VERSION ""

NS_ :

BS_:

BU_: RLPSU DPSU APSU PSB SHVU_RR vHS_B2 FCS EMCU SLB RCM CGW_CCU vDummy_HS_B ATS RLHV PFSU SGU ALBCU DSAU SWRC SHVU_FR RCS RRPSU BLTN_CAM SCM DLBCU OHCL RWPC RRHV WPC HOD ASAU

BO_ 1041 ICU_02_200ms: 8 CGW_CCU
 SG_ ICU_Crc2Val : 0|8@1+ (1,0) [0|0] ""  Vector__XXX
 SG_ ICU_MtGearPosRSta : 10|2@1+ (1,0) [0|0] ""  BLTN_CAM
 SG_ ICU_AlvCnt2Val : 12|4@1+ (1,0) [0|0] ""  Vector__XXX
 SG_ DoorLock_AsstDrUnLkSta : 22|2@1+ (1,0) [0|0] ""  Vector__XXX
 SG_ Warn_DrvDrSwSta : 24|2@1+ (1,0) [0|0] ""  WPC,RWPC,DPSU,BLTN_CAM
 SG_ DoorLock_DrvKeyUnLkSwSta : 26|2@1+ (1,0) [0|0] ""  Vector__XXX
 SG_ DoorLock_RrLftDrUnLkSta : 28|2@1+ (1,0) [0|0] ""  Vector__XXX
 SG_ DoorLock_RrRtDrUnLkSta : 30|2@1+ (1,0) [0|0] ""  Vector__XXX
 SG_ Warn_AsstDrSwSta : 34|2@1+ (1,0) [0|0] ""  WPC,RWPC,APSU,RLPSU,BLTN_CAM,ALBCU
 SG_ Warn_AsstStBltSwSta : 36|2@1+ (1,0) [0|0] ""  PSB,APSU,RLPSU,ASAU,ALBCU
 SG_ Warn_BrkFldSwSta : 38|2@1+ (1,0) [0|0] ""  Vector__XXX
 SG_ DoorLock_DrvKeyLkSwSta : 40|2@1+ (1,0) [0|0] ""  Vector__XXX
 SG_ Warn_DrvStBltSwSta : 42|2@1+ (1,0) [0|0] ""  PSB,DPSU,DLBCU,ATS,DSAU,ASAU
 SG_ Warn_HoodSwSta : 44|2@1+ (1,0) [0|0] ""  BLTN_CAM
 SG_ Warn_PassStOccSta : 46|2@1+ (1,0) [0|0] ""  APSU
 SG_ Warn_PrkngBrkSwSta : 48|2@1+ (1,0) [0|0] ""  APSU,RLHV,RRHV,PFSU,RRPSU,RLPSU
 SG_ Warn_RrCtrStBltSwSta : 50|2@1+ (1,0) [0|0] ""  PSB
 SG_ Warn_RrLftDrSwSta : 52|2@1+ (1,0) [0|0] ""  WPC,RWPC,APSU,RLHV,RLPSU,BLTN_CAM
 SG_ Warn_RrLftStBltSwSta : 54|2@1+ (1,0) [0|0] ""  PSB,APSU,DPSU
 SG_ Warn_RrRtDrSwSta : 56|2@1+ (1,0) [0|0] ""  WPC,RWPC,APSU,RRHV,RRPSU,RLPSU,BLTN_CAM
 SG_ Warn_RrRtStBltSwSta : 58|2@1+ (1,0) [0|0] ""  PSB,APSU,DPSU,RRPSU
 SG_ Warn_HoodSwMemorySta : 60|2@1+ (1,0) [0|0] ""  Vector__XXX
 SG_ Warn_WshrFldSwSta : 62|2@1+ (1,0) [0|0] ""  Vector__XXX
 SG_ ICU_Haptic_OPT : 8|2@1+ (1,0) [0|0] ""  Vector__XXX

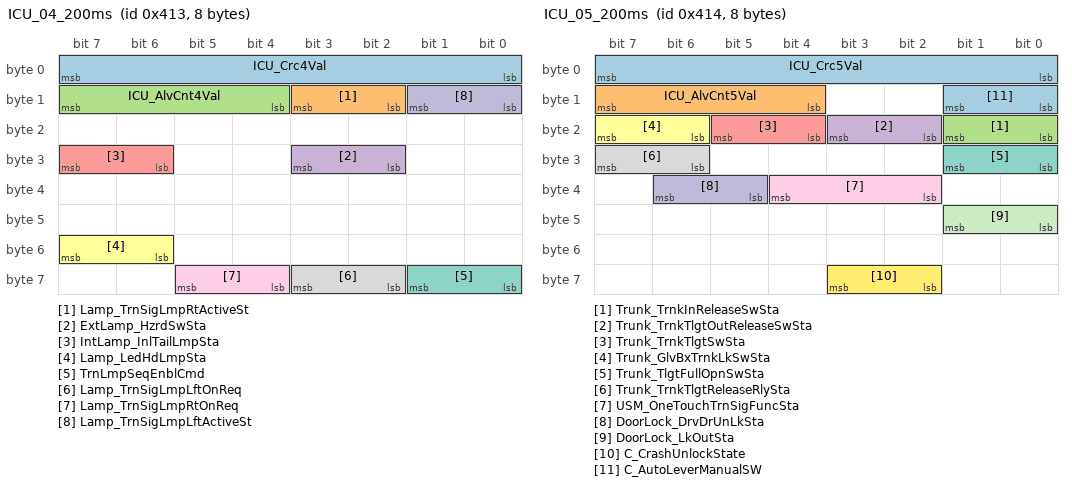
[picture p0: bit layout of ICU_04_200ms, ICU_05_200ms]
BO_ 1043 ICU_04_200ms: 8 CGW_CCU
 SG_ ICU_Crc4Val : 0|8@1+ (1,0) [0|0] ""  Vector__XXX
 SG_ Lamp_TrnSigLmpRtActiveSt : 10|2@1+ (1,0) [0|0] ""  Vector__XXX
 SG_ ICU_AlvCnt4Val : 12|4@1+ (1,0) [0|0] ""  Vector__XXX
 SG_ ExtLamp_HzrdSwSta : 26|2@1+ (1,0) [0|0] ""  Vector__XXX
 SG_ IntLamp_InlTailLmpSta : 30|2@1+ (1,0) [0|0] ""  SWRC,BLTN_CAM
 SG_ Lamp_LedHdLmpSta : 54|2@1+ (1,0) [0|0] ""  Vector__XXX
 SG_ TrnLmpSeqEnblCmd : 56|2@1+ (1,0) [0|0] ""  Vector__XXX
 SG_ Lamp_TrnSigLmpLftOnReq : 58|2@1+ (1,0) [0|0] ""  BLTN_CAM
 SG_ Lamp_TrnSigLmpRtOnReq : 60|2@1+ (1,0) [0|0] ""  BLTN_CAM
 SG_ Lamp_TrnSigLmpLftActiveSt : 8|2@1+ (1,0) [0|0] ""  Vector__XXX

BO_ 639 ATS_04_00ms: 8 ATS
 SG_ ATS_RRSeatHeaterSW : 0|2@1+ (1,0) [0|0] ""  RRHV,SHVU_RR
 SG_ ATS_RLSeatHeaterUpSW : 10|2@1+ (1,0) [0|0] ""  RLHV,SHVU_RR
 SG_ ATS_RRSeatVentDownSW : 12|2@1+ (1,0) [0|0] ""  RRHV,SHVU_RR
 SG_ ATS_RLSeatVentDownSW : 14|2@1+ (1,0) [0|0] ""  RLHV,SHVU_RR
 SG_ ATS_RLMemoryRestBtn : 16|2@1+ (1,0) [0|0] ""  Vector__XXX
 SG_ ATS_RLMemoryReturnBtn : 18|2@1+ (1,0) [0|0] ""  Vector__XXX
 SG_ ATS_RLSeatHeaterSW : 2|2@1+ (1,0) [0|0] ""  RLHV,SHVU_RR
 SG_ ATS_RRMemoryRestBtn : 20|2@1+ (1,0) [0|0] ""  Vector__XXX
 SG_ ATS_RRMemoryReturnBtn : 22|2@1+ (1,0) [0|0] ""  Vector__XXX
 SG_ ATS_RRMemoryAvWtcBtn : 24|2@1+ (1,0) [0|0] ""  Vector__XXX
 SG_ ATS_RRMemoryReadingBtn : 26|2@1+ (1,0) [0|0] ""  Vector__XXX
 SG_ ATS_RRRestModBtnSTD : 32|2@1+ (1,0) [0|0] ""  Vector__XXX
 SG_ ATS_RRResetModBtnSTD : 34|2@1+ (1,0) [0|0] ""  Vector__XXX
 SG_ ATS_RRAvWtcModBtnSTD : 36|2@1+ (1,0) [0|0] ""  Vector__XXX
 SG_ ATS_RRReadingModBtnSTD : 38|2@1+ (1,0) [0|0] ""  Vector__XXX
 SG_ ATS_RRSeatVentSW : 4|2@1+ (1,0) [0|0] ""  RRHV,SHVU_RR
 SG_ ATS_RLRestModBtnSTD : 40|2@1+ (1,0) [0|0] ""  Vector__XXX
 SG_ ATS_RLResetModBtnSTD : 42|2@1+ (1,0) [0|0] ""  Vector__XXX
 SG_ ATS_RRModestateStopBtn : 44|2@1+ (1,0) [0|0] ""  Vector__XXX
 SG_ ATS_RLModestateStopBtn : 46|2@1+ (1,0) [0|0] ""  Vector__XXX
 SG_ ATS_RLResetRestBtn : 48|2@1+ (1,0) [0|0] ""  Vector__XXX
 SG_ ATS_RLResetReturnBtn : 50|2@1+ (1,0) [0|0] ""  Vector__XXX
 SG_ ATS_RRResetRestBtn : 52|2@1+ (1,0) [0|0] ""  Vector__XXX
 SG_ ATS_RRResetReturnBtn : 54|2@1+ (1,0) [0|0] ""  Vector__XXX
 SG_ ATS_RRResetAvWtcBtn : 56|2@1+ (1,0) [0|0] ""  Vector__XXX
 SG_ ATS_RRResetReadingBtn : 58|2@1+ (1,0) [0|0] ""  Vector__XXX
 SG_ ATS_RLSeatVentSW : 6|2@1+ (1,0) [0|0] ""  RLHV,SHVU_RR
 SG_ ATS_RRSeatHeaterUpSW : 8|2@1+ (1,0) [0|0] ""  RRHV,SHVU_RR

BO_ 1044 ICU_05_200ms: 8 CGW_CCU
 SG_ ICU_Crc5Val : 0|8@1+ (1,0) [0|0] ""  Vector__XXX
 SG_ ICU_AlvCnt5Val : 12|4@1+ (1,0) [0|0] ""  Vector__XXX
 SG_ Trunk_TrnkInReleaseSwSta : 16|2@1+ (1,0) [0|0] ""  Vector__XXX
 SG_ Trunk_TrnkTlgtOutReleaseSwSta : 18|2@1+ (1,0) [0|0] ""  Vector__XXX
 SG_ Trunk_TrnkTlgtSwSta : 20|2@1+ (1,0) [0|0] ""  APSU,RLHV,RRHV,PFSU,RRPSU,RLPSU,BLTN_CAM
 SG_ Trunk_GlvBxTrnkLkSwSta : 22|2@1+ (1,0) [0|0] ""  Vector__XXX
 SG_ Trunk_TlgtFullOpnSwSta : 24|2@1+ (1,0) [0|0] ""  Vector__XXX
 SG_ Trunk_TrnkTlgtReleaseRlySta : 30|2@1+ (1,0) [0|0] ""  Vector__XXX
 SG_ USM_OneTouchTrnSigFuncSta : 34|3@1+ (1,0) [0|0] ""  Vector__XXX
 SG_ DoorLock_DrvDrUnLkSta : 37|2@1+ (1,0) [0|0] ""  Vector__XXX
 SG_ DoorLock_LkOutSta : 40|2@1+ (1,0) [0|0] ""  Vector__XXX
 SG_ C_CrashUnlockState : 58|2@1+ (1,0) [0|0] ""  BLTN_CAM
 SG_ C_AutoLeverManualSW : 8|2@1+ (1,0) [0|0] ""  Vector__XXX

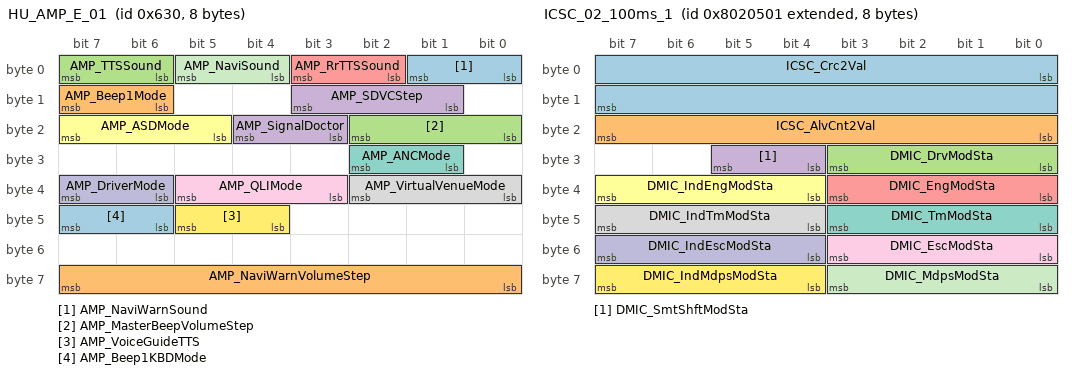
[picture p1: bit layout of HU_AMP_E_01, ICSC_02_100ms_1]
BO_ 1584 HU_AMP_E_01: 8 CGW_CCU
 SG_ AMP_NaviWarnSound : 0|2@1+ (1,0) [0|0] ""  Vector__XXX
 SG_ AMP_Beep1Mode : 14|2@1+ (1,0) [0|0] ""  ATS
 SG_ AMP_MasterBeepVolumeStep : 16|3@1+ (1,0) [0|0] ""  Vector__XXX
 SG_ AMP_SignalDoctor : 19|2@1+ (1,0) [0|0] ""  Vector__XXX
 SG_ AMP_RrTTSSound : 2|2@1+ (1,0) [0|0] ""  Vector__XXX
 SG_ AMP_ASDMode : 21|3@1+ (1,0) [0|0] ""  Vector__XXX
 SG_ AMP_ANCMode : 25|2@1+ (1,0) [0|0] ""  Vector__XXX
 SG_ AMP_VirtualVenueMode : 32|3@1+ (1,0) [0|0] ""  Vector__XXX
 SG_ AMP_QLIMode : 35|3@1+ (1,0) [0|0] ""  Vector__XXX
 SG_ AMP_DriverMode : 38|2@1+ (1,0) [0|0] ""  Vector__XXX
 SG_ AMP_NaviSound : 4|2@1+ (1,0) [0|0] ""  Vector__XXX
 SG_ AMP_VoiceGuideTTS : 44|2@1+ (1,0) [0|0] ""  Vector__XXX
 SG_ AMP_Beep1KBDMode : 46|2@1+ (1,0) [0|0] ""  Vector__XXX
 SG_ AMP_NaviWarnVolumeStep : 56|8@1+ (1,0) [0|0] ""  Vector__XXX
 SG_ AMP_TTSSound : 6|2@1+ (1,0) [0|0] ""  Vector__XXX
 SG_ AMP_SDVCStep : 9|3@1+ (1,0) [0|0] ""  Vector__XXX

BO_ 2281833729 ICSC_02_100ms_1: 8 CGW_CCU
 SG_ ICSC_Crc2Val : 0|16@1+ (1,0) [0|0] ""  Vector__XXX
 SG_ ICSC_AlvCnt2Val : 16|8@1+ (1,0) [0|0] ""  Vector__XXX
 SG_ DMIC_DrvModSta : 24|4@1+ (1,0) [0|0] ""  APSU,DLBCU,DSAU,ASAU,ALBCU
 SG_ DMIC_SmtShftModSta : 28|2@1+ (1,0) [0|0] ""  Vector__XXX
 SG_ DMIC_EngModSta : 32|4@1+ (1,0) [0|0] ""  Vector__XXX
 SG_ DMIC_IndEngModSta : 36|4@1+ (1,0) [0|0] ""  Vector__XXX
 SG_ DMIC_TmModSta : 40|4@1+ (1,0) [0|0] ""  Vector__XXX
 SG_ DMIC_IndTmModSta : 44|4@1+ (1,0) [0|0] ""  Vector__XXX
 SG_ DMIC_EscModSta : 48|4@1+ (1,0) [0|0] ""  Vector__XXX
 SG_ DMIC_IndEscModSta : 52|4@1+ (1,0) [0|0] ""  Vector__XXX
 SG_ DMIC_MdpsModSta : 56|4@1+ (1,0) [0|0] ""  Vector__XXX
 SG_ DMIC_IndMdpsModSta : 60|4@1+ (1,0) [0|0] ""  Vector__XXX

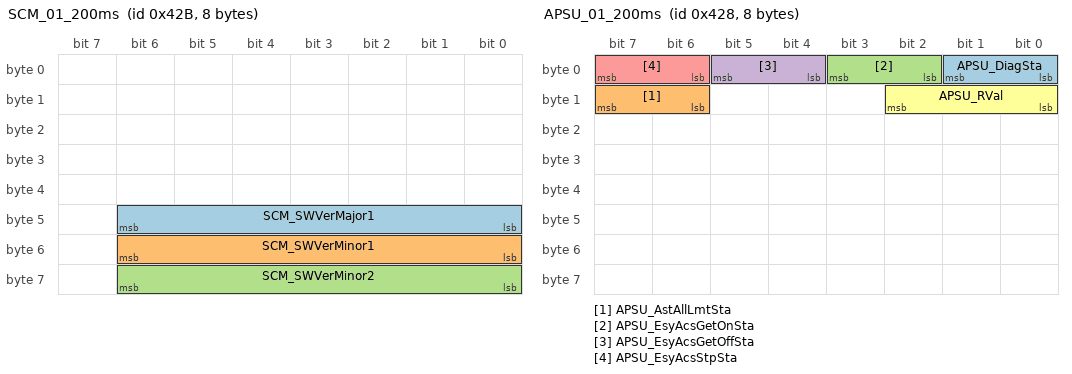
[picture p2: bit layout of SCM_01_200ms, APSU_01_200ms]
BO_ 1067 SCM_01_200ms: 8 SCM
 SG_ SCM_SWVerMajor1 : 40|7@1+ (1,0) [0|0] ""  CGW_CCU
 SG_ SCM_SWVerMinor1 : 48|7@1+ (1,0) [0|0] ""  CGW_CCU
 SG_ SCM_SWVerMinor2 : 56|7@1+ (1,0) [0|0] ""  CGW_CCU

BO_ 577 HU_APSU_PE_02: 8 CGW_CCU
 SG_ C_AstBolsterInfSw_HU : 0|2@1+ (1,0) [0|0] ""  ASAU,ALBCU
 SG_ C_RLHrestUpSw_HU : 14|2@1+ (1,0) [0|0] ""  APSU,RRPSU,RLPSU
 SG_ C_RLHrestDnSw_HU : 16|2@1+ (1,0) [0|0] ""  APSU,RRPSU,RLPSU
 SG_ C_RLHrestFwdSw_HU : 18|2@1+ (1,0) [0|0] ""  APSU,RRPSU,RLPSU
 SG_ C_AstBolsterDefSw_HU : 2|2@1+ (1,0) [0|0] ""  ASAU,ALBCU
 SG_ C_RLHrestBwdSw_HU : 20|2@1+ (1,0) [0|0] ""  APSU,RRPSU,RLPSU
 SG_ C_RLLumbarUpSw_HU : 22|2@1+ (1,0) [0|0] ""  RLPSU
 SG_ C_RLLumbarMidSw_HU : 24|2@1+ (1,0) [0|0] ""  RLPSU
 SG_ C_RLLumbarLowSw_HU : 26|2@1+ (1,0) [0|0] ""  RLPSU
 SG_ C_RLLumbarDefSw_HU : 28|2@1+ (1,0) [0|0] ""  RLPSU
 SG_ C_RLBolsterInfSw_HU : 30|2@1+ (1,0) [0|0] ""  RLPSU
 SG_ C_RLBolsterDefSw_HU : 32|2@1+ (1,0) [0|0] ""  RLPSU
 SG_ C_AstHrestUpSw_HU : 36|2@1+ (1,0) [0|0] ""  APSU
 SG_ C_AstHrestDnSw_HU : 38|2@1+ (1,0) [0|0] ""  APSU
 SG_ C_AstFootrestFldSw_HU : 4|2@1+ (1,0) [0|0] ""  APSU
 SG_ C_AstHrestFwdSw_HU : 46|2@1+ (1,0) [0|0] ""  APSU
 SG_ C_AstHrestBwdSw_HU : 54|2@1+ (1,0) [0|0] ""  APSU
 SG_ C_AstFootrestUnFldSw_HU : 6|2@1+ (1,0) [0|0] ""  APSU

BO_ 2281833731 ICSC_02_100ms_3: 8 CGW_CCU
 SG_ DMIC_VcuModSta : 0|4@1+ (1,0) [0|0] ""  Vector__XXX
 SG_ DMIC_DrvModTyp : 12|4@1+ (1,0) [0|0] ""  Vector__XXX
 SG_ DMIC_EngFltSta : 16|2@1+ (1,0) [0|0] ""  Vector__XXX
 SG_ DMIC_TmFltSta : 18|2@1+ (1,0) [0|0] ""  Vector__XXX
 SG_ DMIC_EscFltSta : 20|2@1+ (1,0) [0|0] ""  Vector__XXX
 SG_ DMIC_MdpsFltSta : 22|2@1+ (1,0) [0|0] ""  Vector__XXX
 SG_ DMIC_EcsFltSta : 24|2@1+ (1,0) [0|0] ""  Vector__XXX
 SG_ DMIC_AwdFltSta : 26|2@1+ (1,0) [0|0] ""  Vector__XXX
 SG_ DMIC_RevFltSta : 28|2@1+ (1,0) [0|0] ""  Vector__XXX
 SG_ DMIC_PrflFltSta : 30|2@1+ (1,0) [0|0] ""  Vector__XXX
 SG_ DMIC_ElsdFltSta : 32|2@1+ (1,0) [0|0] ""  Vector__XXX
 SG_ DMIC_EsndFltSta : 34|2@1+ (1,0) [0|0] ""  Vector__XXX
 SG_ DMIC_RwsFltSta : 36|2@1+ (1,0) [0|0] ""  Vector__XXX
 SG_ DMIC_IndWhlDrvSta : 38|2@1+ (1,0) [0|0] ""  Vector__XXX
 SG_ DMIC_IndVcuModSta : 4|4@1+ (1,0) [0|0] ""  Vector__XXX
 SG_ DMIC_VcuFltSta : 40|2@1+ (1,0) [0|0] ""  Vector__XXX
 SG_ DMIC_IndMtrPwrSta : 42|3@1+ (1,0) [0|0] ""  Vector__XXX
 SG_ DMIC_IndAccSenSta : 45|3@1+ (1,0) [0|0] ""  Vector__XXX
 SG_ DMIC_IndDecSenSta : 48|3@1+ (1,0) [0|0] ""  Vector__XXX
 SG_ DMIC_IndMaxVehSpdSta : 51|6@1+ (1,0) [0|0] ""  Vector__XXX
 SG_ DMIC_DrvMod2Typ : 60|4@1+ (1,0) [0|0] ""  Vector__XXX
 SG_ DMIC_DrvModFltSta : 8|4@1+ (1,0) [0|0] ""  Vector__XXX

BO_ 578 HU_APSU_PE_03: 8 CGW_CCU
 SG_ C_RRLegSupFwdSw_HU : 0|2@1+ (1,0) [0|0] ""  APSU,RRPSU,RLPSU
 SG_ C_RRHrestDnSw_HU : 10|2@1+ (1,0) [0|0] ""  APSU,RRPSU,RLPSU
 SG_ C_RRHrestFwdSw_HU : 12|2@1+ (1,0) [0|0] ""  APSU,RRPSU,RLPSU
 SG_ C_RRHrestBwdSw_HU : 14|2@1+ (1,0) [0|0] ""  APSU,RRPSU,RLPSU
 SG_ C_RRLumbarUpSw_HU : 16|2@1+ (1,0) [0|0] ""  APSU,RRPSU
 SG_ C_RRLumbarMidSw_HU : 18|2@1+ (1,0) [0|0] ""  APSU,RRPSU
 SG_ C_RRLegSupBwdSw_HU : 2|2@1+ (1,0) [0|0] ""  APSU,RRPSU,RLPSU
 SG_ C_RRLumbarLowSw_HU : 20|2@1+ (1,0) [0|0] ""  APSU,RRPSU
 SG_ C_RRLumbarDefSw_HU : 22|2@1+ (1,0) [0|0] ""  APSU,RRPSU
 SG_ C_RRBolsterInfSw_HU : 24|2@1+ (1,0) [0|0] ""  APSU,RRPSU
 SG_ C_RRLegSupUpSw_HU : 4|2@1+ (1,0) [0|0] ""  APSU,RRPSU,RLPSU
 SG_ C_RROneTchNValueSet : 40|3@1+ (1,0) [0|0] ""  APSU,RRPSU,RLPSU,ATS
 SG_ C_RLOneTchNValueSet : 43|3@1+ (1,0) [0|0] ""  APSU,RRPSU,RLPSU,ATS
 SG_ C_RRBolsterDefSw_HU : 46|2@1+ (1,0) [0|0] ""  APSU,RRPSU
 SG_ C_AstRlxTiltUpSw_HU : 50|2@1+ (1,0) [0|0] ""  APSU
 SG_ C_AstRlxTiltDnSw_HU : 52|2@1+ (1,0) [0|0] ""  APSU
 SG_ C_RLRSEUpSw_HU : 54|2@1+ (1,0) [0|0] ""  APSU,RRPSU,RLPSU
 SG_ C_RLRSEDnSw_HU : 56|2@1+ (1,0) [0|0] ""  APSU,RRPSU,RLPSU
 SG_ C_RRRSEUpSw_HU : 58|2@1+ (1,0) [0|0] ""  APSU,RRPSU,RLPSU
 SG_ C_RRLegSupDnSw_HU : 6|2@1+ (1,0) [0|0] ""  APSU,RRPSU,RLPSU
 SG_ C_RRRSEDnSw_HU : 60|2@1+ (1,0) [0|0] ""  APSU,RRPSU,RLPSU
 SG_ C_RRHrestUpSw_HU : 8|2@1+ (1,0) [0|0] ""  APSU,RRPSU,RLPSU

BO_ 1064 APSU_01_200ms: 8 APSU
 SG_ APSU_DiagSta : 0|2@1+ (1,0) [0|0] ""  Vector__XXX
 SG_ APSU_AstAllLmtSta : 14|2@1+ (1,0) [0|0] ""  RLPSU,RRPSU
 SG_ APSU_EsyAcsGetOnSta : 2|2@1+ (1,0) [0|0] ""  ALBCU
 SG_ APSU_EsyAcsGetOffSta : 4|2@1+ (1,0) [0|0] ""  ALBCU
 SG_ APSU_EsyAcsStpSta : 6|2@1+ (1,0) [0|0] ""  ALBCU
 SG_ APSU_RVal : 8|3@1+ (1,0) [0|0] ""  Vector__XXX

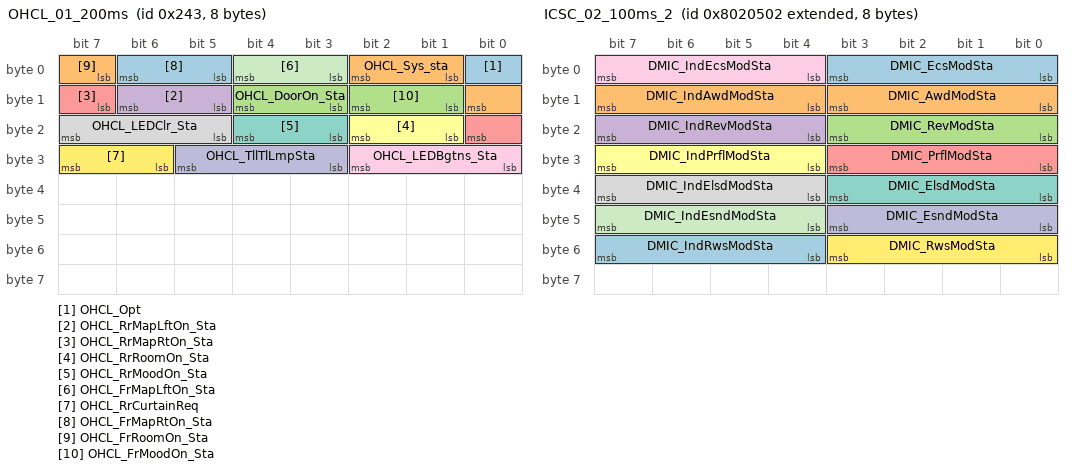
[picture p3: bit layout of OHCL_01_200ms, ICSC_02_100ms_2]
BO_ 579 OHCL_01_200ms: 8 OHCL
 SG_ OHCL_Opt : 0|1@1+ (1,0) [0|0] ""  ATS
 SG_ OHCL_Sys_sta : 1|2@1+ (1,0) [0|0] ""  ATS
 SG_ OHCL_DoorOn_Sta : 11|2@1+ (1,0) [0|0] ""  ATS
 SG_ OHCL_RrMapLftOn_Sta : 13|2@1+ (1,0) [0|0] ""  ATS
 SG_ OHCL_RrMapRtOn_Sta : 15|2@1+ (1,0) [0|0] ""  ATS
 SG_ OHCL_RrRoomOn_Sta : 17|2@1+ (1,0) [0|0] ""  ATS
 SG_ OHCL_RrMoodOn_Sta : 19|2@1+ (1,0) [0|0] ""  ATS
 SG_ OHCL_LEDClr_Sta : 21|3@1+ (1,0) [0|0] ""  ATS
 SG_ OHCL_LEDBgtns_Sta : 24|3@1+ (1,0) [0|0] ""  ATS
 SG_ OHCL_TllTlLmpSta : 27|3@1+ (1,0) [0|0] ""  CGW_CCU
 SG_ OHCL_FrMapLftOn_Sta : 3|2@1+ (1,0) [0|0] ""  ATS
 SG_ OHCL_RrCurtainReq : 30|2@1+ (1,0) [0|0] ""  Vector__XXX
 SG_ OHCL_FrMapRtOn_Sta : 5|2@1+ (1,0) [0|0] ""  ATS
 SG_ OHCL_FrRoomOn_Sta : 7|2@1+ (1,0) [0|0] ""  ATS
 SG_ OHCL_FrMoodOn_Sta : 9|2@1+ (1,0) [0|0] ""  ATS

BO_ 2281833730 ICSC_02_100ms_2: 8 CGW_CCU
 SG_ DMIC_EcsModSta : 0|4@1+ (1,0) [0|0] ""  Vector__XXX
 SG_ DMIC_IndAwdModSta : 12|4@1+ (1,0) [0|0] ""  Vector__XXX
 SG_ DMIC_RevModSta : 16|4@1+ (1,0) [0|0] ""  Vector__XXX
 SG_ DMIC_IndRevModSta : 20|4@1+ (1,0) [0|0] ""  Vector__XXX
 SG_ DMIC_PrflModSta : 24|4@1+ (1,0) [0|0] ""  Vector__XXX
 SG_ DMIC_IndPrflModSta : 28|4@1+ (1,0) [0|0] ""  Vector__XXX
 SG_ DMIC_ElsdModSta : 32|4@1+ (1,0) [0|0] ""  Vector__XXX
 SG_ DMIC_IndElsdModSta : 36|4@1+ (1,0) [0|0] ""  Vector__XXX
 SG_ DMIC_IndEcsModSta : 4|4@1+ (1,0) [0|0] ""  Vector__XXX
 SG_ DMIC_EsndModSta : 40|4@1+ (1,0) [0|0] ""  Vector__XXX
 SG_ DMIC_IndEsndModSta : 44|4@1+ (1,0) [0|0] ""  Vector__XXX
 SG_ DMIC_RwsModSta : 48|4@1+ (1,0) [0|0] ""  Vector__XXX
 SG_ DMIC_IndRwsModSta : 52|4@1+ (1,0) [0|0] ""  Vector__XXX
 SG_ DMIC_AwdModSta : 8|4@1+ (1,0) [0|0] ""  Vector__XXX

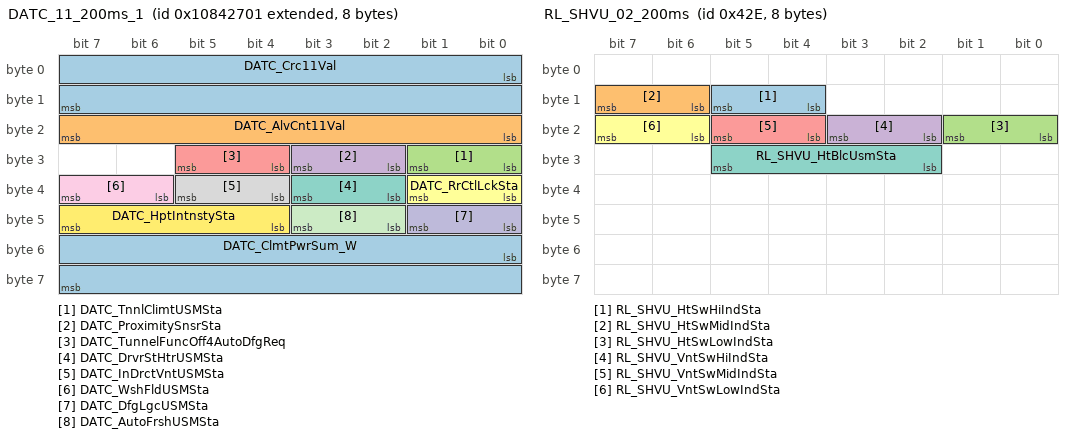
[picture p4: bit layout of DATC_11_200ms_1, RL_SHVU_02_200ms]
BO_ 2424579841 DATC_11_200ms_1: 8 CGW_CCU
 SG_ DATC_Crc11Val : 0|16@1+ (1,0) [0|0] ""  Vector__XXX
 SG_ DATC_AlvCnt11Val : 16|8@1+ (1,0) [0|0] ""  Vector__XXX
 SG_ DATC_TnnlClimtUSMSta : 24|2@1+ (1,0) [0|0] ""  Vector__XXX
 SG_ DATC_ProximitySnsrSta : 26|2@1+ (1,0) [0|0] ""  Vector__XXX
 SG_ DATC_TunnelFuncOff4AutoDfgReq : 28|2@1+ (1,0) [0|0] ""  Vector__XXX
 SG_ DATC_RrCtlLckSta : 32|2@1+ (1,0) [0|0] ""  ATS
 SG_ DATC_DrvrStHtrUSMSta : 34|2@1+ (1,0) [0|0] ""  APSU,DPSU
 SG_ DATC_InDrctVntUSMSta : 36|2@1+ (1,0) [0|0] ""  Vector__XXX
 SG_ DATC_WshFldUSMSta : 38|2@1+ (1,0) [0|0] ""  Vector__XXX
 SG_ DATC_DfgLgcUSMSta : 40|2@1+ (1,0) [0|0] ""  Vector__XXX
 SG_ DATC_AutoFrshUSMSta : 42|2@1+ (1,0) [0|0] ""  Vector__XXX
 SG_ DATC_HptIntnstySta : 44|4@1+ (1,0) [0|0] ""  Vector__XXX
 SG_ DATC_ClmtPwrSum_W : 48|16@1+ (1,0) [0|0] "Wh"  Vector__XXX

BO_ 1070 RL_SHVU_02_200ms: 8 RLPSU
 SG_ RL_SHVU_HtSwHiIndSta : 12|2@1+ (1,0) [0|0] ""  ATS,CGW_CCU
 SG_ RL_SHVU_HtSwMidIndSta : 14|2@1+ (1,0) [0|0] ""  ATS,CGW_CCU
 SG_ RL_SHVU_HtSwLowIndSta : 16|2@1+ (1,0) [0|0] ""  ATS,CGW_CCU
 SG_ RL_SHVU_VntSwHiIndSta : 18|2@1+ (1,0) [0|0] ""  ATS,CGW_CCU
 SG_ RL_SHVU_VntSwMidIndSta : 20|2@1+ (1,0) [0|0] ""  ATS,CGW_CCU
 SG_ RL_SHVU_VntSwLowIndSta : 22|2@1+ (1,0) [0|0] ""  ATS,CGW_CCU
 SG_ RL_SHVU_HtBlcUsmSta : 26|4@1+ (1,0) [0|0] ""  ATS,CGW_CCU,CGW_CCU

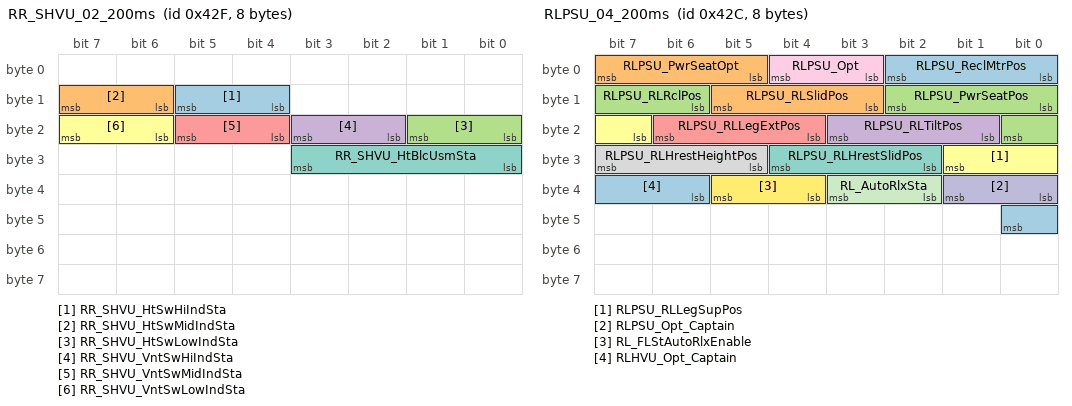
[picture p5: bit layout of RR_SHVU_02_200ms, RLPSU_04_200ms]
BO_ 1071 RR_SHVU_02_200ms: 8 SHVU_RR
 SG_ RR_SHVU_HtSwHiIndSta : 12|2@1+ (1,0) [0|0] ""  ATS,CGW_CCU
 SG_ RR_SHVU_HtSwMidIndSta : 14|2@1+ (1,0) [0|0] ""  ATS,CGW_CCU
 SG_ RR_SHVU_HtSwLowIndSta : 16|2@1+ (1,0) [0|0] ""  ATS,CGW_CCU
 SG_ RR_SHVU_VntSwHiIndSta : 18|2@1+ (1,0) [0|0] ""  ATS,CGW_CCU
 SG_ RR_SHVU_VntSwMidIndSta : 20|2@1+ (1,0) [0|0] ""  ATS,CGW_CCU
 SG_ RR_SHVU_VntSwLowIndSta : 22|2@1+ (1,0) [0|0] ""  ATS,CGW_CCU
 SG_ RR_SHVU_HtBlcUsmSta : 24|4@1+ (1,0) [0|0] ""  ATS,CGW_CCU,CGW_CCU

BO_ 1068 RLPSU_04_200ms: 8 RLHV
 SG_ RLPSU_ReclMtrPos : 0|3@1+ (1,0) [0|0] ""  PFSU,CGW_CCU
 SG_ RLPSU_RLSlidPos : 11|3@1+ (1,0) [0|0] ""  CGW_CCU
 SG_ RLPSU_RLRclPos : 14|3@1+ (1,0) [0|0] ""  CGW_CCU
 SG_ RLPSU_RLTiltPos : 17|3@1+ (1,0) [0|0] ""  CGW_CCU
 SG_ RLPSU_RLLegExtPos : 20|3@1+ (1,0) [0|0] ""  CGW_CCU
 SG_ RLPSU_RLLegSupPos : 23|3@1+ (1,0) [0|0] ""  CGW_CCU
 SG_ RLPSU_RLHrestSlidPos : 26|3@1+ (1,0) [0|0] ""  CGW_CCU
 SG_ RLPSU_RLHrestHeightPos : 29|3@1+ (1,0) [0|0] ""  CGW_CCU
 SG_ RLPSU_Opt : 3|2@1+ (1,0) [0|0] ""  CGW_CCU
 SG_ RLPSU_Opt_Captain : 32|2@1+ (1,0) [0|0] ""  CGW_CCU
 SG_ RL_AutoRlxSta : 34|2@1+ (1,0) [0|0] ""  APSU,DPSU
 SG_ RL_FLStAutoRlxEnable : 36|2@1+ (1,0) [0|0] ""  APSU,DPSU
 SG_ RLHVU_Opt_Captain : 38|3@1+ (1,0) [0|0] ""  CGW_CCU
 SG_ RLPSU_PwrSeatOpt : 5|3@1+ (1,0) [0|0] ""  CGW_CCU
 SG_ RLPSU_PwrSeatPos : 8|3@1+ (1,0) [0|0] ""  CGW_CCU

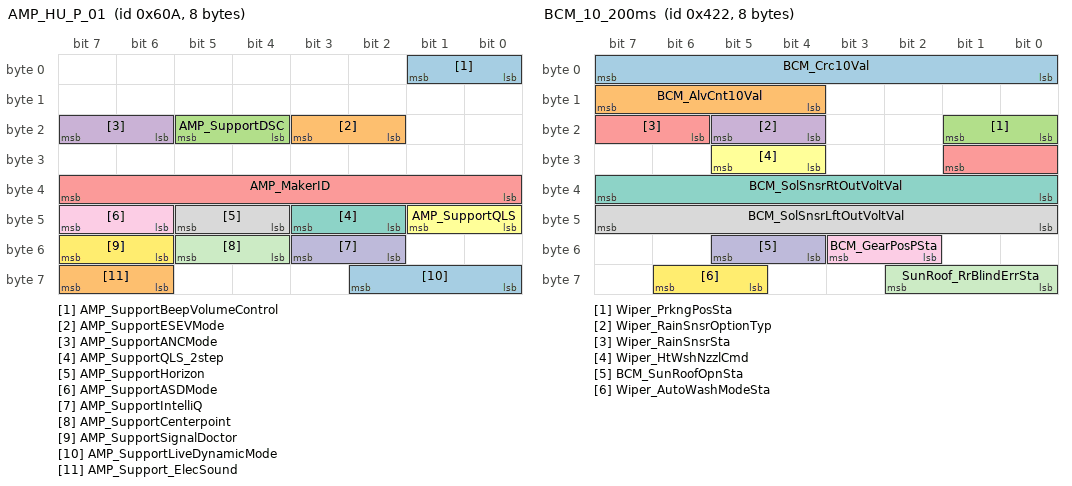
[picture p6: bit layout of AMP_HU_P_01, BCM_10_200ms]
BO_ 1546 AMP_HU_P_01: 8 CGW_CCU
 SG_ AMP_SupportBeepVolumeControl : 0|2@1+ (1,0) [0|0] ""  ATS
 SG_ AMP_SupportESEVMode : 18|2@1+ (1,0) [0|0] ""  Vector__XXX
 SG_ AMP_SupportDSC : 20|2@1+ (1,0) [0|0] ""  Vector__XXX
 SG_ AMP_SupportANCMode : 22|2@1+ (1,0) [0|0] ""  Vector__XXX
 SG_ AMP_MakerID : 32|8@1+ (1,0) [0|0] ""  Vector__XXX
 SG_ AMP_SupportQLS : 40|2@1+ (1,0) [0|0] ""  Vector__XXX
 SG_ AMP_SupportQLS_2step : 42|2@1+ (1,0) [0|0] ""  Vector__XXX
 SG_ AMP_SupportHorizon : 44|2@1+ (1,0) [0|0] ""  Vector__XXX
 SG_ AMP_SupportASDMode : 46|2@1+ (1,0) [0|0] ""  Vector__XXX
 SG_ AMP_SupportIntelliQ : 50|2@1+ (1,0) [0|0] ""  Vector__XXX
 SG_ AMP_SupportCenterpoint : 52|2@1+ (1,0) [0|0] ""  Vector__XXX
 SG_ AMP_SupportSignalDoctor : 54|2@1+ (1,0) [0|0] ""  Vector__XXX
 SG_ AMP_SupportLiveDynamicMode : 56|3@1+ (1,0) [0|0] ""  Vector__XXX
 SG_ AMP_Support_ElecSound : 62|2@1+ (1,0) [0|0] ""  Vector__XXX

BO_ 1069 RRPSU_04_200ms: 8 RRPSU
 SG_ RRPSU_ReclMtrPos : 0|3@1+ (1,0) [0|0] ""  PFSU,CGW_CCU
 SG_ RRPSU_PwrSeatOpt : 11|3@1+ (1,0) [0|0] ""  CGW_CCU
 SG_ RRPSU_PwrSeatPos : 14|3@1+ (1,0) [0|0] ""  CGW_CCU
 SG_ RRPSU_RRSlidPos : 17|3@1+ (1,0) [0|0] ""  CGW_CCU
 SG_ RRPSU_RRRclPos : 20|3@1+ (1,0) [0|0] ""  CGW_CCU
 SG_ RRPSU_RRTiltPos : 23|3@1+ (1,0) [0|0] ""  CGW_CCU
 SG_ RRPSU_RRLegExtPos : 26|3@1+ (1,0) [0|0] ""  CGW_CCU
 SG_ RRPSU_RRLegSupPos : 29|3@1+ (1,0) [0|0] ""  CGW_CCU
 SG_ RRPSU_RRStEsyAcsUSMSta : 3|3@1+ (1,0) [0|0] ""  CGW_CCU
 SG_ RRPSU_RRHrestSlidPos : 32|3@1+ (1,0) [0|0] ""  CGW_CCU
 SG_ RRPSU_RRHrestHeightPos : 35|3@1+ (1,0) [0|0] ""  CGW_CCU
 SG_ RRPSU_Opt_Captain : 38|2@1+ (1,0) [0|0] ""  CGW_CCU
 SG_ RR_AutoRlxSta : 40|2@1+ (1,0) [0|0] ""  APSU,DPSU
 SG_ RR_FRStAutoRlxEnable : 42|2@1+ (1,0) [0|0] ""  APSU,DPSU
 SG_ RRHVU_Opt_Captain : 44|3@1+ (1,0) [0|0] ""  CGW_CCU
 SG_ RRPSU_RLStEsyAcsUSMSta : 6|3@1+ (1,0) [0|0] ""  CGW_CCU
 SG_ RRPSU_Opt : 9|2@1+ (1,0) [0|0] ""  CGW_CCU

BO_ 1058 BCM_10_200ms: 8 CGW_CCU
 SG_ BCM_Crc10Val : 0|8@1+ (1,0) [0|0] ""  Vector__XXX
 SG_ BCM_AlvCnt10Val : 12|4@1+ (1,0) [0|0] ""  Vector__XXX
 SG_ Wiper_PrkngPosSta : 16|2@1+ (1,0) [0|0] ""  Vector__XXX
 SG_ Wiper_RainSnsrOptionTyp : 20|2@1+ (1,0) [0|0] ""  Vector__XXX
 SG_ Wiper_RainSnsrSta : 22|4@1+ (1,0) [0|0] ""  Vector__XXX
 SG_ Wiper_HtWshNzzlCmd : 28|2@1+ (1,0) [0|0] ""  Vector__XXX
 SG_ BCM_SolSnsrRtOutVoltVal : 32|8@1+ (4.72441,0) [0|0] ""  Vector__XXX
 SG_ BCM_SolSnsrLftOutVoltVal : 40|8@1+ (4.72441,0) [0|0] ""  Vector__XXX
 SG_ BCM_GearPosPSta : 50|2@1+ (1,0) [0|0] ""  SCM,APSU,RLHV,RRHV,DPSU,PFSU,RRPSU,RLPSU,ATS
 SG_ BCM_SunRoofOpnSta : 52|2@1+ (1,0) [0|0] ""  Vector__XXX
 SG_ SunRoof_RrBlindErrSta : 56|3@1+ (1,0) [0|0] ""  Vector__XXX
 SG_ Wiper_AutoWashModeSta : 61|2@1+ (1,0) [0|0] ""  Vector__XXX

BO_TX_BU_ 1070 : RLPSU,RLHV,SHVU_FR,SHVU_RR;
BO_TX_BU_ 1071 : SHVU_RR,RRHV,SHVU_FR,RRPSU;
BO_TX_BU_ 1068 : RLHV,RLPSU,RRPSU;
BO_TX_BU_ 1069 : RRPSU,RRHV;
CM_ BO_ 1546 "[P] Periodic";
CM_ SG_ 1546 AMP_SupportBeepVolumeControl "Information for AMPsupport configurable Beep1
send 500msec after Booting up";
CM_ SG_ 1546 AMP_SupportESEVMode "Information for AMP support ESEV(Engine Sound by Engine Vibration).";
CM_ SG_ 1546 AMP_SupportDSC "Does amp support Dynamic Speed Compensation mode?";
CM_ SG_ 1546 AMP_SupportANCMode "Does AMP support ANC?";
CM_ SG_ 1546 AMP_MakerID "Information for AMP Maker
For model afrer 2014, use 0x01~0x03 only.
* Use Only 0x01~0x03 values after 2014 *";
CM_ SG_ 1546 AMP_SupportQLS "Information for amp support Quantum Logic Surround mode
Harman AMP Only";
CM_ SG_ 1546 AMP_SupportQLS_2step "Information for amp support 2 Step Quantum Logic Surround mode Harman AMP Only";
CM_ SG_ 1546 AMP_SupportHorizon "Information for amp support Meridian Horizon mode Meridian AMP Only";
CM_ SG_ 1546 AMP_SupportASDMode "Information for  AMP support ASD (Active Sound Design, Virtual Engine Sound)";
CM_ SG_ 1546 AMP_SupportIntelliQ "Does amp support Meridian Intelli-Q mode?";
CM_ SG_ 1546 AMP_SupportCenterpoint "Does amp support CenterPoint mode?";
CM_ SG_ 1546 AMP_SupportSignalDoctor "Information for amp support SignalDoctor(=Clarifi)
Harman AMP Only";
CM_ SG_ 1546 AMP_SupportLiveDynamicMode "Information for amp
 Support
 LiveDynamic mode";
CM_ SG_ 1546 AMP_Support_ElecSound "inform to H/U & CLU whether amp support premium electric sound or not";
CM_ BO_ 1064 "[PE] Periodic and On Event";
CM_ SG_ 1064 APSU_DiagSta "APSU_DiagnosticStatus";
CM_ SG_ 1064 APSU_EsyAcsGetOnSta "APSU_EasyAccessGetOnStatus";
CM_ SG_ 1064 APSU_EsyAcsGetOffSta "APSU_EasyAccessGetOffStatus";
CM_ SG_ 1064 APSU_EsyAcsStpSta "APSU_EasyAccessStopStatus";
CM_ SG_ 1064 APSU_RVal "APSU_RValue";
CM_ BO_ 639 "[EC] On Event and On Change";
CM_ SG_ 639 ATS_RRSeatHeaterSW "ATS touch command for seat heat control (For Rear Right seat)";
CM_ SG_ 639 ATS_RLSeatHeaterUpSW "ATS touch command for seat heat control  (For Rear Left seat)";
CM_ SG_ 639 ATS_RRSeatVentDownSW "ATS touch command for seat Vent control (For Rear Right seat)";
CM_ SG_ 639 ATS_RLSeatVentDownSW "ATS touch command for seat Vent control (For Rear Left seat)";
CM_ SG_ 639 ATS_RLMemoryRestBtn "Rear Left Rest Mode Custom Save Button (Except North America)";
CM_ SG_ 639 ATS_RLMemoryReturnBtn "Rear Left Return Mode Custom Save Button (Except North America)";
CM_ SG_ 639 ATS_RLSeatHeaterSW "ATS touch command for seat heat control  (For Rear Left seat)";
CM_ SG_ 639 ATS_RRMemoryRestBtn "Rear Right Rest Mode Custom Save Button (Except North America)";
CM_ SG_ 639 ATS_RRMemoryReturnBtn "Rear Right Return Mode Custom Save Button (Except North America)";
CM_ SG_ 639 ATS_RRMemoryAvWtcBtn "Rear Right AV Watching Mode Custom Save Button (Except North America)";
CM_ SG_ 639 ATS_RRMemoryReadingBtn "Rear Right Reading Mode Custom Save Button (Except North America)";
CM_ SG_ 639 ATS_RRRestModBtnSTD "Rear Right Rest Mode Touch Button (EXCEPT North America)";
CM_ SG_ 639 ATS_RRResetModBtnSTD "Rear Right Return Mode Touch Button (EXCEPT North America)";
CM_ SG_ 639 ATS_RRAvWtcModBtnSTD "Rear Right AV Watching Mode Touch Button (EXCEPT North America)";
CM_ SG_ 639 ATS_RRReadingModBtnSTD "Rear Right Reading Mode Touch Button (EXCEPT North America)";
CM_ SG_ 639 ATS_RRSeatVentSW "ATS touch command for seat Vent control (For Rear Right seat)";
CM_ SG_ 639 ATS_RLRestModBtnSTD "Rear Left Rest Mode Touch Button (EXCEPT North America)";
CM_ SG_ 639 ATS_RLResetModBtnSTD "Rear Left Return Mode Touch Button (EXCEPT North America)";
CM_ SG_ 639 ATS_RRModestateStopBtn "Rear Right One touch mode Stop Button";
CM_ SG_ 639 ATS_RLModestateStopBtn "Rear Left One touch mode Stop Button";
CM_ SG_ 639 ATS_RLResetRestBtn "Rear Left Rest Mode Custom Initialization Button (Except North America)";
CM_ SG_ 639 ATS_RLResetReturnBtn "Rear Left Return Mode Custom Initialization Button (Except North America)";
CM_ SG_ 639 ATS_RRResetRestBtn "Rear Right Rest Mode Custom Initialization Button (Except North America)";
CM_ SG_ 639 ATS_RRResetReturnBtn "Rear Right Return Mode Custom Initialization Button (Except North America)";
CM_ SG_ 639 ATS_RRResetAvWtcBtn "Rear Right AV Watching Mode Custom Initialization Button (Except North America)";
CM_ SG_ 639 ATS_RRResetReadingBtn "Rear Right Reading Mode Custom Initialization Button (Except North America)";
CM_ SG_ 639 ATS_RLSeatVentSW "ATS touch command for seat Vent control (For Rear Left seat)";
CM_ SG_ 639 ATS_RRSeatHeaterUpSW "ATS touch command for seat heat control  (For Rear Right seat)";
CM_ BO_ 1058 "[PE] Periodic and On Event";
CM_ SG_ 1058 BCM_Crc10Val "BCM_CyclicRedundancyCheck10Value";
CM_ SG_ 1058 BCM_AlvCnt10Val "BCM_AliveCounter10Value";
CM_ SG_ 1058 Wiper_PrkngPosSta "Wiper_ParkingPositionStatus ##2G##BCM - BCMmsg22 - C_WiperParkPosition";
CM_ SG_ 1058 Wiper_RainSnsrOptionTyp "Wiper_RainSensorOptionType ##2G##BCM - BCMmsg24 - C_RainSnsOption";
CM_ SG_ 1058 Wiper_RainSnsrSta "Wiper_RainSensorStatus ##2G##BCM - BCMmsg24 - C_RainSnsState";
CM_ SG_ 1058 BCM_SolSnsrRtOutVoltVal "BCM_SolarSensorRightOutputVoltageValue ##2G##BCM - BCMmsg24 - C_PhotosensorRH";
CM_ SG_ 1058 BCM_SolSnsrLftOutVoltVal "BCM_SolarSensorLeftOutputVoltageValue ##2G##BCM - BCMmsg24 - C_PhotosensorLH";
CM_ SG_ 1058 BCM_GearPosPSta "BCM_GearPositionPStatus ##2G##BCM - BCMmsg17 - C_PpositiOn";
CM_ SG_ 1058 BCM_SunRoofOpnSta "BCM_SunRoofOpenStatus ##2G##BCM - BCMmsg20 - C_SunRoofOpenState";
CM_ SG_ 1058 Wiper_AutoWashModeSta "Auto Wash Mode Wiper State";
CM_ BO_ 2424579841 "[PE] Periodic and On Event";
CM_ SG_ 2424579841 DATC_Crc11Val "DATC_CyclicRedundancyCheck11Value";
CM_ SG_ 2424579841 DATC_AlvCnt11Val "DATC_AliveCounter11Value";
CM_ SG_ 2424579841 DATC_TnnlClimtUSMSta "DATC_TunnelCLimateUSMState";
CM_ SG_ 2424579841 DATC_ProximitySnsrSta "DATC_ProximitySensorStatus";
CM_ SG_ 2424579841 DATC_TunnelFuncOff4AutoDfgReq "DATC_TunnelFunctionOffForAutoDefogRequest";
CM_ SG_ 2424579841 DATC_RrCtlLckSta "Datc_RearClimateControlLockStatus";
CM_ SG_ 2424579841 DATC_DrvrStHtrUSMSta "DATC_DriverSeatHeaterUSMStatus";
CM_ SG_ 2424579841 DATC_InDrctVntUSMSta "DATC_InDirectVent_USM_State";
CM_ SG_ 2424579841 DATC_WshFldUSMSta "DATC_WasherFulidUSMState";
CM_ SG_ 2424579841 DATC_DfgLgcUSMSta "DefLogic USM State";
CM_ SG_ 2424579841 DATC_AutoFrshUSMSta "Auto Fresh USM State";
CM_ SG_ 2424579841 DATC_HptIntnstySta "Haptic Intensity State";
CM_ SG_ 2424579841 DATC_ClmtPwrSum_W "accumulated energy consumption while driving(200ms)";
CM_ BO_ 1584 "[EC] On Event and On Change";
CM_ SG_ 1584 AMP_NaviWarnSound "Navi Warning prompt on/off";
CM_ SG_ 1584 AMP_Beep1Mode "Play touch beep sound one time
Beep1 mode on/off
For Harman AMP
Default : Off
Goes On when play beep sound
-This Signal's Feedback is AMP_Beep1ModeState(0x180)@AMP";
CM_ SG_ 1584 AMP_SignalDoctor "Command for Turn SignalDoctor(= Clarifi, Vitual high quality sound function) ON/OFF
Harman AMP Only
Current name is Clarifi";
CM_ SG_ 1584 AMP_RrTTSSound "Rear TTS prompt on/offOnly ON during the Rear TTS Sound Playing Default : Off-This Signal's Feedback is AMP_RrTTSModeState(0x60c)@AMP";
CM_ SG_ 1584 AMP_ASDMode "ASD Set Mode Value";
CM_ SG_ 1584 AMP_ANCMode "Signal for setting ANC On/Off";
CM_ SG_ 1584 AMP_NaviSound "Navi prompt on/off
Only ON during the Navi Guide Sound Playing
Default : Off
-This Signal's Feedback is AMP_NaviModeState(0x180)@AMP";
CM_ SG_ 1584 AMP_Beep1KBDMode "Play touch beep sound at keyboard screen on AVN-This Signal's Feedback is AMP_Beep1KBDModeState@AMP";
CM_ SG_ 1584 AMP_NaviWarnVolumeStep "- Command for Navigation Warning Prompt Volume Setting";
CM_ SG_ 1584 AMP_TTSSound "TTS prompt on/offOnly ON during the TTS Sound Playing Default : Off-This Signal's Feedback is AMP_TTSModeState(0x60c)@AMP";
CM_ SG_ 1584 AMP_SDVCStep "SDVC(Speed Dependant Volume Control = VSC) 
Step4 : off, low, mid, high";
CM_ BO_ 577 "[PE] Periodic and On Event";
CM_ SG_ 577 C_AstBolsterInfSw_HU "Assistant seat moving switch: Bolster Inflate";
CM_ SG_ 577 C_RLHrestUpSw_HU "2nd Left side seat Moving control : Headrest Up";
CM_ SG_ 577 C_RLHrestDnSw_HU "2nd Left side seat Moving control : Headrest Down";
CM_ SG_ 577 C_RLHrestFwdSw_HU "2nd Left side seat Moving control : Headrest Forward";
CM_ SG_ 577 C_AstBolsterDefSw_HU "Assistant seat moving switch: Bolster Deflate";
CM_ SG_ 577 C_RLHrestBwdSw_HU "2nd Left side seat Moving control : Headrest Backward";
CM_ SG_ 577 C_RLLumbarUpSw_HU "2nd Left side seat Moving control : Lumbar Up";
CM_ SG_ 577 C_RLLumbarMidSw_HU "2nd Left side seat Moving control : Lumbar Mid";
CM_ SG_ 577 C_RLLumbarLowSw_HU "2nd Left side seat Moving control : Lumbar Low";
CM_ SG_ 577 C_RLLumbarDefSw_HU "2nd Left side seat Moving control : Lumbar Deflate";
CM_ SG_ 577 C_RLBolsterInfSw_HU "2nd Left side seat Moving control : Bolster Inflate";
CM_ SG_ 577 C_RLBolsterDefSw_HU "2nd Left side seat Moving control : Bolster Deflate";
CM_ SG_ 577 C_AstHrestUpSw_HU "Assistant seat moving switch : Headrest Up";
CM_ SG_ 577 C_AstHrestDnSw_HU "Assistant seat Moving control : Headrest Down";
CM_ SG_ 577 C_AstFootrestFldSw_HU "Assistant seat moving switch: Footrest Fold";
CM_ SG_ 577 C_AstHrestFwdSw_HU "Assistant seat Moving control : Headrest Forward";
CM_ SG_ 577 C_AstHrestBwdSw_HU "Assistant seat moving switch : Headrest Backward";
CM_ SG_ 577 C_AstFootrestUnFldSw_HU "Assistant seat moving switch: Footrest Unfold";
CM_ BO_ 578 "[PE] Periodic and On Event";
CM_ SG_ 578 C_RRLegSupFwdSw_HU "2nd Right side seat Moving control : Leg Support Forward";
CM_ SG_ 578 C_RRHrestDnSw_HU "2nd Right side seat Moving control : Headrest Down";
CM_ SG_ 578 C_RRHrestFwdSw_HU "2nd Right side seat Moving control : Headrest Forward";
CM_ SG_ 578 C_RRHrestBwdSw_HU "2nd Right side seat Moving control : Headrest Backward";
CM_ SG_ 578 C_RRLumbarUpSw_HU "2nd Right side seat Moving control : Lumbar Up";
CM_ SG_ 578 C_RRLumbarMidSw_HU "2nd Right side seat Moving control : Lumbar Mid";
CM_ SG_ 578 C_RRLegSupBwdSw_HU "2nd Right side seat Moving control : Leg Support Backward";
CM_ SG_ 578 C_RRLumbarLowSw_HU "2nd Right side seat Moving control : Lumbar Low";
CM_ SG_ 578 C_RRLumbarDefSw_HU "2nd Right side seat Moving control : Lumbar Deflate";
CM_ SG_ 578 C_RRBolsterInfSw_HU "2nd Right side seat Moving control : Bolster Inflate";
CM_ SG_ 578 C_RRLegSupUpSw_HU "2nd Right side seat Moving control : Leg Support Up";
CM_ SG_ 578 C_RROneTchNValueSet "2nd Right side seat One Touch Mode";
CM_ SG_ 578 C_RLOneTchNValueSet "2nd Left side seat One Touch Mode";
CM_ SG_ 578 C_RRBolsterDefSw_HU "2nd Right side seat Moving control : Bolster Deflate";
CM_ SG_ 578 C_AstRlxTiltUpSw_HU "Assistant seat Moving control : Relaxtion Tilt Up";
CM_ SG_ 578 C_AstRlxTiltDnSw_HU "Assistant seat Moving control : Relaxtion Tilt Down";
CM_ SG_ 578 C_RLRSEUpSw_HU "2nd Left side seat Moving control : RSE Up";
CM_ SG_ 578 C_RLRSEDnSw_HU "2nd Left side seat Moving control : RSE Down";
CM_ SG_ 578 C_RRRSEUpSw_HU "2nd Right side seat Moving control : RSE Up";
CM_ SG_ 578 C_RRLegSupDnSw_HU "2nd Right side seat Moving control : Leg Support Down";
CM_ SG_ 578 C_RRRSEDnSw_HU "2nd Right side seat Moving control : RSE Down";
CM_ SG_ 578 C_RRHrestUpSw_HU "2nd Right side seat Moving control : Headrest Up";
CM_ BO_ 2281833729 "[P] Periodic";
CM_ SG_ 2281833729 ICSC_Crc2Val "ICSC_CyclicRedundancyCheck2Value";
CM_ SG_ 2281833729 ICSC_AlvCnt2Val "ICSC_AliveCounter2Value";
CM_ SG_ 2281833729 DMIC_DrvModSta "DMIC_DriveModeStatus ##2G##ICSC - IVSS11 - DrivingModeState";
CM_ SG_ 2281833729 DMIC_SmtShftModSta "DMIC_SmartShiftModeStatus ##2G##ICSC - IVSS11 - SMART_SHIFT_MODE";
CM_ SG_ 2281833729 DMIC_EngModSta "DMIC_EngineModeStatus ##2G##ICSC - IVSS11 - MODE_ENG";
CM_ SG_ 2281833729 DMIC_IndEngModSta "DMIC_IndividualEngineModeStatus ##2G##ICSC - IVSS11 - MODE_PT_IND";
CM_ SG_ 2281833729 DMIC_TmModSta "DMIC_TmModeStatus ##2G##ICSC - IVSS11 - MODE_TM";
CM_ SG_ 2281833729 DMIC_IndTmModSta "DMIC_IndividualTmModeStatus";
CM_ SG_ 2281833729 DMIC_EscModSta "DMIC_EscModeStatus ##2G##ICSC - IVSS11 - MODE_ESC";
CM_ SG_ 2281833729 DMIC_IndEscModSta "DMIC_IndividualEscModeStatus ##2G##ICSC - IVSS11 - MODE_ESC_IND";
CM_ SG_ 2281833729 DMIC_MdpsModSta "DMIC_MdpsModeStatus ##2G##ICSC - IVSS11 - MODE_MDPS";
CM_ SG_ 2281833729 DMIC_IndMdpsModSta "DMIC_IndividualMdpsModeStatus ##2G##ICSC - IVSS11 - MODE_MDPS_IND";
CM_ BO_ 2281833730 "[P] Periodic";
CM_ SG_ 2281833730 DMIC_EcsModSta "DMIC_EcsModeStatus ##2G##ICSC - IVSS11 - MODE_ECS";
CM_ SG_ 2281833730 DMIC_IndAwdModSta "DMIC_IndividualAwdModeStatus ##2G##ICSC - IVSS11 - MODE_4WD_IND";
CM_ SG_ 2281833730 DMIC_RevModSta "DMIC_RevModeStatus ##2G##ICSC - IVSS11 - MODE_REV";
CM_ SG_ 2281833730 DMIC_IndRevModSta "DMIC_IndividualRevModeStatus ##2G##ICSC - IVSS11 - MODE_REV_IND";
CM_ SG_ 2281833730 DMIC_PrflModSta "DMIC_PrflModeStatus ##2G##ICSC - IVSS11 - MODE_PRFL";
CM_ SG_ 2281833730 DMIC_IndPrflModSta "DMIC_IndividualPrflModeStatus ##2G##ICSC - IVSS11 - MODE_PRFL_IND";
CM_ SG_ 2281833730 DMIC_ElsdModSta "DMIC_ElsdModeStatus ##2G##ICSC - IVSS11 - MODE_ELSD";
CM_ SG_ 2281833730 DMIC_IndElsdModSta "DMIC_IndividualElsdModeStatus ##2G##ICSC - IVSS11 - MODE_ELSD_IND";
CM_ SG_ 2281833730 DMIC_IndEcsModSta "DMIC_IndividualEcsModeStatus ##2G##ICSC - IVSS11 - MODE_ECS_IND";
CM_ SG_ 2281833730 DMIC_EsndModSta "DMIC_EsndModeStatus ##2G##ICSC - IVSS11 - MODE_ESND";
CM_ SG_ 2281833730 DMIC_IndEsndModSta "DMIC_IndividualEsndModeStatus ##2G##ICSC - IVSS11 - MODE_ESND_IND";
CM_ SG_ 2281833730 DMIC_RwsModSta "DMIC_RwsModeStatus";
CM_ SG_ 2281833730 DMIC_IndRwsModSta "DMIC_IndividualRwsModeStatus";
CM_ SG_ 2281833730 DMIC_AwdModSta "DMIC_AwdModeStatus ##2G##ICSC - IVSS11 - MODE_4WD";
CM_ BO_ 2281833731 "[P] Periodic";
CM_ SG_ 2281833731 DMIC_VcuModSta "VCU: DMIC_VcuModeStatus like a #2G# IVSS11-MODE_ENG";
CM_ SG_ 2281833731 DMIC_DrvModTyp "DMIC_DriveModeType ##2G##ICSC - IVSS11 - DRIVE_MODE_TYPE";
CM_ SG_ 2281833731 DMIC_EngFltSta "DMIC_EngineFaultStatus ##2G##ICSC - IVSS11 - MODE_ENG_FltStat";
CM_ SG_ 2281833731 DMIC_TmFltSta "DMIC_TransmissionFaultStatus ##2G##ICSC - IVSS11 - MODE_TM_FltStat";
CM_ SG_ 2281833731 DMIC_EscFltSta "DMIC_EscFaultStatus ##2G##ICSC - IVSS11 - MODE_ESC_FltStat";
CM_ SG_ 2281833731 DMIC_MdpsFltSta "DMIC_MdpsFaultStatus ##2G##ICSC - IVSS11 - MODE_MDPS_FltStat";
CM_ SG_ 2281833731 DMIC_EcsFltSta "DMIC_EcsFltSta ##2G##ICSC - IVSS11 - MODE_ECS_FltStat";
CM_ SG_ 2281833731 DMIC_AwdFltSta "DMIC_AwdFaultStatus ##2G##ICSC - IVSS11 - MODE_4WD_FltStat";
CM_ SG_ 2281833731 DMIC_RevFltSta "DMIC_RevFaultStatus ##2G##ICSC - IVSS11 - MODE_REV_FltStat";
CM_ SG_ 2281833731 DMIC_PrflFltSta "DMIC_PrefillFaultStatus ##2G##ICSC - IVSS11 - MODE_PRFL_FltStat";
CM_ SG_ 2281833731 DMIC_ElsdFltSta "DMIC_ElsdFaultStatus ##2G##ICSC - IVSS11 - MODE_ELSD_FltStat";
CM_ SG_ 2281833731 DMIC_EsndFltSta "DMIC_EsndFaultStatus ##2G##ICSC - IVSS11 - MODE_ENSD_FltStat";
CM_ SG_ 2281833731 DMIC_RwsFltSta "DMIC_RwsFaultStatus";
CM_ SG_ 2281833731 DMIC_IndVcuModSta "VCU: DMIC_IndividualVcuModeStatus like a #2G# IVSS11-MODE_ENG_IND";
CM_ SG_ 2281833731 DMIC_VcuFltSta "VCU: DMIC_VcuFaultStatus like a ##2G##ICSC - IVSS11 - MODE_ENG_FltStat";
CM_ SG_ 2281833731 DMIC_DrvMod2Typ "DMIC_DriveModeType2 ##2G##ICSC - IVSS11 - DRIVE_MODE_TYPE";
CM_ SG_ 2281833731 DMIC_DrvModFltSta "DMIC_DriveModeFaultStatus ##2G##ICSC - IVSS11 - MODE_DRIVING_FltStat";
CM_ BO_ 1041 "[PE] Periodic and On Event";
CM_ SG_ 1041 ICU_Crc2Val "ICU_CyclicRedundancyCheck2Value";
CM_ SG_ 1041 ICU_MtGearPosRSta "##2G## -  - C_InhibitRMT,CF_Gway_InhibitRMT";
CM_ SG_ 1041 ICU_AlvCnt2Val "ICU_AliveCounter2Value";
CM_ SG_ 1041 DoorLock_AsstDrUnLkSta "DoorLock_AssistDoorUnLockStatus ##2G## -  - C_AstUnlockState,DoorLock_AsstDrUnLkSta";
CM_ SG_ 1041 Warn_DrvDrSwSta "DoorLock_DriverDoorSwitchStatus ##2G## -  - C_DrvDrSw,CF_Gway_DrvDrSw,Warn_DrvDrSwSta";
CM_ SG_ 1041 DoorLock_DrvKeyUnLkSwSta "DoorLock_DriverKeyUnLockSwitchStatus ##2G## -  - C_DrvKeyUnlockSw";
CM_ SG_ 1041 DoorLock_RrLftDrUnLkSta "DoorLock_RearLeftDoorUnLockStatus ##2G## -  - C_RLUnlockState,DoorLock_RrLftDrUnLkSta";
CM_ SG_ 1041 DoorLock_RrRtDrUnLkSta "DoorLock_RearRightDoorUnLockStatus ##2G## -  - C_RRUnlockState,DoorLock_RrRtDrUnLkSta";
CM_ SG_ 1041 Warn_AsstDrSwSta "Warn_AssistDoorSwitchStatus ##2G## -  - C_AstDrSw,CF_Gway_AstDrSw,Warn_AsstDrSwSta";
CM_ SG_ 1041 Warn_AsstStBltSwSta "Warn_AssistSeatBeltSwitchStatus ##2G## -  - C_AstSeatBeltSw,CF_Gway_AstSeatBeltSw";
CM_ SG_ 1041 Warn_BrkFldSwSta "Warn_BrakeFluidSwitchStatus ##2G## -  - C_BrakeFluidSw,CF_Gway_BrakeFluidSw";
CM_ SG_ 1041 DoorLock_DrvKeyLkSwSta "DoorLock_DriverKeyLockSwitchStatus ##2G## -  - C_DrvKeyLockSw";
CM_ SG_ 1041 Warn_DrvStBltSwSta "Warn_DriverSeatbeltSwitchStatus ##2G## -  - C_DrvSeatBeltSw,CF_Gway_DrvSeatBeltSw";
CM_ SG_ 1041 Warn_HoodSwSta "Warn_HoodSwitchStatus ##2G## -  - C_HoodSw,CF_Gway_HoodSw";
CM_ SG_ 1041 Warn_PassStOccSta "Warn_PassengerSeatOccupyStatus ##2G## -  - C_SBRMatSw";
CM_ SG_ 1041 Warn_PrkngBrkSwSta "Warn_ParkingBrakeSwitchStatus ##2G## -  - C_ParkBrakeSw";
CM_ SG_ 1041 Warn_RrCtrStBltSwSta "Warn_RearCenterSeatBeltSwitchStatus ##2G## -  - C_RCSeatBeltSw";
CM_ SG_ 1041 Warn_RrLftDrSwSta "Warn_RearLeftDoorSwitchStatus ##2G## -  - C_RLDrSw,CF_Gway_RLDrSw,Warn_RrLftDrSwSta";
CM_ SG_ 1041 Warn_RrLftStBltSwSta "Warn_RearLeftSeatBeltSwitchStatus ##2G## -  - C_RLSeatBeltSw";
CM_ SG_ 1041 Warn_RrRtDrSwSta "Warn_RearRightDoorSwitchStatus ##2G## -  - C_RRDrSw,CF_Gway_RRDrSw,Warn_RrRtDrSwSta";
CM_ SG_ 1041 Warn_RrRtStBltSwSta "Warn_RearRightSeatBeltSwitchStatus ##2G## -  - C_RRSeatBeltSw";
CM_ SG_ 1041 Warn_HoodSwMemorySta "Warn_HoodSwitchMemoryStatus ##2G## -  - CF_Hoodsw_memory,C_HoodSwMemory";
CM_ SG_ 1041 Warn_WshrFldSwSta "Washer Fluid Switch Signal ##2G## -  - CF_Gway_WasherFluidSw";
CM_ SG_ 1041 ICU_Haptic_OPT "Steering Wheel Haptic Warning Option Infomation ##2G## -  - C_ICU_Haptic_OPT";
CM_ BO_ 1043 "[PE] Periodic and On Event";
CM_ SG_ 1043 ICU_Crc4Val "ICU_CyclicRedundancyCheck4Value";
CM_ SG_ 1043 Lamp_TrnSigLmpRtActiveSt "Lamp_TurnSignalLampRightActiveState";
CM_ SG_ 1043 ICU_AlvCnt4Val "ICU_AliveCounter4Value";
CM_ SG_ 1043 ExtLamp_HzrdSwSta "ExtLamp_HazardSwitchStatus ##2G## -  - C_HazardSw,CF_Gway_HazardSw";
CM_ SG_ 1043 IntLamp_InlTailLmpSta "IntLamp_InternalTailLampStatus ##2G## -  - C_IntTailAct,CF_Gway_IntTailAct";
CM_ SG_ 1043 Lamp_LedHdLmpSta "Lamp_LedHeadLampStatus ##2G## -  - CF_Afs_LedHLStat";
CM_ SG_ 1043 Lamp_TrnSigLmpLftOnReq "Lamp_TurnSignalLampLeftOnRequest ##2G## -  - Lamp_TsigLmpFrtLftOnReq";
CM_ SG_ 1043 Lamp_TrnSigLmpRtOnReq "Lamp_TurnSignalLampRightOnRequest ##2G## -  - Lamp_TSigLmpRtLftOnReq";
CM_ SG_ 1043 Lamp_TrnSigLmpLftActiveSt "Lamp_TurnSignalLampLeftActiveState";
CM_ BO_ 1044 "[PE] Periodic and On Event";
CM_ SG_ 1044 ICU_Crc5Val "ICU_CyclicRedundancyCheck5Value";
CM_ SG_ 1044 ICU_AlvCnt5Val "ICU_AliveCounter5Value";
CM_ SG_ 1044 Trunk_TrnkInReleaseSwSta "Trunk_TrunkInnerReleaseSwitchStatus ##2G## -  - C_TrunkInnerReleaseSw";
CM_ SG_ 1044 Trunk_TrnkTlgtOutReleaseSwSta "Trunk_TrunkTailgateOutReleaseSwitchStatus ##2G## -  - C_TrunkTgOtrReleaseSW";
CM_ SG_ 1044 Trunk_TrnkTlgtSwSta "Trunk_TrunkTailgateSwitchStatus ##2G## -  - C_TrunkTgSw,CF_Gway_TrunkTgSw,Trunk_TrnkTlgtSwSta";
CM_ SG_ 1044 Trunk_GlvBxTrnkLkSwSta "Trunk_GloveBoxTrunkLockSwitchStatus ##2G## -  - C_GloveBoxTrunkLockSw";
CM_ SG_ 1044 Trunk_TlgtFullOpnSwSta "Trunk_TailGateFullOpenSwitchStatus ##2G## -  - C_TgFullOpenSW";
CM_ SG_ 1044 Trunk_TrnkTlgtReleaseRlySta "Trunk_TrunkTailgateReleaseRelayStatus ##2G## -  - C_TrunkTgReleaseRlyAct";
CM_ SG_ 1044 USM_OneTouchTrnSigFuncSta "USM_OneTouchTurnSignalFunctionStatus ##2G## -  - CF_Gway_OTTurnRValue,C_OTTurnRValue";
CM_ SG_ 1044 DoorLock_DrvDrUnLkSta "DoorLock_DriverDoorUnLockStatus ##2G## -  - C_DrvUnlockState,CF_Gway_DrvUnlockState";
CM_ SG_ 1044 DoorLock_LkOutSta "DoorLock_LockOutputStatus ##2G## -  - C_LockUnlockOutState";
CM_ SG_ 1044 C_CrashUnlockState "Crash Unlock Active State";
CM_ SG_ 1044 C_AutoLeverManualSW "Auto Lever Manual Switch Status Information";
CM_ BO_ 579 "[PE] Periodic and On Event";
CM_ SG_ 579 OHCL_Opt "OHCL option state";
CM_ SG_ 579 OHCL_Sys_sta "OHCL Status";
CM_ SG_ 579 OHCL_DoorOn_Sta "Door lamp switch On/Off status";
CM_ SG_ 579 OHCL_RrMapLftOn_Sta "Rear left map lamp On/Off status";
CM_ SG_ 579 OHCL_RrMapRtOn_Sta "Rear right map lamp On/Off status";
CM_ SG_ 579 OHCL_RrRoomOn_Sta "Rear room lamp On/Off status";
CM_ SG_ 579 OHCL_RrMoodOn_Sta "Rear mood lamp On/Off status";
CM_ SG_ 579 OHCL_LEDClr_Sta "Interior lamps lighting color status";
CM_ SG_ 579 OHCL_LEDBgtns_Sta "Interior lamps brightness status";
CM_ SG_ 579 OHCL_TllTlLmpSta "PAB tell tale lamp status";
CM_ SG_ 579 OHCL_FrMapLftOn_Sta "Front left map lamp On/Off status";
CM_ SG_ 579 OHCL_RrCurtainReq "Rear Curtain Switch On/Off Signal";
CM_ SG_ 579 OHCL_FrMapRtOn_Sta "Front right map lamp On/Off status";
CM_ SG_ 579 OHCL_FrRoomOn_Sta "Front room lamp On/Off status";
CM_ SG_ 579 OHCL_FrMoodOn_Sta "Front mood lamp On/Off status";
CM_ BO_ 1068 "[PE] Periodic and On Event";
CM_ SG_ 1068 RLPSU_ReclMtrPos "RLPSU Recline Motor Position";
CM_ SG_ 1068 RLPSU_RLSlidPos "2nd Left Seat Slide Position Information for button activatation / unactivation";
CM_ SG_ 1068 RLPSU_RLRclPos "2nd Left Seat Back Reclining Position Information for button activatation / unactivation";
CM_ SG_ 1068 RLPSU_RLTiltPos "2nd Left Seat Cushion Tilt Position Information for button activatation / unactivation";
CM_ SG_ 1068 RLPSU_RLLegExtPos "2nd Left Seat Legsupport Extension Position Information for button activatation / unactivation";
CM_ SG_ 1068 RLPSU_RLLegSupPos "2nd Left Seat Legrest Support Position Information for button activatation / unactivation";
CM_ SG_ 1068 RLPSU_RLHrestSlidPos "2nd Left Seat Head Rest Slide Position Information for button activatation / unactivation";
CM_ SG_ 1068 RLPSU_RLHrestHeightPos "2nd Left Seat HeadRest Height Position Information for button activatation / unactivation";
CM_ SG_ 1068 RLPSU_Opt "PWR_HVU Option";
CM_ SG_ 1068 RLPSU_Opt_Captain "PWR_HVU Option_Captain";
CM_ SG_ 1068 RLHVU_Opt_Captain "MNL_HVU Option_Captain";
CM_ SG_ 1068 RLPSU_PwrSeatOpt "Option Info for 2nd Left Recline Seat";
CM_ SG_ 1068 RLPSU_PwrSeatPos "2nd Left Seat Back Position for button activatation / unactivation";
CM_ BO_ 1070 "[PE] Periodic and On Event";
CM_ SG_ 1070 RL_SHVU_HtSwHiIndSta "Rear Left_Seat Heater Switch High Indicator Status";
CM_ SG_ 1070 RL_SHVU_HtSwMidIndSta "Rear Left_Seat Heater Switch Mid Indicator Status";
CM_ SG_ 1070 RL_SHVU_HtSwLowIndSta "Rear Left_Seat Heater Switch Low Indicator Status";
CM_ SG_ 1070 RL_SHVU_VntSwHiIndSta "Rear Left Seat Vent Switch High Indicator Status";
CM_ SG_ 1070 RL_SHVU_VntSwMidIndSta "Rear Left Seat Vent Switch Mid Indicator Status";
CM_ SG_ 1070 RL_SHVU_VntSwLowIndSta "Rear Left Seat Vent Switch Low Indicator Status";
CM_ SG_ 1070 RL_SHVU_HtBlcUsmSta "RL Seat Heater Balance Status";
CM_ BO_ 1069 "[PE] Periodic and On Event";
CM_ SG_ 1069 RRPSU_ReclMtrPos "RRPSU Recline Motor Position";
CM_ SG_ 1069 RRPSU_PwrSeatOpt "Option Info for 2nd Right Recline Seat";
CM_ SG_ 1069 RRPSU_PwrSeatPos "2nd Right Seat Back Position for button activatation / unactivation";
CM_ SG_ 1069 RRPSU_RRSlidPos "2nd Right Seat Slide Position Information For Button Activation / Deactivation";
CM_ SG_ 1069 RRPSU_RRRclPos "2nd Right Seat Recline Position Information For Button Activation / Deactivation";
CM_ SG_ 1069 RRPSU_RRTiltPos "2nd Right Seat Cushion Tilt Position Information For Button Activation / Deactivation";
CM_ SG_ 1069 RRPSU_RRLegExtPos "2nd Right Seat Legextension (Front / Rear) Position Information For Button Activation / Deactivation";
CM_ SG_ 1069 RRPSU_RRLegSupPos "2nd Right Seat Leg Extension (Upper/Lower) Position Information For Button Activation / Deactivation";
CM_ SG_ 1069 RRPSU_RRStEsyAcsUSMSta "Rear RH Seat EasyAccess USM";
CM_ SG_ 1069 RRPSU_RRHrestSlidPos "2nd Right Seat HeadRest Slide Position Information For Button Activation / Deactivation";
CM_ SG_ 1069 RRPSU_RRHrestHeightPos "2nd Right Seat Headrest Height Position Information For Button Activation / Deactivation";
CM_ SG_ 1069 RRPSU_Opt_Captain "PWR_HVU Option_Captain";
CM_ SG_ 1069 RRHVU_Opt_Captain "MNL_HVU Option_Captain";
CM_ SG_ 1069 RRPSU_RLStEsyAcsUSMSta "Rear LH Seat EasyAccess USM Setting";
CM_ SG_ 1069 RRPSU_Opt "PWR_HVU Option";
CM_ BO_ 1071 "[PE] Periodic and On Event";
CM_ SG_ 1071 RR_SHVU_HtSwHiIndSta "Rear Right_Seat Heater Switch High Indicator Status";
CM_ SG_ 1071 RR_SHVU_HtSwMidIndSta "Rear Left_Seat Heater Switch Mid Indicator Status";
CM_ SG_ 1071 RR_SHVU_HtSwLowIndSta "Rear Right_Seat Heater Switch Low Indicator Status";
CM_ SG_ 1071 RR_SHVU_VntSwHiIndSta "Rear Right Seat Vent Switch High Indicator Status";
CM_ SG_ 1071 RR_SHVU_VntSwMidIndSta "Rear Right Seat Vent Switch Mid Indicator Status";
CM_ SG_ 1071 RR_SHVU_VntSwLowIndSta "Rear Right Seat Vent Switch Low Indicator Status";
CM_ SG_ 1071 RR_SHVU_HtBlcUsmSta "RR Seat Heater Balance Status";
CM_ BO_ 1067 "[PE] Periodic and On Event";
CM_ SG_ 1067 SCM_SWVerMajor1 "First Word(ASCII) in SCM S/W Ver";
CM_ SG_ 1067 SCM_SWVerMinor1 "Second Word(ASCII) in SCM S/W Ver";
CM_ SG_ 1067 SCM_SWVerMinor2 "Third Word(ASCII) in SCM S/W Ver";
BA_DEF_ BO_ "DiagState" ENUM "No","Yes" ;
BA_DEF_ BO_ "DiagResponse" ENUM "No","Yes" ;
BA_DEF_ BO_ "DiagRequest" ENUM "No","Yes" ;
BA_DEF_ BO_ "TpMessage" ENUM "No","Yes" ;
BA_DEF_ BO_ "UsrMsgIDSforwardDeviation" INT 0 100 ;
BA_DEF_ BO_ "UsrMsgIDSbackwardDeviation" INT 50 1000 ;
BA_DEF_ BO_ "GenMsgCycleTime" INT 0 2000 ;
BA_DEF_ BO_ "GenMsgStartDelayTime" INT 0 2000 ;
BA_DEF_ BO_ "GenMsgSendType" ENUM "Cyclic","NoMsgSendType" ;
BA_DEF_ BO_ "GenMsgCycleTimeFast" INT 0 500 ;
BA_DEF_ BO_ "GenMsgDelayTime" INT 0 20 ;
BA_DEF_ BO_ "GenMsgILSupport" ENUM "No","Yes" ;
BA_DEF_ BO_ "GenMsgNrOfRepetition" INT 0 3 ;
BA_DEF_ BO_ "NmMessage" ENUM "No","Yes" ;
BA_DEF_ BO_ "NWM-Botschaft" ENUM "No","Yes" ;
BA_DEF_ BO_ "TpTxIndex" INT 0 255 ;
BA_DEF_ BO_ "VFrameFormat" ENUM "StandardCAN","ExtendedCAN","reserved","reserved","reserved","reserved","reserved","reserved","reserved","reserved","reserved","reserved","reserved","reserved","StandardCAN_FD","ExtendedCAN_FD" ;
BA_DEF_ SG_ "UserSigValidity" ENUM "B+","ACC","IG","IG1","IG2","IG3","IG1 or IG2","IG1 or IG3","Undef" ;
BA_DEF_ SG_ "TimeoutValue" STRING ;
BA_DEF_ SG_ "UsrSigPurpose" ENUM "Undef","FN","DIAG","DIAG(Req)","DIAG(Res)","DIAG(Phy)","DEV","CCP(Req)","CCP(Res)","NM","TP" ;
BA_DEF_ SG_ "GenSigStartValue" INT 0 1215752192 ;
BA_DEF_ SG_ "NetworkRequest" ENUM "Yes","No" ;
BA_DEF_ SG_ "NetworkRequestHoldingTime" INT 0 65535 ;
BA_DEF_ SG_ "Description" STRING ;
BA_DEF_ SG_ "Version" STRING ;
BA_DEF_ SG_ "GenSigEnvVarType" ENUM "Int","Float","Undef" ;
BA_DEF_ SG_ "GenSigSendType" ENUM "Cyclic","OnWrite","OnWriteWithRepetition","OnChange","OnChangeWithRepetition","IfActive","IfActiveWithRepetition","NoSigSendType","OnChangeAndIfActive","OnChangeAndIfActiveWithRepetition" ;
BA_DEF_ SG_ "GwSigLatencyTime" INT 0 65536 ;
BA_DEF_ SG_ "GwSigMissingSourceType" ENUM "Undef","OldValue","DefaultValue","InitialValue" ;
BA_DEF_ SG_ "NWM-WakeupAllowed" ENUM "<n.a.>" ;
BA_DEF_ SG_ "RoutingFactor" INT 1 1215752192 ;
BA_DEF_REL_ BU_SG_REL_ "GenSigTimeoutTime" INT 0 7000 ;
BA_DEF_DEF_ "DiagState" "No" ;
BA_DEF_DEF_ "DiagResponse" "No" ;
BA_DEF_DEF_ "DiagRequest" "No" ;
BA_DEF_DEF_ "TpMessage" "No" ;
BA_DEF_DEF_ "UsrMsgIDSforwardDeviation" 10 ;
BA_DEF_DEF_ "UsrMsgIDSbackwardDeviation" 100 ;
BA_DEF_DEF_ "GenMsgCycleTime" 200 ;
BA_DEF_DEF_ "GenMsgStartDelayTime" 0 ;
BA_DEF_DEF_ "GenMsgSendType" "NoMsgSendType" ;
BA_DEF_DEF_ "GenMsgCycleTimeFast" 40 ;
BA_DEF_DEF_ "GenMsgDelayTime" 20 ;
BA_DEF_DEF_ "GenMsgILSupport" "Yes" ;
BA_DEF_DEF_ "GenMsgNrOfRepetition" 3 ;
BA_DEF_DEF_ "NmMessage" "No" ;
BA_DEF_DEF_ "NWM-Botschaft" "No" ;
BA_DEF_DEF_ "TpTxIndex" 0 ;
BA_DEF_DEF_ "VFrameFormat" "StandardCAN" ;
BA_DEF_DEF_ "UserSigValidity" "IG" ;
BA_DEF_DEF_ "TimeoutValue" "" ;
BA_DEF_DEF_ "UsrSigPurpose" "FN" ;
BA_DEF_DEF_ "GenSigStartValue" 0 ;
BA_DEF_DEF_ "NetworkRequest" "No" ;
BA_DEF_DEF_ "NetworkRequestHoldingTime" 0 ;
BA_DEF_DEF_ "Description" "" ;
BA_DEF_DEF_ "Version" "" ;
BA_DEF_DEF_ "GenSigEnvVarType" "Undef" ;
BA_DEF_DEF_ "GenSigSendType" "NoSigSendType" ;
BA_DEF_DEF_ "GwSigLatencyTime" 40 ;
BA_DEF_DEF_ "GwSigMissingSourceType" "Undef" ;
BA_DEF_DEF_ "NWM-WakeupAllowed" "<n.a.>" ;
BA_DEF_DEF_ "RoutingFactor" 1 ;
BA_DEF_DEF_REL_ "GenSigTimeoutTime" 500 ;
BA_ "GenMsgSendType" BO_ 1546 0;
BA_ "GenMsgCycleTimeFast" BO_ 1546 0;
BA_ "GenMsgNrOfRepetition" BO_ 1546 0;
BA_ "Description" SG_ 1546 AMP_SupportBeepVolumeControl "18.02.01_";
BA_ "GenSigStartValue" SG_ 1546 AMP_SupportBeepVolumeControl 3;
BA_ "UserSigValidity" SG_ 1546 AMP_SupportBeepVolumeControl 1;
BA_REL_ "GenSigTimeoutTime" BU_SG_REL_ ATS SG_ 1546 AMP_SupportBeepVolumeControl 1500;
BA_ "Version" SG_ 1546 AMP_SupportBeepVolumeControl "18.12.06";
BA_ "Description" SG_ 1546 AMP_SupportESEVMode "Dose amp support CenterPoint mode?";
BA_ "GenSigStartValue" SG_ 1546 AMP_SupportESEVMode 3;
BA_ "UserSigValidity" SG_ 1546 AMP_SupportESEVMode 1;
BA_ "NetworkRequest" SG_ 1546 AMP_SupportESEVMode 0;
BA_ "Version" SG_ 1546 AMP_SupportESEVMode "20.03.06";
BA_ "Description" SG_ 1546 AMP_SupportDSC "18.04.00_Does amp support Dynamic Speed Compensation mode?";
BA_ "GenSigStartValue" SG_ 1546 AMP_SupportDSC 3;
BA_ "UserSigValidity" SG_ 1546 AMP_SupportDSC 1;
BA_ "Version" SG_ 1546 AMP_SupportDSC "18.12.06";
BA_ "Description" SG_ 1546 AMP_SupportANCMode "18.03.08_";
BA_ "GenSigStartValue" SG_ 1546 AMP_SupportANCMode 3;
BA_ "UserSigValidity" SG_ 1546 AMP_SupportANCMode 1;
BA_ "Version" SG_ 1546 AMP_SupportANCMode "18.12.06";
BA_ "GenSigStartValue" SG_ 1546 AMP_MakerID 255;
BA_ "UserSigValidity" SG_ 1546 AMP_MakerID 1;
BA_ "Version" SG_ 1546 AMP_MakerID "19.12.00";
BA_ "Description" SG_ 1546 AMP_SupportQLS "16.03.03_";
BA_ "GenSigStartValue" SG_ 1546 AMP_SupportQLS 3;
BA_ "UserSigValidity" SG_ 1546 AMP_SupportQLS 1;
BA_ "Version" SG_ 1546 AMP_SupportQLS "18.12.06";
BA_ "Description" SG_ 1546 AMP_SupportQLS_2step "Information for 2 Step QLS mode (Harman AMP only)";
BA_ "GenSigStartValue" SG_ 1546 AMP_SupportQLS_2step 3;
BA_ "UserSigValidity" SG_ 1546 AMP_SupportQLS_2step 1;
BA_ "Version" SG_ 1546 AMP_SupportQLS_2step "21.09.10";
BA_ "GenSigStartValue" SG_ 1546 AMP_SupportHorizon 3;
BA_ "UserSigValidity" SG_ 1546 AMP_SupportHorizon 1;
BA_ "NetworkRequest" SG_ 1546 AMP_SupportHorizon 0;
BA_ "Version" SG_ 1546 AMP_SupportHorizon "20.05.00";
BA_ "Description" SG_ 1546 AMP_SupportASDMode "16.03.03_";
BA_ "GenSigStartValue" SG_ 1546 AMP_SupportASDMode 3;
BA_ "UserSigValidity" SG_ 1546 AMP_SupportASDMode 1;
BA_ "Version" SG_ 1546 AMP_SupportASDMode "18.12.06";
BA_ "GenSigStartValue" SG_ 1546 AMP_SupportIntelliQ 3;
BA_ "UserSigValidity" SG_ 1546 AMP_SupportIntelliQ 1;
BA_ "NetworkRequest" SG_ 1546 AMP_SupportIntelliQ 0;
BA_ "Version" SG_ 1546 AMP_SupportIntelliQ "20.05.00";
BA_ "Description" SG_ 1546 AMP_SupportCenterpoint "18.04.00_Does amp support CenterPoint mode?";
BA_ "GenSigStartValue" SG_ 1546 AMP_SupportCenterpoint 3;
BA_ "UserSigValidity" SG_ 1546 AMP_SupportCenterpoint 1;
BA_ "Version" SG_ 1546 AMP_SupportCenterpoint "18.12.06";
BA_ "Description" SG_ 1546 AMP_SupportSignalDoctor "16.03.03_";
BA_ "GenSigStartValue" SG_ 1546 AMP_SupportSignalDoctor 3;
BA_ "UserSigValidity" SG_ 1546 AMP_SupportSignalDoctor 1;
BA_ "Version" SG_ 1546 AMP_SupportSignalDoctor "18.12.06";
BA_ "Description" SG_ 1546 AMP_SupportLiveDynamicMode "16.03.04_";
BA_ "GenSigStartValue" SG_ 1546 AMP_SupportLiveDynamicMode 7;
BA_ "UserSigValidity" SG_ 1546 AMP_SupportLiveDynamicMode 1;
BA_ "Version" SG_ 1546 AMP_SupportLiveDynamicMode "18.12.06";
BA_ "Description" SG_ 1546 AMP_Support_ElecSound "16.07.03_";
BA_ "GenSigStartValue" SG_ 1546 AMP_Support_ElecSound 3;
BA_ "UserSigValidity" SG_ 1546 AMP_Support_ElecSound 1;
BA_ "NetworkRequest" SG_ 1546 AMP_Support_ElecSound 0;
BA_ "Version" SG_ 1546 AMP_Support_ElecSound "18.12.06";
BA_ "GenMsgSendType" BO_ 1064 0;
BA_ "Description" SG_ 1064 APSU_DiagSta "(Old)C_APSU_DiagState";
BA_ "GenSigSendType" SG_ 1064 APSU_DiagSta 4;
BA_ "UserSigValidity" SG_ 1064 APSU_DiagSta 0;
BA_ "NetworkRequest" SG_ 1064 APSU_DiagSta 0;
BA_ "NetworkRequestHoldingTime" SG_ 1064 APSU_DiagSta 5000;
BA_ "Version" SG_ 1064 APSU_DiagSta "17.11.00";
BA_ "Description" SG_ 1064 APSU_AstAllLmtSta "°¡»ó ¸®¹ÌÆ® ¼³Á¤ »óÅÂ Á¤º¸

Virtual Limit Set State (Not Set / All Set)";
BA_ "GenSigSendType" SG_ 1064 APSU_AstAllLmtSta 4;
BA_ "UserSigValidity" SG_ 1064 APSU_AstAllLmtSta 0;
BA_REL_ "GenSigTimeoutTime" BU_SG_REL_ RLPSU SG_ 1064 APSU_AstAllLmtSta 1500;
BA_REL_ "GenSigTimeoutTime" BU_SG_REL_ RRPSU SG_ 1064 APSU_AstAllLmtSta 1500;
BA_ "Version" SG_ 1064 APSU_AstAllLmtSta "20.12.04";
BA_ "Description" SG_ 1064 APSU_EsyAcsGetOnSta "Easy Access Get On Information";
BA_ "GenSigSendType" SG_ 1064 APSU_EsyAcsGetOnSta 4;
BA_ "UserSigValidity" SG_ 1064 APSU_EsyAcsGetOnSta 0;
BA_REL_ "GenSigTimeoutTime" BU_SG_REL_ ALBCU SG_ 1064 APSU_EsyAcsGetOnSta 1500;
BA_ "NetworkRequest" SG_ 1064 APSU_EsyAcsGetOnSta 0;
BA_ "NetworkRequestHoldingTime" SG_ 1064 APSU_EsyAcsGetOnSta 5000;
BA_ "Version" SG_ 1064 APSU_EsyAcsGetOnSta "17.11.00";
BA_ "Description" SG_ 1064 APSU_EsyAcsGetOffSta "Easy Access Get Off Information";
BA_ "GenSigSendType" SG_ 1064 APSU_EsyAcsGetOffSta 4;
BA_ "UserSigValidity" SG_ 1064 APSU_EsyAcsGetOffSta 0;
BA_REL_ "GenSigTimeoutTime" BU_SG_REL_ ALBCU SG_ 1064 APSU_EsyAcsGetOffSta 1500;
BA_ "NetworkRequest" SG_ 1064 APSU_EsyAcsGetOffSta 0;
BA_ "NetworkRequestHoldingTime" SG_ 1064 APSU_EsyAcsGetOffSta 5000;
BA_ "Version" SG_ 1064 APSU_EsyAcsGetOffSta "17.11.00";
BA_ "Description" SG_ 1064 APSU_EsyAcsStpSta "Easy Access Stop Information";
BA_ "GenSigSendType" SG_ 1064 APSU_EsyAcsStpSta 4;
BA_ "UserSigValidity" SG_ 1064 APSU_EsyAcsStpSta 0;
BA_REL_ "GenSigTimeoutTime" BU_SG_REL_ ALBCU SG_ 1064 APSU_EsyAcsStpSta 1500;
BA_ "NetworkRequest" SG_ 1064 APSU_EsyAcsStpSta 0;
BA_ "NetworkRequestHoldingTime" SG_ 1064 APSU_EsyAcsStpSta 5000;
BA_ "Version" SG_ 1064 APSU_EsyAcsStpSta "17.11.00";
BA_ "GenSigSendType" SG_ 1064 APSU_RVal 4;
BA_ "UserSigValidity" SG_ 1064 APSU_RVal 0;
BA_ "NetworkRequest" SG_ 1064 APSU_RVal 0;
BA_ "NetworkRequestHoldingTime" SG_ 1064 APSU_RVal 5000;
BA_ "Version" SG_ 1064 APSU_RVal "17.11.00";
BA_ "GenMsgCycleTime" BO_ 639 0;
BA_ "Description" SG_ 639 ATS_RRSeatHeaterSW "ÈÄ¼® RH ½ÃÆ® ¿­¼± Á¶Àý";
BA_ "GenSigSendType" SG_ 639 ATS_RRSeatHeaterSW 4;
BA_ "UserSigValidity" SG_ 639 ATS_RRSeatHeaterSW 3;
BA_REL_ "GenSigTimeoutTime" BU_SG_REL_ RRHV SG_ 639 ATS_RRSeatHeaterSW 0;
BA_REL_ "GenSigTimeoutTime" BU_SG_REL_ SHVU_RR SG_ 639 ATS_RRSeatHeaterSW 0;
BA_ "NetworkRequest" SG_ 639 ATS_RRSeatHeaterSW 0;
BA_ "NetworkRequestHoldingTime" SG_ 639 ATS_RRSeatHeaterSW 5000;
BA_ "Version" SG_ 639 ATS_RRSeatHeaterSW "20.07.01";
BA_ "Description" SG_ 639 ATS_RLSeatHeaterUpSW "ÈÄ¼® LH ½ÃÆ® ¿­¼± Á¶Àý";
BA_ "GenSigSendType" SG_ 639 ATS_RLSeatHeaterUpSW 4;
BA_ "UserSigValidity" SG_ 639 ATS_RLSeatHeaterUpSW 3;
BA_REL_ "GenSigTimeoutTime" BU_SG_REL_ RLHV SG_ 639 ATS_RLSeatHeaterUpSW 0;
BA_REL_ "GenSigTimeoutTime" BU_SG_REL_ SHVU_RR SG_ 639 ATS_RLSeatHeaterUpSW 0;
BA_ "NetworkRequest" SG_ 639 ATS_RLSeatHeaterUpSW 0;
BA_ "NetworkRequestHoldingTime" SG_ 639 ATS_RLSeatHeaterUpSW 5000;
BA_ "Version" SG_ 639 ATS_RLSeatHeaterUpSW "20.12.04";
BA_ "Description" SG_ 639 ATS_RRSeatVentDownSW "ÈÄ¼® RH ½ÃÆ® ÅëÇ³ Á¶Àý";
BA_ "GenSigSendType" SG_ 639 ATS_RRSeatVentDownSW 4;
BA_ "UserSigValidity" SG_ 639 ATS_RRSeatVentDownSW 3;
BA_REL_ "GenSigTimeoutTime" BU_SG_REL_ RRHV SG_ 639 ATS_RRSeatVentDownSW 0;
BA_REL_ "GenSigTimeoutTime" BU_SG_REL_ SHVU_RR SG_ 639 ATS_RRSeatVentDownSW 0;
BA_ "NetworkRequest" SG_ 639 ATS_RRSeatVentDownSW 0;
BA_ "NetworkRequestHoldingTime" SG_ 639 ATS_RRSeatVentDownSW 5000;
BA_ "Version" SG_ 639 ATS_RRSeatVentDownSW "20.12.04";
BA_ "Description" SG_ 639 ATS_RLSeatVentDownSW "ÈÄ¼® LH ½ÃÆ® ÅëÇ³ Á¶Àý";
BA_ "GenSigSendType" SG_ 639 ATS_RLSeatVentDownSW 4;
BA_ "UserSigValidity" SG_ 639 ATS_RLSeatVentDownSW 3;
BA_REL_ "GenSigTimeoutTime" BU_SG_REL_ RLHV SG_ 639 ATS_RLSeatVentDownSW 0;
BA_REL_ "GenSigTimeoutTime" BU_SG_REL_ SHVU_RR SG_ 639 ATS_RLSeatVentDownSW 0;
BA_ "NetworkRequest" SG_ 639 ATS_RLSeatVentDownSW 0;
BA_ "NetworkRequestHoldingTime" SG_ 639 ATS_RLSeatVentDownSW 5000;
BA_ "Version" SG_ 639 ATS_RLSeatVentDownSW "20.12.04";
BA_ "Description" SG_ 639 ATS_RLMemoryRestBtn "Rear Left Rest Mode Custom Save Button (Except North America)";
BA_ "GenSigSendType" SG_ 639 ATS_RLMemoryRestBtn 4;
BA_ "UserSigValidity" SG_ 639 ATS_RLMemoryRestBtn 3;
BA_ "NetworkRequest" SG_ 639 ATS_RLMemoryRestBtn 0;
BA_ "NetworkRequestHoldingTime" SG_ 639 ATS_RLMemoryRestBtn 5000;
BA_ "Version" SG_ 639 ATS_RLMemoryRestBtn "21.01.02";
BA_ "Description" SG_ 639 ATS_RLMemoryReturnBtn "Rear Left Return Mode Custom Save Button (Except North America)";
BA_ "GenSigSendType" SG_ 639 ATS_RLMemoryReturnBtn 4;
BA_ "UserSigValidity" SG_ 639 ATS_RLMemoryReturnBtn 3;
BA_ "NetworkRequest" SG_ 639 ATS_RLMemoryReturnBtn 0;
BA_ "NetworkRequestHoldingTime" SG_ 639 ATS_RLMemoryReturnBtn 5000;
BA_ "Version" SG_ 639 ATS_RLMemoryReturnBtn "21.01.02";
BA_ "Description" SG_ 639 ATS_RLSeatHeaterSW "ÈÄ¼® LH ½ÃÆ® ¿­¼± Á¶Àý";
BA_ "GenSigSendType" SG_ 639 ATS_RLSeatHeaterSW 4;
BA_ "UserSigValidity" SG_ 639 ATS_RLSeatHeaterSW 3;
BA_REL_ "GenSigTimeoutTime" BU_SG_REL_ RLHV SG_ 639 ATS_RLSeatHeaterSW 0;
BA_REL_ "GenSigTimeoutTime" BU_SG_REL_ SHVU_RR SG_ 639 ATS_RLSeatHeaterSW 0;
BA_ "NetworkRequest" SG_ 639 ATS_RLSeatHeaterSW 0;
BA_ "NetworkRequestHoldingTime" SG_ 639 ATS_RLSeatHeaterSW 5000;
BA_ "Version" SG_ 639 ATS_RLSeatHeaterSW "20.07.01";
BA_ "Description" SG_ 639 ATS_RRMemoryRestBtn "Rear Right Rest Mode Custom Save Button (Except North America)";
BA_ "GenSigSendType" SG_ 639 ATS_RRMemoryRestBtn 4;
BA_ "UserSigValidity" SG_ 639 ATS_RRMemoryRestBtn 3;
BA_ "NetworkRequest" SG_ 639 ATS_RRMemoryRestBtn 0;
BA_ "NetworkRequestHoldingTime" SG_ 639 ATS_RRMemoryRestBtn 5000;
BA_ "Version" SG_ 639 ATS_RRMemoryRestBtn "21.01.02";
BA_ "Description" SG_ 639 ATS_RRMemoryReturnBtn "Rear Right Return Mode Custom Save Button (Except North America)";
BA_ "GenSigSendType" SG_ 639 ATS_RRMemoryReturnBtn 4;
BA_ "UserSigValidity" SG_ 639 ATS_RRMemoryReturnBtn 3;
BA_ "NetworkRequest" SG_ 639 ATS_RRMemoryReturnBtn 0;
BA_ "NetworkRequestHoldingTime" SG_ 639 ATS_RRMemoryReturnBtn 5000;
BA_ "Version" SG_ 639 ATS_RRMemoryReturnBtn "21.01.02";
BA_ "Description" SG_ 639 ATS_RRMemoryAvWtcBtn "Rear Right AV Watching Mode Custom Save Button (Except North America)";
BA_ "GenSigSendType" SG_ 639 ATS_RRMemoryAvWtcBtn 4;
BA_ "UserSigValidity" SG_ 639 ATS_RRMemoryAvWtcBtn 3;
BA_ "NetworkRequest" SG_ 639 ATS_RRMemoryAvWtcBtn 0;
BA_ "NetworkRequestHoldingTime" SG_ 639 ATS_RRMemoryAvWtcBtn 5000;
BA_ "Version" SG_ 639 ATS_RRMemoryAvWtcBtn "21.01.02";
BA_ "Description" SG_ 639 ATS_RRMemoryReadingBtn "Rear Right Reading Mode Custom Save Button (Except North America)";
BA_ "GenSigSendType" SG_ 639 ATS_RRMemoryReadingBtn 4;
BA_ "UserSigValidity" SG_ 639 ATS_RRMemoryReadingBtn 3;
BA_ "NetworkRequest" SG_ 639 ATS_RRMemoryReadingBtn 0;
BA_ "NetworkRequestHoldingTime" SG_ 639 ATS_RRMemoryReadingBtn 5000;
BA_ "Version" SG_ 639 ATS_RRMemoryReadingBtn "21.01.02";
BA_ "Description" SG_ 639 ATS_RRRestModBtnSTD "Rear Right Rest Mode Touch Button (EXCEPT North America)";
BA_ "GenSigSendType" SG_ 639 ATS_RRRestModBtnSTD 4;
BA_ "UserSigValidity" SG_ 639 ATS_RRRestModBtnSTD 3;
BA_ "NetworkRequest" SG_ 639 ATS_RRRestModBtnSTD 0;
BA_ "NetworkRequestHoldingTime" SG_ 639 ATS_RRRestModBtnSTD 5000;
BA_ "Version" SG_ 639 ATS_RRRestModBtnSTD "20.07.01";
BA_ "Description" SG_ 639 ATS_RRResetModBtnSTD "Rear Right Return Mode Touch Button (EXCEPT North America)";
BA_ "GenSigSendType" SG_ 639 ATS_RRResetModBtnSTD 4;
BA_ "UserSigValidity" SG_ 639 ATS_RRResetModBtnSTD 3;
BA_ "NetworkRequest" SG_ 639 ATS_RRResetModBtnSTD 0;
BA_ "NetworkRequestHoldingTime" SG_ 639 ATS_RRResetModBtnSTD 5000;
BA_ "Version" SG_ 639 ATS_RRResetModBtnSTD "20.07.01";
BA_ "Description" SG_ 639 ATS_RRAvWtcModBtnSTD "Rear Right AV Watching Mode Touch Button (EXCEPT North America)";
BA_ "GenSigSendType" SG_ 639 ATS_RRAvWtcModBtnSTD 4;
BA_ "UserSigValidity" SG_ 639 ATS_RRAvWtcModBtnSTD 3;
BA_ "NetworkRequest" SG_ 639 ATS_RRAvWtcModBtnSTD 0;
BA_ "NetworkRequestHoldingTime" SG_ 639 ATS_RRAvWtcModBtnSTD 5000;
BA_ "Version" SG_ 639 ATS_RRAvWtcModBtnSTD "20.07.01";
BA_ "Description" SG_ 639 ATS_RRReadingModBtnSTD "Rear Right Reading Mode Touch Button (EXCEPT North America)";
BA_ "GenSigSendType" SG_ 639 ATS_RRReadingModBtnSTD 4;
BA_ "UserSigValidity" SG_ 639 ATS_RRReadingModBtnSTD 3;
BA_ "NetworkRequest" SG_ 639 ATS_RRReadingModBtnSTD 0;
BA_ "NetworkRequestHoldingTime" SG_ 639 ATS_RRReadingModBtnSTD 5000;
BA_ "Version" SG_ 639 ATS_RRReadingModBtnSTD "20.07.01";
BA_ "Description" SG_ 639 ATS_RRSeatVentSW "ÈÄ¼® RH ½ÃÆ® ÅëÇ³ Á¶Àý";
BA_ "GenSigSendType" SG_ 639 ATS_RRSeatVentSW 4;
BA_ "UserSigValidity" SG_ 639 ATS_RRSeatVentSW 3;
BA_REL_ "GenSigTimeoutTime" BU_SG_REL_ RRHV SG_ 639 ATS_RRSeatVentSW 0;
BA_REL_ "GenSigTimeoutTime" BU_SG_REL_ SHVU_RR SG_ 639 ATS_RRSeatVentSW 0;
BA_ "NetworkRequest" SG_ 639 ATS_RRSeatVentSW 0;
BA_ "NetworkRequestHoldingTime" SG_ 639 ATS_RRSeatVentSW 5000;
BA_ "Version" SG_ 639 ATS_RRSeatVentSW "20.07.01";
BA_ "Description" SG_ 639 ATS_RLRestModBtnSTD "Rear Left Rest Mode Touch Button (EXCEPT North America)";
BA_ "GenSigSendType" SG_ 639 ATS_RLRestModBtnSTD 4;
BA_ "UserSigValidity" SG_ 639 ATS_RLRestModBtnSTD 3;
BA_ "NetworkRequest" SG_ 639 ATS_RLRestModBtnSTD 0;
BA_ "NetworkRequestHoldingTime" SG_ 639 ATS_RLRestModBtnSTD 5000;
BA_ "Version" SG_ 639 ATS_RLRestModBtnSTD "20.07.01";
BA_ "Description" SG_ 639 ATS_RLResetModBtnSTD "Rear Left Return Mode Touch Button (EXCEPT North America)";
BA_ "GenSigSendType" SG_ 639 ATS_RLResetModBtnSTD 4;
BA_ "UserSigValidity" SG_ 639 ATS_RLResetModBtnSTD 3;
BA_ "NetworkRequest" SG_ 639 ATS_RLResetModBtnSTD 0;
BA_ "NetworkRequestHoldingTime" SG_ 639 ATS_RLResetModBtnSTD 5000;
BA_ "Version" SG_ 639 ATS_RLResetModBtnSTD "20.07.01";
BA_ "Description" SG_ 639 ATS_RRModestateStopBtn "Rear Right One touch mode Stop Button";
BA_ "GenSigSendType" SG_ 639 ATS_RRModestateStopBtn 4;
BA_ "UserSigValidity" SG_ 639 ATS_RRModestateStopBtn 3;
BA_ "NetworkRequest" SG_ 639 ATS_RRModestateStopBtn 0;
BA_ "NetworkRequestHoldingTime" SG_ 639 ATS_RRModestateStopBtn 5000;
BA_ "Version" SG_ 639 ATS_RRModestateStopBtn "20.07.01";
BA_ "Description" SG_ 639 ATS_RLModestateStopBtn "Rear Left One touch mode Stop Button";
BA_ "GenSigSendType" SG_ 639 ATS_RLModestateStopBtn 4;
BA_ "UserSigValidity" SG_ 639 ATS_RLModestateStopBtn 3;
BA_ "NetworkRequest" SG_ 639 ATS_RLModestateStopBtn 0;
BA_ "NetworkRequestHoldingTime" SG_ 639 ATS_RLModestateStopBtn 5000;
BA_ "Version" SG_ 639 ATS_RLModestateStopBtn "20.07.01";
BA_ "Description" SG_ 639 ATS_RLResetRestBtn "Rear Left Rest Mode Custom Initialization Button (Except North America)";
BA_ "GenSigSendType" SG_ 639 ATS_RLResetRestBtn 4;
BA_ "UserSigValidity" SG_ 639 ATS_RLResetRestBtn 3;
BA_ "NetworkRequest" SG_ 639 ATS_RLResetRestBtn 0;
BA_ "NetworkRequestHoldingTime" SG_ 639 ATS_RLResetRestBtn 5000;
BA_ "Version" SG_ 639 ATS_RLResetRestBtn "21.01.02";
BA_ "Description" SG_ 639 ATS_RLResetReturnBtn "Rear Left Return Mode Custom Initialization Button (Except North America)";
BA_ "GenSigSendType" SG_ 639 ATS_RLResetReturnBtn 4;
BA_ "UserSigValidity" SG_ 639 ATS_RLResetReturnBtn 3;
BA_ "NetworkRequest" SG_ 639 ATS_RLResetReturnBtn 0;
BA_ "NetworkRequestHoldingTime" SG_ 639 ATS_RLResetReturnBtn 5000;
BA_ "Version" SG_ 639 ATS_RLResetReturnBtn "21.01.02";
BA_ "Description" SG_ 639 ATS_RRResetRestBtn "Rear Right Rest Mode Custom Initialization Button (Except North America)";
BA_ "GenSigSendType" SG_ 639 ATS_RRResetRestBtn 4;
BA_ "UserSigValidity" SG_ 639 ATS_RRResetRestBtn 3;
BA_ "NetworkRequest" SG_ 639 ATS_RRResetRestBtn 0;
BA_ "NetworkRequestHoldingTime" SG_ 639 ATS_RRResetRestBtn 5000;
BA_ "Version" SG_ 639 ATS_RRResetRestBtn "21.01.02";
BA_ "Description" SG_ 639 ATS_RRResetReturnBtn "Rear Right Return Mode Custom Initialization Button (Except North America)";
BA_ "GenSigSendType" SG_ 639 ATS_RRResetReturnBtn 4;
BA_ "UserSigValidity" SG_ 639 ATS_RRResetReturnBtn 3;
BA_ "NetworkRequest" SG_ 639 ATS_RRResetReturnBtn 0;
BA_ "NetworkRequestHoldingTime" SG_ 639 ATS_RRResetReturnBtn 5000;
BA_ "Version" SG_ 639 ATS_RRResetReturnBtn "21.01.02";
BA_ "Description" SG_ 639 ATS_RRResetAvWtcBtn "Rear Right AV Watching Mode Custom Initialization Button (Except North America)";
BA_ "GenSigSendType" SG_ 639 ATS_RRResetAvWtcBtn 4;
BA_ "UserSigValidity" SG_ 639 ATS_RRResetAvWtcBtn 3;
BA_ "NetworkRequest" SG_ 639 ATS_RRResetAvWtcBtn 0;
BA_ "NetworkRequestHoldingTime" SG_ 639 ATS_RRResetAvWtcBtn 5000;
BA_ "Version" SG_ 639 ATS_RRResetAvWtcBtn "21.01.02";
BA_ "Description" SG_ 639 ATS_RRResetReadingBtn "Rear Right Reading Mode Custom Initialization Button (Except North America)";
BA_ "GenSigSendType" SG_ 639 ATS_RRResetReadingBtn 4;
BA_ "UserSigValidity" SG_ 639 ATS_RRResetReadingBtn 3;
BA_ "NetworkRequest" SG_ 639 ATS_RRResetReadingBtn 0;
BA_ "NetworkRequestHoldingTime" SG_ 639 ATS_RRResetReadingBtn 5000;
BA_ "Version" SG_ 639 ATS_RRResetReadingBtn "21.01.02";
BA_ "Description" SG_ 639 ATS_RLSeatVentSW "ÈÄ¼® LH ½ÃÆ® ÅëÇ³ Á¶Àý";
BA_ "GenSigSendType" SG_ 639 ATS_RLSeatVentSW 4;
BA_ "UserSigValidity" SG_ 639 ATS_RLSeatVentSW 3;
BA_REL_ "GenSigTimeoutTime" BU_SG_REL_ RLHV SG_ 639 ATS_RLSeatVentSW 0;
BA_REL_ "GenSigTimeoutTime" BU_SG_REL_ SHVU_RR SG_ 639 ATS_RLSeatVentSW 0;
BA_ "NetworkRequest" SG_ 639 ATS_RLSeatVentSW 0;
BA_ "NetworkRequestHoldingTime" SG_ 639 ATS_RLSeatVentSW 5000;
BA_ "Version" SG_ 639 ATS_RLSeatVentSW "20.07.01";
BA_ "Description" SG_ 639 ATS_RRSeatHeaterUpSW "ÈÄ¼® RH ½ÃÆ® ¿­¼± Á¶Àý";
BA_ "GenSigSendType" SG_ 639 ATS_RRSeatHeaterUpSW 4;
BA_ "UserSigValidity" SG_ 639 ATS_RRSeatHeaterUpSW 3;
BA_REL_ "GenSigTimeoutTime" BU_SG_REL_ RRHV SG_ 639 ATS_RRSeatHeaterUpSW 0;
BA_REL_ "GenSigTimeoutTime" BU_SG_REL_ SHVU_RR SG_ 639 ATS_RRSeatHeaterUpSW 0;
BA_ "NetworkRequest" SG_ 639 ATS_RRSeatHeaterUpSW 0;
BA_ "NetworkRequestHoldingTime" SG_ 639 ATS_RRSeatHeaterUpSW 5000;
BA_ "Version" SG_ 639 ATS_RRSeatHeaterUpSW "20.12.04";
BA_ "GenMsgSendType" BO_ 1058 0;
BA_ "Description" SG_ 1058 BCM_Crc10Val "The data area for CRC calculation is based on the data length (DLC) of the message DB.

The CRC shall be calculated over the entire data block (excluding the CRC bytes) including the user data, alive counter and Data ID 

 

- CRC Polynomial (0x1D) , Initial Value : 0x00, XOR value : 0xFF, Data ID Mode : Both, Data ID : Message ID + 0xF800 

- The initial value is for CRC calculation and the message should be sent with the calculated result value. 

The mathematical expression to 8 bit CRC polynomial is given here. G(x) = x8 + x4 + x3 + x2 + 1";
BA_ "GenSigSendType" SG_ 1058 BCM_Crc10Val 4;
BA_ "GenSigStartValue" SG_ 1058 BCM_Crc10Val 255;
BA_ "UserSigValidity" SG_ 1058 BCM_Crc10Val 0;
BA_ "Version" SG_ 1058 BCM_Crc10Val "18.11.08";
BA_ "Description" SG_ 1058 BCM_AlvCnt10Val "For the first transmission request for a data element the counter shall be initialized with 0 and shall be incremented by 1

for every subsequent send request. When the counter reaches the maximum value(0xE), then it shall restart with 0 for the next send request";
BA_ "GenSigSendType" SG_ 1058 BCM_AlvCnt10Val 4;
BA_ "UserSigValidity" SG_ 1058 BCM_AlvCnt10Val 0;
BA_ "Version" SG_ 1058 BCM_AlvCnt10Val "18.11.08";
BA_ "GenSigSendType" SG_ 1058 Wiper_PrkngPosSta 4;
BA_ "UserSigValidity" SG_ 1058 Wiper_PrkngPosSta 0;
BA_ "NetworkRequest" SG_ 1058 Wiper_PrkngPosSta 0;
BA_ "NetworkRequestHoldingTime" SG_ 1058 Wiper_PrkngPosSta 5000;
BA_ "Version" SG_ 1058 Wiper_PrkngPosSta "17.12.00";
BA_ "Description" SG_ 1058 Wiper_RainSnsrOptionTyp "Rain Sensor Option Information";
BA_ "GenSigSendType" SG_ 1058 Wiper_RainSnsrOptionTyp 4;
BA_ "UserSigValidity" SG_ 1058 Wiper_RainSnsrOptionTyp 0;
BA_ "NetworkRequest" SG_ 1058 Wiper_RainSnsrOptionTyp 0;
BA_ "NetworkRequestHoldingTime" SG_ 1058 Wiper_RainSnsrOptionTyp 5000;
BA_ "Version" SG_ 1058 Wiper_RainSnsrOptionTyp "17.12.00";
BA_ "Description" SG_ 1058 Wiper_RainSnsrSta "This signal represents the status of Rain Sensor signal state. 

- '20. 8/3 : Changed value table (0x5, 0x6 : Fault2/3 ¡æ Reserved)";
BA_ "GenSigSendType" SG_ 1058 Wiper_RainSnsrSta 4;
BA_ "UserSigValidity" SG_ 1058 Wiper_RainSnsrSta 0;
BA_ "NetworkRequest" SG_ 1058 Wiper_RainSnsrSta 0;
BA_ "NetworkRequestHoldingTime" SG_ 1058 Wiper_RainSnsrSta 5000;
BA_ "Version" SG_ 1058 Wiper_RainSnsrSta "20.08.00";
BA_ "Description" SG_ 1058 Wiper_HtWshNzzlCmd "Heated Washer Nozzle Command";
BA_ "GenSigSendType" SG_ 1058 Wiper_HtWshNzzlCmd 4;
BA_ "UserSigValidity" SG_ 1058 Wiper_HtWshNzzlCmd 0;
BA_ "NetworkRequest" SG_ 1058 Wiper_HtWshNzzlCmd 0;
BA_ "NetworkRequestHoldingTime" SG_ 1058 Wiper_HtWshNzzlCmd 5000;
BA_ "Version" SG_ 1058 Wiper_HtWshNzzlCmd "20.08.07";
BA_ "Description" SG_ 1058 BCM_SolSnsrRtOutVoltVal "This signal indicates solar sensor output voltage - RH";
BA_ "GenSigSendType" SG_ 1058 BCM_SolSnsrRtOutVoltVal 4;
BA_ "UserSigValidity" SG_ 1058 BCM_SolSnsrRtOutVoltVal 0;
BA_ "NetworkRequest" SG_ 1058 BCM_SolSnsrRtOutVoltVal 0;
BA_ "NetworkRequestHoldingTime" SG_ 1058 BCM_SolSnsrRtOutVoltVal 5000;
BA_ "Version" SG_ 1058 BCM_SolSnsrRtOutVoltVal "18.04.02";
BA_ "Description" SG_ 1058 BCM_SolSnsrLftOutVoltVal "This signal indicates solar sensor output voltage - LH";
BA_ "GenSigSendType" SG_ 1058 BCM_SolSnsrLftOutVoltVal 4;
BA_ "UserSigValidity" SG_ 1058 BCM_SolSnsrLftOutVoltVal 0;
BA_ "NetworkRequest" SG_ 1058 BCM_SolSnsrLftOutVoltVal 0;
BA_ "NetworkRequestHoldingTime" SG_ 1058 BCM_SolSnsrLftOutVoltVal 5000;
BA_ "Version" SG_ 1058 BCM_SolSnsrLftOutVoltVal "18.04.02";
BA_ "Description" SG_ 1058 BCM_GearPosPSta "This signal is valid only when connected to Key Interlock SW or P Position SW as a circuit";
BA_ "GenSigSendType" SG_ 1058 BCM_GearPosPSta 4;
BA_ "UserSigValidity" SG_ 1058 BCM_GearPosPSta 0;
BA_REL_ "GenSigTimeoutTime" BU_SG_REL_ SCM SG_ 1058 BCM_GearPosPSta 1500;
BA_REL_ "GenSigTimeoutTime" BU_SG_REL_ APSU SG_ 1058 BCM_GearPosPSta 1500;
BA_REL_ "GenSigTimeoutTime" BU_SG_REL_ RLHV SG_ 1058 BCM_GearPosPSta 1500;
BA_REL_ "GenSigTimeoutTime" BU_SG_REL_ RRHV SG_ 1058 BCM_GearPosPSta 1500;
BA_REL_ "GenSigTimeoutTime" BU_SG_REL_ DPSU SG_ 1058 BCM_GearPosPSta 1500;
BA_REL_ "GenSigTimeoutTime" BU_SG_REL_ PFSU SG_ 1058 BCM_GearPosPSta 1500;
BA_REL_ "GenSigTimeoutTime" BU_SG_REL_ RRPSU SG_ 1058 BCM_GearPosPSta 1500;
BA_REL_ "GenSigTimeoutTime" BU_SG_REL_ RLPSU SG_ 1058 BCM_GearPosPSta 1500;
BA_REL_ "GenSigTimeoutTime" BU_SG_REL_ ATS SG_ 1058 BCM_GearPosPSta 1500;
BA_ "NetworkRequest" SG_ 1058 BCM_GearPosPSta 0;
BA_ "NetworkRequestHoldingTime" SG_ 1058 BCM_GearPosPSta 5000;
BA_ "Version" SG_ 1058 BCM_GearPosPSta "21.07.04";
BA_ "Description" SG_ 1058 BCM_SunRoofOpnSta "-Sunroof open/close state";
BA_ "GenSigSendType" SG_ 1058 BCM_SunRoofOpnSta 4;
BA_ "UserSigValidity" SG_ 1058 BCM_SunRoofOpnSta 0;
BA_ "NetworkRequest" SG_ 1058 BCM_SunRoofOpnSta 0;
BA_ "NetworkRequestHoldingTime" SG_ 1058 BCM_SunRoofOpnSta 5000;
BA_ "Version" SG_ 1058 BCM_SunRoofOpnSta "17.12.00";
BA_ "Description" SG_ 1058 SunRoof_RrBlindErrSta "Rear Sunroof Blind error Status (LIN to CAN signal)

-LIN Signal Name : SunBlind_Rear_Error";
BA_ "GenSigSendType" SG_ 1058 SunRoof_RrBlindErrSta 4;
BA_ "UserSigValidity" SG_ 1058 SunRoof_RrBlindErrSta 0;
BA_ "Version" SG_ 1058 SunRoof_RrBlindErrSta "20.07.00";
BA_ "Description" SG_ 1058 Wiper_AutoWashModeSta "Auto Wash Mode Wiper State";
BA_ "GenSigSendType" SG_ 1058 Wiper_AutoWashModeSta 4;
BA_ "UserSigValidity" SG_ 1058 Wiper_AutoWashModeSta 0;
BA_ "NetworkRequest" SG_ 1058 Wiper_AutoWashModeSta 0;
BA_ "NetworkRequestHoldingTime" SG_ 1058 Wiper_AutoWashModeSta 5000;
BA_ "Version" SG_ 1058 Wiper_AutoWashModeSta "21.12.00";
BA_ "GenMsgSendType" BO_ 2424579841 0;
BA_ "VFrameFormat" BO_ 2424579841 1;
BA_ "Description" SG_ 2424579841 DATC_Crc11Val "The data area for CRC calculation is based on the data length (DLC) of the message DB.

The CRC shall be calculated over the entire data block (excluding the CRC bytes) including the user data, alive counter and Data ID

 

- CRC Polynomial (0x1021) , Initial Value : 0xFFFF, XOR value : 0x0000, Data ID : Message ID + 0xF800 

- The initial value is for CRC calculation and the message should be sent with the calculated result value. 

- The mathematical expression to 16 bit CRC polynomial is given here. G(x) = x16 + x12 + x5 + 1";
BA_ "GenSigSendType" SG_ 2424579841 DATC_Crc11Val 4;
BA_ "GenSigStartValue" SG_ 2424579841 DATC_Crc11Val 65535;
BA_ "UserSigValidity" SG_ 2424579841 DATC_Crc11Val 3;
BA_ "Version" SG_ 2424579841 DATC_Crc11Val "18.11.08";
BA_ "Description" SG_ 2424579841 DATC_AlvCnt11Val "For the first transmission request for a data element the counter shall be initialized with 0 and shall be incremented by 1 for every subsequent send request. 

When the counter reaches the maximum value(0xFF), then it shall restart with 0 for the next send request";
BA_ "GenSigSendType" SG_ 2424579841 DATC_AlvCnt11Val 4;
BA_ "UserSigValidity" SG_ 2424579841 DATC_AlvCnt11Val 3;
BA_ "Version" SG_ 2424579841 DATC_AlvCnt11Val "18.11.08";
BA_ "Description" SG_ 2424579841 DATC_TnnlClimtUSMSta "Tunnel Mode USM State";
BA_ "GenSigSendType" SG_ 2424579841 DATC_TnnlClimtUSMSta 4;
BA_ "UserSigValidity" SG_ 2424579841 DATC_TnnlClimtUSMSta 7;
BA_ "Version" SG_ 2424579841 DATC_TnnlClimtUSMSta "17.11.00";
BA_ "Description" SG_ 2424579841 DATC_ProximitySnsrSta "HTR CONTROL light near button ON/OFF USM f/back signal";
BA_ "GenSigSendType" SG_ 2424579841 DATC_ProximitySnsrSta 4;
BA_ "UserSigValidity" SG_ 2424579841 DATC_ProximitySnsrSta 7;
BA_ "Version" SG_ 2424579841 DATC_ProximitySnsrSta "17.11.00";
BA_ "Description" SG_ 2424579841 DATC_TunnelFuncOff4AutoDfgReq "DATC Turn off Tunnel Function for ADS";
BA_ "GenSigSendType" SG_ 2424579841 DATC_TunnelFuncOff4AutoDfgReq 4;
BA_ "UserSigValidity" SG_ 2424579841 DATC_TunnelFuncOff4AutoDfgReq 7;
BA_ "Version" SG_ 2424579841 DATC_TunnelFuncOff4AutoDfgReq "17.11.00";
BA_ "Description" SG_ 2424579841 DATC_RrCtlLckSta "Rear Lock Status Informed  DATC  to AVN";
BA_ "GenSigSendType" SG_ 2424579841 DATC_RrCtlLckSta 4;
BA_ "UserSigValidity" SG_ 2424579841 DATC_RrCtlLckSta 7;
BA_REL_ "GenSigTimeoutTime" BU_SG_REL_ ATS SG_ 2424579841 DATC_RrCtlLckSta 1500;
BA_ "Version" SG_ 2424579841 DATC_RrCtlLckSta "17.11.00";
BA_ "Description" SG_ 2424579841 DATC_DrvrStHtrUSMSta "If the 'Auto Comfort Control' function is applied separately to the Seat and Steering Wheel, 

this signal is used.";
BA_ "GenSigSendType" SG_ 2424579841 DATC_DrvrStHtrUSMSta 4;
BA_ "UserSigValidity" SG_ 2424579841 DATC_DrvrStHtrUSMSta 7;
BA_REL_ "GenSigTimeoutTime" BU_SG_REL_ APSU SG_ 2424579841 DATC_DrvrStHtrUSMSta 1500;
BA_REL_ "GenSigTimeoutTime" BU_SG_REL_ DPSU SG_ 2424579841 DATC_DrvrStHtrUSMSta 1500;
BA_ "Version" SG_ 2424579841 DATC_DrvrStHtrUSMSta "17.11.00";
BA_ "Description" SG_ 2424579841 DATC_InDrctVntUSMSta "This signal indicate Indirect Vent USM State.";
BA_ "GenSigSendType" SG_ 2424579841 DATC_InDrctVntUSMSta 4;
BA_ "UserSigValidity" SG_ 2424579841 DATC_InDrctVntUSMSta 3;
BA_ "Version" SG_ 2424579841 DATC_InDrctVntUSMSta "18.05.00";
BA_ "Description" SG_ 2424579841 DATC_WshFldUSMSta "This signal indicate Washer Fulid USM State.";
BA_ "GenSigSendType" SG_ 2424579841 DATC_WshFldUSMSta 4;
BA_ "UserSigValidity" SG_ 2424579841 DATC_WshFldUSMSta 7;
BA_ "Version" SG_ 2424579841 DATC_WshFldUSMSta "18.06.00";
BA_ "Description" SG_ 2424579841 DATC_DfgLgcUSMSta "This signal indicates USM States of DefLogic

(DEF ÇØÁ¦º¹±Í ·ÎÁ÷ USM ¼³Á¤°ª ¼Û½Å ½ÅÈ£)";
BA_ "GenSigSendType" SG_ 2424579841 DATC_DfgLgcUSMSta 4;
BA_ "GenSigStartValue" SG_ 2424579841 DATC_DfgLgcUSMSta 3;
BA_ "UserSigValidity" SG_ 2424579841 DATC_DfgLgcUSMSta 3;
BA_ "Version" SG_ 2424579841 DATC_DfgLgcUSMSta "18.07.03";
BA_ "Description" SG_ 2424579841 DATC_AutoFrshUSMSta "This signal indicates USM States of Auto Fresh

(°á·Î¹æÁö ÇØÁ¦ º¹±Í USM ¼³Á¤ »óÅÂ ¼Û½Å ½ÅÈ£)";
BA_ "GenSigSendType" SG_ 2424579841 DATC_AutoFrshUSMSta 4;
BA_ "GenSigStartValue" SG_ 2424579841 DATC_AutoFrshUSMSta 3;
BA_ "UserSigValidity" SG_ 2424579841 DATC_AutoFrshUSMSta 3;
BA_ "Version" SG_ 2424579841 DATC_AutoFrshUSMSta "18.07.03";
BA_ "Description" SG_ 2424579841 DATC_HptIntnstySta "This signal indicate the Haptic Intensity of Touch Button in the Heater Control.";
BA_ "GenSigSendType" SG_ 2424579841 DATC_HptIntnstySta 4;
BA_ "UserSigValidity" SG_ 2424579841 DATC_HptIntnstySta 7;
BA_ "Version" SG_ 2424579841 DATC_HptIntnstySta "18.11.01";
BA_ "Description" SG_ 2424579841 DATC_ClmtPwrSum_W "accumulated energy consumption while driving(200ms)";
BA_ "GenSigSendType" SG_ 2424579841 DATC_ClmtPwrSum_W 4;
BA_ "UserSigValidity" SG_ 2424579841 DATC_ClmtPwrSum_W 4;
BA_ "Version" SG_ 2424579841 DATC_ClmtPwrSum_W "18.09.00";
BA_ "GenMsgCycleTime" BO_ 1584 0;
BA_ "Description" SG_ 1584 AMP_NaviWarnSound "Navi Warning prompt on/off

Only ON during the Navi Warning Sound Playing

Default : Off

-This Signal's Feedback is AMP_NaviWarnModeState@AMP";
BA_ "GenSigSendType" SG_ 1584 AMP_NaviWarnSound 4;
BA_ "GenSigStartValue" SG_ 1584 AMP_NaviWarnSound 3;
BA_ "UserSigValidity" SG_ 1584 AMP_NaviWarnSound 1;
BA_ "Version" SG_ 1584 AMP_NaviWarnSound "21.04.10";
BA_ "Description" SG_ 1584 AMP_Beep1Mode "16.02.05_[Default Value]

0x0";
BA_ "GenSigSendType" SG_ 1584 AMP_Beep1Mode 4;
BA_ "GenSigStartValue" SG_ 1584 AMP_Beep1Mode 3;
BA_ "UserSigValidity" SG_ 1584 AMP_Beep1Mode 1;
BA_REL_ "GenSigTimeoutTime" BU_SG_REL_ ATS SG_ 1584 AMP_Beep1Mode 0;
BA_ "NetworkRequest" SG_ 1584 AMP_Beep1Mode 0;
BA_ "Version" SG_ 1584 AMP_Beep1Mode "18.12.06";
BA_ "Description" SG_ 1584 AMP_MasterBeepVolumeStep "MasterBeepVolumeStep (0/1/2/3/4/5)";
BA_ "GenSigSendType" SG_ 1584 AMP_MasterBeepVolumeStep 4;
BA_ "GenSigStartValue" SG_ 1584 AMP_MasterBeepVolumeStep 7;
BA_ "UserSigValidity" SG_ 1584 AMP_MasterBeepVolumeStep 1;
BA_ "NetworkRequest" SG_ 1584 AMP_MasterBeepVolumeStep 0;
BA_ "Version" SG_ 1584 AMP_MasterBeepVolumeStep "20.08.02";
BA_ "Description" SG_ 1584 AMP_SignalDoctor "16.02.05_[Default Value]

0x1";
BA_ "GenSigSendType" SG_ 1584 AMP_SignalDoctor 4;
BA_ "GenSigStartValue" SG_ 1584 AMP_SignalDoctor 3;
BA_ "UserSigValidity" SG_ 1584 AMP_SignalDoctor 1;
BA_ "Version" SG_ 1584 AMP_SignalDoctor "18.12.06";
BA_ "Description" SG_ 1584 AMP_RrTTSSound "This signal is  Rear TTS output state information";
BA_ "GenSigSendType" SG_ 1584 AMP_RrTTSSound 4;
BA_ "GenSigStartValue" SG_ 1584 AMP_RrTTSSound 3;
BA_ "UserSigValidity" SG_ 1584 AMP_RrTTSSound 1;
BA_ "Version" SG_ 1584 AMP_RrTTSSound "19.12.01";
BA_ "Description" SG_ 1584 AMP_ASDMode "16.04.01_HI : default value 0x01

DH PE : default value 0x03 (this signal used for DH PE eng mode asd setting)";
BA_ "GenSigSendType" SG_ 1584 AMP_ASDMode 4;
BA_ "GenSigStartValue" SG_ 1584 AMP_ASDMode 7;
BA_ "UserSigValidity" SG_ 1584 AMP_ASDMode 1;
BA_ "NetworkRequest" SG_ 1584 AMP_ASDMode 0;
BA_ "Version" SG_ 1584 AMP_ASDMode "18.12.06";
BA_ "Description" SG_ 1584 AMP_ANCMode "18.03.08_";
BA_ "GenSigSendType" SG_ 1584 AMP_ANCMode 4;
BA_ "GenSigStartValue" SG_ 1584 AMP_ANCMode 3;
BA_ "UserSigValidity" SG_ 1584 AMP_ANCMode 1;
BA_ "Version" SG_ 1584 AMP_ANCMode "18.12.06";
BA_ "Description" SG_ 1584 AMP_VirtualVenueMode "Select VV mode";
BA_ "GenSigSendType" SG_ 1584 AMP_VirtualVenueMode 4;
BA_ "GenSigStartValue" SG_ 1584 AMP_VirtualVenueMode 7;
BA_ "UserSigValidity" SG_ 1584 AMP_VirtualVenueMode 1;
BA_ "NetworkRequest" SG_ 1584 AMP_VirtualVenueMode 0;
BA_ "Version" SG_ 1584 AMP_VirtualVenueMode "19.08.08";
BA_ "Description" SG_ 1584 AMP_QLIMode "Select QLI mode";
BA_ "GenSigSendType" SG_ 1584 AMP_QLIMode 4;
BA_ "GenSigStartValue" SG_ 1584 AMP_QLIMode 7;
BA_ "UserSigValidity" SG_ 1584 AMP_QLIMode 1;
BA_ "NetworkRequest" SG_ 1584 AMP_QLIMode 0;
BA_ "Version" SG_ 1584 AMP_QLIMode "19.08.08";
BA_ "Description" SG_ 1584 AMP_DriverMode "Turn On/Off Driver mode";
BA_ "GenSigSendType" SG_ 1584 AMP_DriverMode 4;
BA_ "GenSigStartValue" SG_ 1584 AMP_DriverMode 3;
BA_ "UserSigValidity" SG_ 1584 AMP_DriverMode 1;
BA_ "NetworkRequest" SG_ 1584 AMP_DriverMode 0;
BA_ "Version" SG_ 1584 AMP_DriverMode "19.08.08";
BA_ "Description" SG_ 1584 AMP_NaviSound "16.02.05_[Default Value]

0x0";
BA_ "GenSigSendType" SG_ 1584 AMP_NaviSound 4;
BA_ "GenSigStartValue" SG_ 1584 AMP_NaviSound 3;
BA_ "UserSigValidity" SG_ 1584 AMP_NaviSound 1;
BA_ "Version" SG_ 1584 AMP_NaviSound "19.01.05";
BA_ "Description" SG_ 1584 AMP_VoiceGuideTTS "Play VoiceGuide TTS";
BA_ "GenSigSendType" SG_ 1584 AMP_VoiceGuideTTS 4;
BA_ "GenSigStartValue" SG_ 1584 AMP_VoiceGuideTTS 3;
BA_ "UserSigValidity" SG_ 1584 AMP_VoiceGuideTTS 1;
BA_ "NetworkRequest" SG_ 1584 AMP_VoiceGuideTTS 0;
BA_ "Version" SG_ 1584 AMP_VoiceGuideTTS "19.08.08";
BA_ "Description" SG_ 1584 AMP_Beep1KBDMode "Play touch beep sound at keyboard screen on AVN

This Signal's Feedback is AMP_Beep1KBDModeState@AMP";
BA_ "GenSigSendType" SG_ 1584 AMP_Beep1KBDMode 4;
BA_ "GenSigStartValue" SG_ 1584 AMP_Beep1KBDMode 3;
BA_ "UserSigValidity" SG_ 1584 AMP_Beep1KBDMode 1;
BA_ "Version" SG_ 1584 AMP_Beep1KBDMode "20.06.01";
BA_ "Description" SG_ 1584 AMP_NaviWarnVolumeStep "- Command for Navigation Warning Prompt Volume Setting

- This Signal's Feedback is AMP_NaviWarnVolumeState@AMP";
BA_ "GenSigSendType" SG_ 1584 AMP_NaviWarnVolumeStep 4;
BA_ "GenSigStartValue" SG_ 1584 AMP_NaviWarnVolumeStep 255;
BA_ "UserSigValidity" SG_ 1584 AMP_NaviWarnVolumeStep 1;
BA_ "Version" SG_ 1584 AMP_NaviWarnVolumeStep "21.04.10";
BA_ "Description" SG_ 1584 AMP_TTSSound "This signal is  TTS output state information";
BA_ "GenSigSendType" SG_ 1584 AMP_TTSSound 4;
BA_ "GenSigStartValue" SG_ 1584 AMP_TTSSound 3;
BA_ "UserSigValidity" SG_ 1584 AMP_TTSSound 1;
BA_ "Version" SG_ 1584 AMP_TTSSound "19.07.06";
BA_ "Description" SG_ 1584 AMP_SDVCStep "16.02.05_";
BA_ "GenSigSendType" SG_ 1584 AMP_SDVCStep 4;
BA_ "UserSigValidity" SG_ 1584 AMP_SDVCStep 1;
BA_ "NetworkRequest" SG_ 1584 AMP_SDVCStep 0;
BA_ "Version" SG_ 1584 AMP_SDVCStep "18.12.06";
BA_ "GenMsgSendType" BO_ 577 0;
BA_ "GenSigSendType" SG_ 577 C_AstBolsterInfSw_HU 4;
BA_ "UserSigValidity" SG_ 577 C_AstBolsterInfSw_HU 0;
BA_REL_ "GenSigTimeoutTime" BU_SG_REL_ ASAU SG_ 577 C_AstBolsterInfSw_HU 1500;
BA_REL_ "GenSigTimeoutTime" BU_SG_REL_ ALBCU SG_ 577 C_AstBolsterInfSw_HU 1500;
BA_ "Version" SG_ 577 C_AstBolsterInfSw_HU "19.11.09";
BA_ "GenSigSendType" SG_ 577 C_RLHrestUpSw_HU 4;
BA_ "UserSigValidity" SG_ 577 C_RLHrestUpSw_HU 0;
BA_REL_ "GenSigTimeoutTime" BU_SG_REL_ APSU SG_ 577 C_RLHrestUpSw_HU 1500;
BA_REL_ "GenSigTimeoutTime" BU_SG_REL_ RRPSU SG_ 577 C_RLHrestUpSw_HU 1500;
BA_REL_ "GenSigTimeoutTime" BU_SG_REL_ RLPSU SG_ 577 C_RLHrestUpSw_HU 1500;
BA_ "Version" SG_ 577 C_RLHrestUpSw_HU "19.11.09";
BA_ "GenSigSendType" SG_ 577 C_RLHrestDnSw_HU 4;
BA_ "UserSigValidity" SG_ 577 C_RLHrestDnSw_HU 0;
BA_REL_ "GenSigTimeoutTime" BU_SG_REL_ APSU SG_ 577 C_RLHrestDnSw_HU 1500;
BA_REL_ "GenSigTimeoutTime" BU_SG_REL_ RRPSU SG_ 577 C_RLHrestDnSw_HU 1500;
BA_REL_ "GenSigTimeoutTime" BU_SG_REL_ RLPSU SG_ 577 C_RLHrestDnSw_HU 1500;
BA_ "Version" SG_ 577 C_RLHrestDnSw_HU "19.11.09";
BA_ "GenSigSendType" SG_ 577 C_RLHrestFwdSw_HU 4;
BA_ "UserSigValidity" SG_ 577 C_RLHrestFwdSw_HU 0;
BA_REL_ "GenSigTimeoutTime" BU_SG_REL_ APSU SG_ 577 C_RLHrestFwdSw_HU 1500;
BA_REL_ "GenSigTimeoutTime" BU_SG_REL_ RRPSU SG_ 577 C_RLHrestFwdSw_HU 1500;
BA_REL_ "GenSigTimeoutTime" BU_SG_REL_ RLPSU SG_ 577 C_RLHrestFwdSw_HU 1500;
BA_ "Version" SG_ 577 C_RLHrestFwdSw_HU "19.11.09";
BA_ "GenSigSendType" SG_ 577 C_AstBolsterDefSw_HU 4;
BA_ "UserSigValidity" SG_ 577 C_AstBolsterDefSw_HU 0;
BA_REL_ "GenSigTimeoutTime" BU_SG_REL_ ASAU SG_ 577 C_AstBolsterDefSw_HU 1500;
BA_REL_ "GenSigTimeoutTime" BU_SG_REL_ ALBCU SG_ 577 C_AstBolsterDefSw_HU 1500;
BA_ "Version" SG_ 577 C_AstBolsterDefSw_HU "19.11.09";
BA_ "GenSigSendType" SG_ 577 C_RLHrestBwdSw_HU 4;
BA_ "UserSigValidity" SG_ 577 C_RLHrestBwdSw_HU 0;
BA_REL_ "GenSigTimeoutTime" BU_SG_REL_ APSU SG_ 577 C_RLHrestBwdSw_HU 1500;
BA_REL_ "GenSigTimeoutTime" BU_SG_REL_ RRPSU SG_ 577 C_RLHrestBwdSw_HU 1500;
BA_REL_ "GenSigTimeoutTime" BU_SG_REL_ RLPSU SG_ 577 C_RLHrestBwdSw_HU 1500;
BA_ "Version" SG_ 577 C_RLHrestBwdSw_HU "19.11.09";
BA_ "GenSigSendType" SG_ 577 C_RLLumbarUpSw_HU 4;
BA_ "UserSigValidity" SG_ 577 C_RLLumbarUpSw_HU 0;
BA_REL_ "GenSigTimeoutTime" BU_SG_REL_ RLPSU SG_ 577 C_RLLumbarUpSw_HU 1500;
BA_ "Version" SG_ 577 C_RLLumbarUpSw_HU "19.11.09";
BA_ "GenSigSendType" SG_ 577 C_RLLumbarMidSw_HU 4;
BA_ "UserSigValidity" SG_ 577 C_RLLumbarMidSw_HU 0;
BA_REL_ "GenSigTimeoutTime" BU_SG_REL_ RLPSU SG_ 577 C_RLLumbarMidSw_HU 1500;
BA_ "Version" SG_ 577 C_RLLumbarMidSw_HU "19.11.09";
BA_ "GenSigSendType" SG_ 577 C_RLLumbarLowSw_HU 4;
BA_ "UserSigValidity" SG_ 577 C_RLLumbarLowSw_HU 0;
BA_REL_ "GenSigTimeoutTime" BU_SG_REL_ RLPSU SG_ 577 C_RLLumbarLowSw_HU 1500;
BA_ "Version" SG_ 577 C_RLLumbarLowSw_HU "19.11.09";
BA_ "GenSigSendType" SG_ 577 C_RLLumbarDefSw_HU 4;
BA_ "UserSigValidity" SG_ 577 C_RLLumbarDefSw_HU 0;
BA_REL_ "GenSigTimeoutTime" BU_SG_REL_ RLPSU SG_ 577 C_RLLumbarDefSw_HU 1500;
BA_ "Version" SG_ 577 C_RLLumbarDefSw_HU "19.11.09";
BA_ "GenSigSendType" SG_ 577 C_RLBolsterInfSw_HU 4;
BA_ "UserSigValidity" SG_ 577 C_RLBolsterInfSw_HU 0;
BA_REL_ "GenSigTimeoutTime" BU_SG_REL_ RLPSU SG_ 577 C_RLBolsterInfSw_HU 1500;
BA_ "Version" SG_ 577 C_RLBolsterInfSw_HU "19.11.09";
BA_ "GenSigSendType" SG_ 577 C_RLBolsterDefSw_HU 4;
BA_ "UserSigValidity" SG_ 577 C_RLBolsterDefSw_HU 0;
BA_REL_ "GenSigTimeoutTime" BU_SG_REL_ RLPSU SG_ 577 C_RLBolsterDefSw_HU 1500;
BA_ "Version" SG_ 577 C_RLBolsterDefSw_HU "19.11.09";
BA_ "GenSigSendType" SG_ 577 C_AstHrestUpSw_HU 4;
BA_ "UserSigValidity" SG_ 577 C_AstHrestUpSw_HU 0;
BA_REL_ "GenSigTimeoutTime" BU_SG_REL_ APSU SG_ 577 C_AstHrestUpSw_HU 1500;
BA_ "Version" SG_ 577 C_AstHrestUpSw_HU "19.11.09";
BA_ "GenSigSendType" SG_ 577 C_AstHrestDnSw_HU 4;
BA_ "UserSigValidity" SG_ 577 C_AstHrestDnSw_HU 0;
BA_REL_ "GenSigTimeoutTime" BU_SG_REL_ APSU SG_ 577 C_AstHrestDnSw_HU 1500;
BA_ "Version" SG_ 577 C_AstHrestDnSw_HU "19.11.09";
BA_ "GenSigSendType" SG_ 577 C_AstFootrestFldSw_HU 4;
BA_ "UserSigValidity" SG_ 577 C_AstFootrestFldSw_HU 0;
BA_REL_ "GenSigTimeoutTime" BU_SG_REL_ APSU SG_ 577 C_AstFootrestFldSw_HU 1500;
BA_ "Version" SG_ 577 C_AstFootrestFldSw_HU "19.11.09";
BA_ "GenSigSendType" SG_ 577 C_AstHrestFwdSw_HU 4;
BA_ "UserSigValidity" SG_ 577 C_AstHrestFwdSw_HU 0;
BA_REL_ "GenSigTimeoutTime" BU_SG_REL_ APSU SG_ 577 C_AstHrestFwdSw_HU 1500;
BA_ "Version" SG_ 577 C_AstHrestFwdSw_HU "19.11.09";
BA_ "GenSigSendType" SG_ 577 C_AstHrestBwdSw_HU 4;
BA_ "UserSigValidity" SG_ 577 C_AstHrestBwdSw_HU 0;
BA_REL_ "GenSigTimeoutTime" BU_SG_REL_ APSU SG_ 577 C_AstHrestBwdSw_HU 1500;
BA_ "Version" SG_ 577 C_AstHrestBwdSw_HU "19.11.09";
BA_ "GenSigSendType" SG_ 577 C_AstFootrestUnFldSw_HU 4;
BA_ "UserSigValidity" SG_ 577 C_AstFootrestUnFldSw_HU 0;
BA_REL_ "GenSigTimeoutTime" BU_SG_REL_ APSU SG_ 577 C_AstFootrestUnFldSw_HU 1500;
BA_ "Version" SG_ 577 C_AstFootrestUnFldSw_HU "19.11.09";
BA_ "GenMsgSendType" BO_ 578 0;
BA_ "GenSigSendType" SG_ 578 C_RRLegSupFwdSw_HU 4;
BA_ "UserSigValidity" SG_ 578 C_RRLegSupFwdSw_HU 0;
BA_REL_ "GenSigTimeoutTime" BU_SG_REL_ APSU SG_ 578 C_RRLegSupFwdSw_HU 1500;
BA_REL_ "GenSigTimeoutTime" BU_SG_REL_ RRPSU SG_ 578 C_RRLegSupFwdSw_HU 1500;
BA_REL_ "GenSigTimeoutTime" BU_SG_REL_ RLPSU SG_ 578 C_RRLegSupFwdSw_HU 1500;
BA_ "Version" SG_ 578 C_RRLegSupFwdSw_HU "19.11.09";
BA_ "GenSigSendType" SG_ 578 C_RRHrestDnSw_HU 4;
BA_ "UserSigValidity" SG_ 578 C_RRHrestDnSw_HU 0;
BA_REL_ "GenSigTimeoutTime" BU_SG_REL_ APSU SG_ 578 C_RRHrestDnSw_HU 1500;
BA_REL_ "GenSigTimeoutTime" BU_SG_REL_ RRPSU SG_ 578 C_RRHrestDnSw_HU 1500;
BA_REL_ "GenSigTimeoutTime" BU_SG_REL_ RLPSU SG_ 578 C_RRHrestDnSw_HU 1500;
BA_ "Version" SG_ 578 C_RRHrestDnSw_HU "19.11.09";
BA_ "GenSigSendType" SG_ 578 C_RRHrestFwdSw_HU 4;
BA_ "UserSigValidity" SG_ 578 C_RRHrestFwdSw_HU 0;
BA_REL_ "GenSigTimeoutTime" BU_SG_REL_ APSU SG_ 578 C_RRHrestFwdSw_HU 1500;
BA_REL_ "GenSigTimeoutTime" BU_SG_REL_ RRPSU SG_ 578 C_RRHrestFwdSw_HU 1500;
BA_REL_ "GenSigTimeoutTime" BU_SG_REL_ RLPSU SG_ 578 C_RRHrestFwdSw_HU 1500;
BA_ "Version" SG_ 578 C_RRHrestFwdSw_HU "19.11.09";
BA_ "GenSigSendType" SG_ 578 C_RRHrestBwdSw_HU 4;
BA_ "UserSigValidity" SG_ 578 C_RRHrestBwdSw_HU 0;
BA_REL_ "GenSigTimeoutTime" BU_SG_REL_ APSU SG_ 578 C_RRHrestBwdSw_HU 1500;
BA_REL_ "GenSigTimeoutTime" BU_SG_REL_ RRPSU SG_ 578 C_RRHrestBwdSw_HU 1500;
BA_REL_ "GenSigTimeoutTime" BU_SG_REL_ RLPSU SG_ 578 C_RRHrestBwdSw_HU 1500;
BA_ "Version" SG_ 578 C_RRHrestBwdSw_HU "19.11.09";
BA_ "GenSigSendType" SG_ 578 C_RRLumbarUpSw_HU 4;
BA_ "UserSigValidity" SG_ 578 C_RRLumbarUpSw_HU 0;
BA_REL_ "GenSigTimeoutTime" BU_SG_REL_ APSU SG_ 578 C_RRLumbarUpSw_HU 1500;
BA_REL_ "GenSigTimeoutTime" BU_SG_REL_ RRPSU SG_ 578 C_RRLumbarUpSw_HU 1500;
BA_ "Version" SG_ 578 C_RRLumbarUpSw_HU "19.11.09";
BA_ "GenSigSendType" SG_ 578 C_RRLumbarMidSw_HU 4;
BA_ "UserSigValidity" SG_ 578 C_RRLumbarMidSw_HU 0;
BA_REL_ "GenSigTimeoutTime" BU_SG_REL_ APSU SG_ 578 C_RRLumbarMidSw_HU 1500;
BA_REL_ "GenSigTimeoutTime" BU_SG_REL_ RRPSU SG_ 578 C_RRLumbarMidSw_HU 1500;
BA_ "Version" SG_ 578 C_RRLumbarMidSw_HU "19.11.09";
BA_ "GenSigSendType" SG_ 578 C_RRLegSupBwdSw_HU 4;
BA_ "UserSigValidity" SG_ 578 C_RRLegSupBwdSw_HU 0;
BA_REL_ "GenSigTimeoutTime" BU_SG_REL_ APSU SG_ 578 C_RRLegSupBwdSw_HU 1500;
BA_REL_ "GenSigTimeoutTime" BU_SG_REL_ RRPSU SG_ 578 C_RRLegSupBwdSw_HU 1500;
BA_REL_ "GenSigTimeoutTime" BU_SG_REL_ RLPSU SG_ 578 C_RRLegSupBwdSw_HU 1500;
BA_ "Version" SG_ 578 C_RRLegSupBwdSw_HU "19.11.09";
BA_ "GenSigSendType" SG_ 578 C_RRLumbarLowSw_HU 4;
BA_ "UserSigValidity" SG_ 578 C_RRLumbarLowSw_HU 0;
BA_REL_ "GenSigTimeoutTime" BU_SG_REL_ APSU SG_ 578 C_RRLumbarLowSw_HU 1500;
BA_REL_ "GenSigTimeoutTime" BU_SG_REL_ RRPSU SG_ 578 C_RRLumbarLowSw_HU 1500;
BA_ "Version" SG_ 578 C_RRLumbarLowSw_HU "19.11.09";
BA_ "GenSigSendType" SG_ 578 C_RRLumbarDefSw_HU 4;
BA_ "UserSigValidity" SG_ 578 C_RRLumbarDefSw_HU 0;
BA_REL_ "GenSigTimeoutTime" BU_SG_REL_ APSU SG_ 578 C_RRLumbarDefSw_HU 1500;
BA_REL_ "GenSigTimeoutTime" BU_SG_REL_ RRPSU SG_ 578 C_RRLumbarDefSw_HU 1500;
BA_ "Version" SG_ 578 C_RRLumbarDefSw_HU "19.11.09";
BA_ "GenSigSendType" SG_ 578 C_RRBolsterInfSw_HU 4;
BA_ "UserSigValidity" SG_ 578 C_RRBolsterInfSw_HU 0;
BA_REL_ "GenSigTimeoutTime" BU_SG_REL_ APSU SG_ 578 C_RRBolsterInfSw_HU 1500;
BA_REL_ "GenSigTimeoutTime" BU_SG_REL_ RRPSU SG_ 578 C_RRBolsterInfSw_HU 1500;
BA_ "Version" SG_ 578 C_RRBolsterInfSw_HU "19.11.09";
BA_ "GenSigSendType" SG_ 578 C_RRLegSupUpSw_HU 4;
BA_ "UserSigValidity" SG_ 578 C_RRLegSupUpSw_HU 0;
BA_REL_ "GenSigTimeoutTime" BU_SG_REL_ APSU SG_ 578 C_RRLegSupUpSw_HU 1500;
BA_REL_ "GenSigTimeoutTime" BU_SG_REL_ RRPSU SG_ 578 C_RRLegSupUpSw_HU 1500;
BA_REL_ "GenSigTimeoutTime" BU_SG_REL_ RLPSU SG_ 578 C_RRLegSupUpSw_HU 1500;
BA_ "Version" SG_ 578 C_RRLegSupUpSw_HU "19.11.09";
BA_ "GenSigSendType" SG_ 578 C_RROneTchNValueSet 4;
BA_ "UserSigValidity" SG_ 578 C_RROneTchNValueSet 0;
BA_REL_ "GenSigTimeoutTime" BU_SG_REL_ APSU SG_ 578 C_RROneTchNValueSet 1500;
BA_REL_ "GenSigTimeoutTime" BU_SG_REL_ RRPSU SG_ 578 C_RROneTchNValueSet 1500;
BA_REL_ "GenSigTimeoutTime" BU_SG_REL_ RLPSU SG_ 578 C_RROneTchNValueSet 1500;
BA_REL_ "GenSigTimeoutTime" BU_SG_REL_ ATS SG_ 578 C_RROneTchNValueSet 1500;
BA_ "Version" SG_ 578 C_RROneTchNValueSet "19.11.09";
BA_ "GenSigSendType" SG_ 578 C_RLOneTchNValueSet 4;
BA_ "UserSigValidity" SG_ 578 C_RLOneTchNValueSet 0;
BA_REL_ "GenSigTimeoutTime" BU_SG_REL_ APSU SG_ 578 C_RLOneTchNValueSet 1500;
BA_REL_ "GenSigTimeoutTime" BU_SG_REL_ RRPSU SG_ 578 C_RLOneTchNValueSet 1500;
BA_REL_ "GenSigTimeoutTime" BU_SG_REL_ RLPSU SG_ 578 C_RLOneTchNValueSet 1500;
BA_REL_ "GenSigTimeoutTime" BU_SG_REL_ ATS SG_ 578 C_RLOneTchNValueSet 1500;
BA_ "Version" SG_ 578 C_RLOneTchNValueSet "19.11.09";
BA_ "GenSigSendType" SG_ 578 C_RRBolsterDefSw_HU 4;
BA_ "UserSigValidity" SG_ 578 C_RRBolsterDefSw_HU 0;
BA_REL_ "GenSigTimeoutTime" BU_SG_REL_ APSU SG_ 578 C_RRBolsterDefSw_HU 1500;
BA_REL_ "GenSigTimeoutTime" BU_SG_REL_ RRPSU SG_ 578 C_RRBolsterDefSw_HU 1500;
BA_ "Version" SG_ 578 C_RRBolsterDefSw_HU "19.11.09";
BA_ "GenSigSendType" SG_ 578 C_AstRlxTiltUpSw_HU 4;
BA_ "UserSigValidity" SG_ 578 C_AstRlxTiltUpSw_HU 0;
BA_REL_ "GenSigTimeoutTime" BU_SG_REL_ APSU SG_ 578 C_AstRlxTiltUpSw_HU 1500;
BA_ "Version" SG_ 578 C_AstRlxTiltUpSw_HU "19.12.02";
BA_ "GenSigSendType" SG_ 578 C_AstRlxTiltDnSw_HU 4;
BA_ "UserSigValidity" SG_ 578 C_AstRlxTiltDnSw_HU 0;
BA_REL_ "GenSigTimeoutTime" BU_SG_REL_ APSU SG_ 578 C_AstRlxTiltDnSw_HU 1500;
BA_ "Version" SG_ 578 C_AstRlxTiltDnSw_HU "19.12.02";
BA_ "GenSigSendType" SG_ 578 C_RLRSEUpSw_HU 4;
BA_ "UserSigValidity" SG_ 578 C_RLRSEUpSw_HU 0;
BA_REL_ "GenSigTimeoutTime" BU_SG_REL_ APSU SG_ 578 C_RLRSEUpSw_HU 1500;
BA_REL_ "GenSigTimeoutTime" BU_SG_REL_ RRPSU SG_ 578 C_RLRSEUpSw_HU 1500;
BA_REL_ "GenSigTimeoutTime" BU_SG_REL_ RLPSU SG_ 578 C_RLRSEUpSw_HU 1500;
BA_ "Version" SG_ 578 C_RLRSEUpSw_HU "19.12.02";
BA_ "GenSigSendType" SG_ 578 C_RLRSEDnSw_HU 4;
BA_ "UserSigValidity" SG_ 578 C_RLRSEDnSw_HU 0;
BA_REL_ "GenSigTimeoutTime" BU_SG_REL_ APSU SG_ 578 C_RLRSEDnSw_HU 1500;
BA_REL_ "GenSigTimeoutTime" BU_SG_REL_ RRPSU SG_ 578 C_RLRSEDnSw_HU 1500;
BA_REL_ "GenSigTimeoutTime" BU_SG_REL_ RLPSU SG_ 578 C_RLRSEDnSw_HU 1500;
BA_ "Version" SG_ 578 C_RLRSEDnSw_HU "19.12.02";
BA_ "GenSigSendType" SG_ 578 C_RRRSEUpSw_HU 4;
BA_ "UserSigValidity" SG_ 578 C_RRRSEUpSw_HU 0;
BA_REL_ "GenSigTimeoutTime" BU_SG_REL_ APSU SG_ 578 C_RRRSEUpSw_HU 1500;
BA_REL_ "GenSigTimeoutTime" BU_SG_REL_ RRPSU SG_ 578 C_RRRSEUpSw_HU 1500;
BA_REL_ "GenSigTimeoutTime" BU_SG_REL_ RLPSU SG_ 578 C_RRRSEUpSw_HU 1500;
BA_ "Version" SG_ 578 C_RRRSEUpSw_HU "19.12.02";
BA_ "GenSigSendType" SG_ 578 C_RRLegSupDnSw_HU 4;
BA_ "UserSigValidity" SG_ 578 C_RRLegSupDnSw_HU 0;
BA_REL_ "GenSigTimeoutTime" BU_SG_REL_ APSU SG_ 578 C_RRLegSupDnSw_HU 1500;
BA_REL_ "GenSigTimeoutTime" BU_SG_REL_ RRPSU SG_ 578 C_RRLegSupDnSw_HU 1500;
BA_REL_ "GenSigTimeoutTime" BU_SG_REL_ RLPSU SG_ 578 C_RRLegSupDnSw_HU 1500;
BA_ "Version" SG_ 578 C_RRLegSupDnSw_HU "19.11.09";
BA_ "GenSigSendType" SG_ 578 C_RRRSEDnSw_HU 4;
BA_ "UserSigValidity" SG_ 578 C_RRRSEDnSw_HU 0;
BA_REL_ "GenSigTimeoutTime" BU_SG_REL_ APSU SG_ 578 C_RRRSEDnSw_HU 1500;
BA_REL_ "GenSigTimeoutTime" BU_SG_REL_ RRPSU SG_ 578 C_RRRSEDnSw_HU 1500;
BA_REL_ "GenSigTimeoutTime" BU_SG_REL_ RLPSU SG_ 578 C_RRRSEDnSw_HU 1500;
BA_ "Version" SG_ 578 C_RRRSEDnSw_HU "19.12.02";
BA_ "GenSigSendType" SG_ 578 C_RRHrestUpSw_HU 4;
BA_ "UserSigValidity" SG_ 578 C_RRHrestUpSw_HU 0;
BA_REL_ "GenSigTimeoutTime" BU_SG_REL_ APSU SG_ 578 C_RRHrestUpSw_HU 1500;
BA_REL_ "GenSigTimeoutTime" BU_SG_REL_ RRPSU SG_ 578 C_RRHrestUpSw_HU 1500;
BA_REL_ "GenSigTimeoutTime" BU_SG_REL_ RLPSU SG_ 578 C_RRHrestUpSw_HU 1500;
BA_ "Version" SG_ 578 C_RRHrestUpSw_HU "19.11.09";
BA_ "GenMsgSendType" BO_ 2281833729 0;
BA_ "GenMsgCycleTimeFast" BO_ 2281833729 0;
BA_ "GenMsgNrOfRepetition" BO_ 2281833729 0;
BA_ "VFrameFormat" BO_ 2281833729 1;
BA_ "Description" SG_ 2281833729 ICSC_Crc2Val "The data area for CRC calculation is based on the data length (DLC) of the message DB.

The CRC shall be calculated over the entire data block (excluding the CRC bytes) including the user data, alive counter and Data ID

 

- CRC Polynomial (0x1021) , Initial Value : 0xFFFF, XOR value : 0x0000, Data ID : Message ID + 0xF800 

- The initial value is for CRC calculation and the message should be sent with the calculated result value. 

- The mathematical expression to 16 bit CRC polynomial is given here. G(x) = x16 + x12 + x5 + 1";
BA_ "GenSigStartValue" SG_ 2281833729 ICSC_Crc2Val 65535;
BA_ "UserSigValidity" SG_ 2281833729 ICSC_Crc2Val 3;
BA_ "RoutingFactor" SG_ 2281833729 ICSC_Crc2Val 2;
BA_ "Version" SG_ 2281833729 ICSC_Crc2Val "18.11.08";
BA_ "Description" SG_ 2281833729 ICSC_AlvCnt2Val "For the first transmission request for a data element the counter shall be initialized with 0 and shall be incremented by 1 for every subsequent send request. 

When the counter reaches the maximum value(0xFF), then it shall restart with 0 for the next send request";
BA_ "UserSigValidity" SG_ 2281833729 ICSC_AlvCnt2Val 3;
BA_ "RoutingFactor" SG_ 2281833729 ICSC_AlvCnt2Val 2;
BA_ "Version" SG_ 2281833729 ICSC_AlvCnt2Val "18.11.08";
BA_ "Description" SG_ 2281833729 DMIC_DrvModSta "This signal is feedback state of driving mode for Cluster/AVN

This message is for DMIC(Driving Mode Integrated Control)";
BA_ "UserSigValidity" SG_ 2281833729 DMIC_DrvModSta 3;
BA_REL_ "GenSigTimeoutTime" BU_SG_REL_ APSU SG_ 2281833729 DMIC_DrvModSta 1500;
BA_REL_ "GenSigTimeoutTime" BU_SG_REL_ DLBCU SG_ 2281833729 DMIC_DrvModSta 1500;
BA_REL_ "GenSigTimeoutTime" BU_SG_REL_ DSAU SG_ 2281833729 DMIC_DrvModSta 1500;
BA_REL_ "GenSigTimeoutTime" BU_SG_REL_ ASAU SG_ 2281833729 DMIC_DrvModSta 1500;
BA_REL_ "GenSigTimeoutTime" BU_SG_REL_ ALBCU SG_ 2281833729 DMIC_DrvModSta 1500;
BA_ "RoutingFactor" SG_ 2281833729 DMIC_DrvModSta 2;
BA_ "Version" SG_ 2281833729 DMIC_DrvModSta "20.07.10";
BA_ "Description" SG_ 2281833729 DMIC_SmtShftModSta "This signal is a smart shift mode flag.";
BA_ "UserSigValidity" SG_ 2281833729 DMIC_SmtShftModSta 3;
BA_ "RoutingFactor" SG_ 2281833729 DMIC_SmtShftModSta 2;
BA_ "Version" SG_ 2281833729 DMIC_SmtShftModSta "17.12.00";
BA_ "Description" SG_ 2281833729 DMIC_EngModSta "This Signal is the request on mode transition for Controlling the Driving Mode.";
BA_ "UserSigValidity" SG_ 2281833729 DMIC_EngModSta 3;
BA_ "RoutingFactor" SG_ 2281833729 DMIC_EngModSta 2;
BA_ "Version" SG_ 2281833729 DMIC_EngModSta "20.05.02";
BA_ "Description" SG_ 2281833729 DMIC_IndEngModSta "This signal is for feedback about individual mode setting on AVN.";
BA_ "UserSigValidity" SG_ 2281833729 DMIC_IndEngModSta 3;
BA_ "RoutingFactor" SG_ 2281833729 DMIC_IndEngModSta 2;
BA_ "Version" SG_ 2281833729 DMIC_IndEngModSta "19.09.00";
BA_ "Description" SG_ 2281833729 DMIC_TmModSta "This Signal is the request on mode transition for Controlling the Driving Mode.";
BA_ "UserSigValidity" SG_ 2281833729 DMIC_TmModSta 3;
BA_ "RoutingFactor" SG_ 2281833729 DMIC_TmModSta 2;
BA_ "Version" SG_ 2281833729 DMIC_TmModSta "20.05.02";
BA_ "Description" SG_ 2281833729 DMIC_IndTmModSta "This signal is for feedback about individual mode setting on AVN.";
BA_ "UserSigValidity" SG_ 2281833729 DMIC_IndTmModSta 3;
BA_ "RoutingFactor" SG_ 2281833729 DMIC_IndTmModSta 2;
BA_ "Version" SG_ 2281833729 DMIC_IndTmModSta "19.09.00";
BA_ "Description" SG_ 2281833729 DMIC_EscModSta "This Signal is the request on mode transition for Controlling the Driving Mode.";
BA_ "UserSigValidity" SG_ 2281833729 DMIC_EscModSta 3;
BA_ "RoutingFactor" SG_ 2281833729 DMIC_EscModSta 2;
BA_ "Version" SG_ 2281833729 DMIC_EscModSta "20.05.02";
BA_ "Description" SG_ 2281833729 DMIC_IndEscModSta "This signal is for feedback about individual mode setting on AVN.";
BA_ "UserSigValidity" SG_ 2281833729 DMIC_IndEscModSta 3;
BA_ "RoutingFactor" SG_ 2281833729 DMIC_IndEscModSta 2;
BA_ "Version" SG_ 2281833729 DMIC_IndEscModSta "17.12.00";
BA_ "Description" SG_ 2281833729 DMIC_MdpsModSta "This Signal is the request on mode transition for Controlling the Driving Mode.";
BA_ "UserSigValidity" SG_ 2281833729 DMIC_MdpsModSta 3;
BA_ "RoutingFactor" SG_ 2281833729 DMIC_MdpsModSta 2;
BA_ "Version" SG_ 2281833729 DMIC_MdpsModSta "20.05.02";
BA_ "Description" SG_ 2281833729 DMIC_IndMdpsModSta "This signal is for feedback about individual mode setting on AVN.";
BA_ "UserSigValidity" SG_ 2281833729 DMIC_IndMdpsModSta 3;
BA_ "RoutingFactor" SG_ 2281833729 DMIC_IndMdpsModSta 2;
BA_ "Version" SG_ 2281833729 DMIC_IndMdpsModSta "19.09.00";
BA_ "GenMsgSendType" BO_ 2281833730 0;
BA_ "GenMsgCycleTimeFast" BO_ 2281833730 0;
BA_ "GenMsgNrOfRepetition" BO_ 2281833730 0;
BA_ "VFrameFormat" BO_ 2281833730 1;
BA_ "Description" SG_ 2281833730 DMIC_EcsModSta "This Signal is the request on mode transition for Controlling the Driving Mode.";
BA_ "UserSigValidity" SG_ 2281833730 DMIC_EcsModSta 3;
BA_ "RoutingFactor" SG_ 2281833730 DMIC_EcsModSta 2;
BA_ "Version" SG_ 2281833730 DMIC_EcsModSta "20.05.02";
BA_ "Description" SG_ 2281833730 DMIC_IndAwdModSta "This signal is for feedback about individual mode setting on AVN.";
BA_ "UserSigValidity" SG_ 2281833730 DMIC_IndAwdModSta 3;
BA_ "RoutingFactor" SG_ 2281833730 DMIC_IndAwdModSta 2;
BA_ "Version" SG_ 2281833730 DMIC_IndAwdModSta "17.12.00";
BA_ "Description" SG_ 2281833730 DMIC_RevModSta "This Signal is the request on mode transition for Controlling the Driving Mode.";
BA_ "UserSigValidity" SG_ 2281833730 DMIC_RevModSta 3;
BA_ "RoutingFactor" SG_ 2281833730 DMIC_RevModSta 2;
BA_ "Version" SG_ 2281833730 DMIC_RevModSta "20.05.02";
BA_ "Description" SG_ 2281833730 DMIC_IndRevModSta "This signal is for feedback about individual mode setting on AVN.";
BA_ "UserSigValidity" SG_ 2281833730 DMIC_IndRevModSta 3;
BA_ "RoutingFactor" SG_ 2281833730 DMIC_IndRevModSta 2;
BA_ "Version" SG_ 2281833730 DMIC_IndRevModSta "17.12.00";
BA_ "Description" SG_ 2281833730 DMIC_PrflModSta "This Signal is the request on mode transition for Controlling the Driving Mode.";
BA_ "UserSigValidity" SG_ 2281833730 DMIC_PrflModSta 3;
BA_ "RoutingFactor" SG_ 2281833730 DMIC_PrflModSta 2;
BA_ "Version" SG_ 2281833730 DMIC_PrflModSta "17.12.00";
BA_ "Description" SG_ 2281833730 DMIC_IndPrflModSta "This signal is for feedback about individual mode setting on AVN.";
BA_ "UserSigValidity" SG_ 2281833730 DMIC_IndPrflModSta 3;
BA_ "RoutingFactor" SG_ 2281833730 DMIC_IndPrflModSta 2;
BA_ "Version" SG_ 2281833730 DMIC_IndPrflModSta "17.12.00";
BA_ "Description" SG_ 2281833730 DMIC_ElsdModSta "This Signal is the request on mode transition for Controlling the Driving Mode.";
BA_ "UserSigValidity" SG_ 2281833730 DMIC_ElsdModSta 3;
BA_ "RoutingFactor" SG_ 2281833730 DMIC_ElsdModSta 2;
BA_ "Version" SG_ 2281833730 DMIC_ElsdModSta "20.05.02";
BA_ "Description" SG_ 2281833730 DMIC_IndElsdModSta "This signal is for feedback about individual mode setting on AVN.";
BA_ "UserSigValidity" SG_ 2281833730 DMIC_IndElsdModSta 3;
BA_ "RoutingFactor" SG_ 2281833730 DMIC_IndElsdModSta 2;
BA_ "Version" SG_ 2281833730 DMIC_IndElsdModSta "17.12.00";
BA_ "Description" SG_ 2281833730 DMIC_IndEcsModSta "This signal is for feedback about individual mode setting on AVN.";
BA_ "UserSigValidity" SG_ 2281833730 DMIC_IndEcsModSta 3;
BA_ "RoutingFactor" SG_ 2281833730 DMIC_IndEcsModSta 2;
BA_ "Version" SG_ 2281833730 DMIC_IndEcsModSta "19.09.00";
BA_ "Description" SG_ 2281833730 DMIC_EsndModSta "This Signal is the request on mode transition for Controlling the Driving Mode.";
BA_ "UserSigValidity" SG_ 2281833730 DMIC_EsndModSta 3;
BA_ "RoutingFactor" SG_ 2281833730 DMIC_EsndModSta 2;
BA_ "Version" SG_ 2281833730 DMIC_EsndModSta "20.05.02";
BA_ "Description" SG_ 2281833730 DMIC_IndEsndModSta "This signal is for feedback about individual mode setting on AVN.";
BA_ "UserSigValidity" SG_ 2281833730 DMIC_IndEsndModSta 3;
BA_ "RoutingFactor" SG_ 2281833730 DMIC_IndEsndModSta 2;
BA_ "Version" SG_ 2281833730 DMIC_IndEsndModSta "17.12.00";
BA_ "Description" SG_ 2281833730 DMIC_RwsModSta "This Signal is the request on mode transition for Controlling the Driving Mode.";
BA_ "UserSigValidity" SG_ 2281833730 DMIC_RwsModSta 3;
BA_ "RoutingFactor" SG_ 2281833730 DMIC_RwsModSta 2;
BA_ "Version" SG_ 2281833730 DMIC_RwsModSta "20.05.02";
BA_ "Description" SG_ 2281833730 DMIC_IndRwsModSta "This signal is for feedback about individual mode setting on AVN.";
BA_ "UserSigValidity" SG_ 2281833730 DMIC_IndRwsModSta 3;
BA_ "RoutingFactor" SG_ 2281833730 DMIC_IndRwsModSta 2;
BA_ "Version" SG_ 2281833730 DMIC_IndRwsModSta "17.11.00";
BA_ "Description" SG_ 2281833730 DMIC_AwdModSta "This Signal is the request on mode transition for Controlling the Driving Mode.";
BA_ "UserSigValidity" SG_ 2281833730 DMIC_AwdModSta 3;
BA_ "RoutingFactor" SG_ 2281833730 DMIC_AwdModSta 2;
BA_ "Version" SG_ 2281833730 DMIC_AwdModSta "20.05.02";
BA_ "GenMsgSendType" BO_ 2281833731 0;
BA_ "GenMsgCycleTimeFast" BO_ 2281833731 0;
BA_ "GenMsgNrOfRepetition" BO_ 2281833731 0;
BA_ "VFrameFormat" BO_ 2281833731 1;
BA_ "Description" SG_ 2281833731 DMIC_VcuModSta "This Signal is the request on mode transition for Controlling the Driving Mode.";
BA_ "UserSigValidity" SG_ 2281833731 DMIC_VcuModSta 3;
BA_ "RoutingFactor" SG_ 2281833731 DMIC_VcuModSta 2;
BA_ "Version" SG_ 2281833731 DMIC_VcuModSta "20.05.02";
BA_ "Description" SG_ 2281833731 DMIC_DrvModTyp "This signal indicates drive mode type.";
BA_ "UserSigValidity" SG_ 2281833731 DMIC_DrvModTyp 3;
BA_ "RoutingFactor" SG_ 2281833731 DMIC_DrvModTyp 2;
BA_ "Version" SG_ 2281833731 DMIC_DrvModTyp "19.11.05";
BA_ "Description" SG_ 2281833731 DMIC_EngFltSta "This signal indicates fault status of individual systems.";
BA_ "UserSigValidity" SG_ 2281833731 DMIC_EngFltSta 3;
BA_ "RoutingFactor" SG_ 2281833731 DMIC_EngFltSta 2;
BA_ "Version" SG_ 2281833731 DMIC_EngFltSta "17.12.00";
BA_ "Description" SG_ 2281833731 DMIC_TmFltSta "This signal indicates fault status of individual systems.";
BA_ "UserSigValidity" SG_ 2281833731 DMIC_TmFltSta 3;
BA_ "RoutingFactor" SG_ 2281833731 DMIC_TmFltSta 2;
BA_ "Version" SG_ 2281833731 DMIC_TmFltSta "17.12.00";
BA_ "Description" SG_ 2281833731 DMIC_EscFltSta "This signal indicates fault status of individual systems.";
BA_ "UserSigValidity" SG_ 2281833731 DMIC_EscFltSta 3;
BA_ "RoutingFactor" SG_ 2281833731 DMIC_EscFltSta 2;
BA_ "Version" SG_ 2281833731 DMIC_EscFltSta "17.12.00";
BA_ "Description" SG_ 2281833731 DMIC_MdpsFltSta "This signal indicates fault status of individual systems.";
BA_ "UserSigValidity" SG_ 2281833731 DMIC_MdpsFltSta 3;
BA_ "RoutingFactor" SG_ 2281833731 DMIC_MdpsFltSta 2;
BA_ "Version" SG_ 2281833731 DMIC_MdpsFltSta "17.12.00";
BA_ "Description" SG_ 2281833731 DMIC_EcsFltSta "This signal indicates fault status of individual systems.";
BA_ "UserSigValidity" SG_ 2281833731 DMIC_EcsFltSta 3;
BA_ "RoutingFactor" SG_ 2281833731 DMIC_EcsFltSta 2;
BA_ "Version" SG_ 2281833731 DMIC_EcsFltSta "17.12.00";
BA_ "Description" SG_ 2281833731 DMIC_AwdFltSta "This signal indicates fault status of individual systems.";
BA_ "UserSigValidity" SG_ 2281833731 DMIC_AwdFltSta 3;
BA_ "RoutingFactor" SG_ 2281833731 DMIC_AwdFltSta 2;
BA_ "Version" SG_ 2281833731 DMIC_AwdFltSta "17.12.00";
BA_ "Description" SG_ 2281833731 DMIC_RevFltSta "This signal indicates fault status of individual systems.";
BA_ "UserSigValidity" SG_ 2281833731 DMIC_RevFltSta 3;
BA_ "RoutingFactor" SG_ 2281833731 DMIC_RevFltSta 2;
BA_ "Version" SG_ 2281833731 DMIC_RevFltSta "17.12.00";
BA_ "Description" SG_ 2281833731 DMIC_PrflFltSta "This signal indicates fault status of individual systems.";
BA_ "UserSigValidity" SG_ 2281833731 DMIC_PrflFltSta 3;
BA_ "RoutingFactor" SG_ 2281833731 DMIC_PrflFltSta 2;
BA_ "Version" SG_ 2281833731 DMIC_PrflFltSta "17.12.00";
BA_ "Description" SG_ 2281833731 DMIC_ElsdFltSta "This signal indicates fault status of individual systems.";
BA_ "UserSigValidity" SG_ 2281833731 DMIC_ElsdFltSta 3;
BA_ "RoutingFactor" SG_ 2281833731 DMIC_ElsdFltSta 2;
BA_ "Version" SG_ 2281833731 DMIC_ElsdFltSta "17.12.00";
BA_ "Description" SG_ 2281833731 DMIC_EsndFltSta "This signal indicates fault status of individual systems.";
BA_ "UserSigValidity" SG_ 2281833731 DMIC_EsndFltSta 3;
BA_ "RoutingFactor" SG_ 2281833731 DMIC_EsndFltSta 2;
BA_ "Version" SG_ 2281833731 DMIC_EsndFltSta "17.12.00";
BA_ "Description" SG_ 2281833731 DMIC_RwsFltSta "This signal indicates fault status of individual systems.";
BA_ "UserSigValidity" SG_ 2281833731 DMIC_RwsFltSta 3;
BA_ "RoutingFactor" SG_ 2281833731 DMIC_RwsFltSta 2;
BA_ "Version" SG_ 2281833731 DMIC_RwsFltSta "17.11.00";
BA_ "Description" SG_ 2281833731 DMIC_IndWhlDrvSta "This signal is for feedback about tune-up mode(Wheel Drive type) setting on AVN.";
BA_ "UserSigValidity" SG_ 2281833731 DMIC_IndWhlDrvSta 3;
BA_ "RoutingFactor" SG_ 2281833731 DMIC_IndWhlDrvSta 2;
BA_ "Version" SG_ 2281833731 DMIC_IndWhlDrvSta "20.12.04";
BA_ "Description" SG_ 2281833731 DMIC_IndVcuModSta "This signal is for feedback about individual mode setting on AVN.";
BA_ "UserSigValidity" SG_ 2281833731 DMIC_IndVcuModSta 3;
BA_ "RoutingFactor" SG_ 2281833731 DMIC_IndVcuModSta 2;
BA_ "Version" SG_ 2281833731 DMIC_IndVcuModSta "20.04.02";
BA_ "Description" SG_ 2281833731 DMIC_VcuFltSta "This signal indicates fault status of individual systems.";
BA_ "UserSigValidity" SG_ 2281833731 DMIC_VcuFltSta 3;
BA_ "RoutingFactor" SG_ 2281833731 DMIC_VcuFltSta 2;
BA_ "Version" SG_ 2281833731 DMIC_VcuFltSta "20.04.02";
BA_ "Description" SG_ 2281833731 DMIC_IndMtrPwrSta "This signal is for feedback about tune-up mode(Motor Power) setting on AVN.";
BA_ "UserSigValidity" SG_ 2281833731 DMIC_IndMtrPwrSta 3;
BA_ "RoutingFactor" SG_ 2281833731 DMIC_IndMtrPwrSta 2;
BA_ "Version" SG_ 2281833731 DMIC_IndMtrPwrSta "20.12.04";
BA_ "Description" SG_ 2281833731 DMIC_IndAccSenSta "This signal is for feedback about tune-up mode(Acceleration sensitivity) setting on AVN.";
BA_ "UserSigValidity" SG_ 2281833731 DMIC_IndAccSenSta 3;
BA_ "RoutingFactor" SG_ 2281833731 DMIC_IndAccSenSta 2;
BA_ "Version" SG_ 2281833731 DMIC_IndAccSenSta "20.12.04";
BA_ "Description" SG_ 2281833731 DMIC_IndDecSenSta "This signal is for feedback about tune-up mode(Deceleration sensitivity) setting on AVN.";
BA_ "UserSigValidity" SG_ 2281833731 DMIC_IndDecSenSta 3;
BA_ "RoutingFactor" SG_ 2281833731 DMIC_IndDecSenSta 2;
BA_ "Version" SG_ 2281833731 DMIC_IndDecSenSta "20.12.04";
BA_ "Description" SG_ 2281833731 DMIC_IndMaxVehSpdSta "This signal is for feedback about tune-up mode(Maximum vehicle speed) setting on AVN.";
BA_ "UserSigValidity" SG_ 2281833731 DMIC_IndMaxVehSpdSta 3;
BA_ "RoutingFactor" SG_ 2281833731 DMIC_IndMaxVehSpdSta 2;
BA_ "Version" SG_ 2281833731 DMIC_IndMaxVehSpdSta "20.12.04";
BA_ "Description" SG_ 2281833731 DMIC_DrvMod2Typ "This signal indicates drive mode type.";
BA_ "UserSigValidity" SG_ 2281833731 DMIC_DrvMod2Typ 3;
BA_ "RoutingFactor" SG_ 2281833731 DMIC_DrvMod2Typ 2;
BA_ "Version" SG_ 2281833731 DMIC_DrvMod2Typ "20.04.04";
BA_ "Description" SG_ 2281833731 DMIC_DrvModFltSta "This signal is for Driving mode fault status. From this signal, AVN can deactivate any driving in mode selection menu.";
BA_ "UserSigValidity" SG_ 2281833731 DMIC_DrvModFltSta 3;
BA_ "RoutingFactor" SG_ 2281833731 DMIC_DrvModFltSta 2;
BA_ "Version" SG_ 2281833731 DMIC_DrvModFltSta "17.12.00";
BA_ "GenMsgSendType" BO_ 1041 0;
BA_ "Description" SG_ 1041 ICU_Crc2Val "The data area for CRC calculation is based on the data length (DLC) of the message DB.

The CRC shall be calculated over the entire data block (excluding the CRC bytes) including the user data, alive counter and Data ID 

 

- CRC Polynomial (0x1D) , Initial Value : 0x00, XOR value : 0xFF, Data ID Mode : Both, Data ID : Message ID + 0xF800 

- The initial value is for CRC calculation and the message should be sent with the calculated result value. 

The mathematical expression to 8 bit CRC polynomial is given here. G(x) = x8 + x4 + x3 + x2 + 1";
BA_ "GenSigSendType" SG_ 1041 ICU_Crc2Val 4;
BA_ "GenSigStartValue" SG_ 1041 ICU_Crc2Val 255;
BA_ "UserSigValidity" SG_ 1041 ICU_Crc2Val 0;
BA_ "Version" SG_ 1041 ICU_Crc2Val "18.11.08";
BA_ "Description" SG_ 1041 ICU_MtGearPosRSta "Manual Shift Lever R Switch Status 0x0:Off/0x1:On";
BA_ "GenSigSendType" SG_ 1041 ICU_MtGearPosRSta 4;
BA_ "UserSigValidity" SG_ 1041 ICU_MtGearPosRSta 3;
BA_REL_ "GenSigTimeoutTime" BU_SG_REL_ BLTN_CAM SG_ 1041 ICU_MtGearPosRSta 1500;
BA_ "Version" SG_ 1041 ICU_MtGearPosRSta "21.07.05";
BA_ "Description" SG_ 1041 ICU_AlvCnt2Val "For the first transmission request for a data element the counter shall be initialized with 0 and shall be incremented by 1

for every subsequent send request. When the counter reaches the maximum value(0xE), then it shall restart with 0 for the next send request";
BA_ "GenSigSendType" SG_ 1041 ICU_AlvCnt2Val 4;
BA_ "UserSigValidity" SG_ 1041 ICU_AlvCnt2Val 0;
BA_ "Version" SG_ 1041 ICU_AlvCnt2Val "18.11.08";
BA_ "GenSigSendType" SG_ 1041 DoorLock_AsstDrUnLkSta 4;
BA_ "UserSigValidity" SG_ 1041 DoorLock_AsstDrUnLkSta 0;
BA_ "NetworkRequest" SG_ 1041 DoorLock_AsstDrUnLkSta 0;
BA_ "NetworkRequestHoldingTime" SG_ 1041 DoorLock_AsstDrUnLkSta 5000;
BA_ "Version" SG_ 1041 DoorLock_AsstDrUnLkSta "17.12.00";
BA_ "GenSigSendType" SG_ 1041 Warn_DrvDrSwSta 4;
BA_ "UserSigValidity" SG_ 1041 Warn_DrvDrSwSta 0;
BA_REL_ "GenSigTimeoutTime" BU_SG_REL_ WPC SG_ 1041 Warn_DrvDrSwSta 1500;
BA_REL_ "GenSigTimeoutTime" BU_SG_REL_ RWPC SG_ 1041 Warn_DrvDrSwSta 1500;
BA_REL_ "GenSigTimeoutTime" BU_SG_REL_ DPSU SG_ 1041 Warn_DrvDrSwSta 1500;
BA_REL_ "GenSigTimeoutTime" BU_SG_REL_ BLTN_CAM SG_ 1041 Warn_DrvDrSwSta 1500;
BA_ "NetworkRequest" SG_ 1041 Warn_DrvDrSwSta 0;
BA_ "NetworkRequestHoldingTime" SG_ 1041 Warn_DrvDrSwSta 5000;
BA_ "Version" SG_ 1041 Warn_DrvDrSwSta "17.12.00";
BA_ "GenSigSendType" SG_ 1041 DoorLock_DrvKeyUnLkSwSta 4;
BA_ "UserSigValidity" SG_ 1041 DoorLock_DrvKeyUnLkSwSta 0;
BA_ "NetworkRequest" SG_ 1041 DoorLock_DrvKeyUnLkSwSta 0;
BA_ "NetworkRequestHoldingTime" SG_ 1041 DoorLock_DrvKeyUnLkSwSta 5000;
BA_ "Version" SG_ 1041 DoorLock_DrvKeyUnLkSwSta "17.12.00";
BA_ "GenSigSendType" SG_ 1041 DoorLock_RrLftDrUnLkSta 4;
BA_ "UserSigValidity" SG_ 1041 DoorLock_RrLftDrUnLkSta 0;
BA_ "NetworkRequest" SG_ 1041 DoorLock_RrLftDrUnLkSta 0;
BA_ "NetworkRequestHoldingTime" SG_ 1041 DoorLock_RrLftDrUnLkSta 5000;
BA_ "Version" SG_ 1041 DoorLock_RrLftDrUnLkSta "17.12.00";
BA_ "GenSigSendType" SG_ 1041 DoorLock_RrRtDrUnLkSta 4;
BA_ "UserSigValidity" SG_ 1041 DoorLock_RrRtDrUnLkSta 0;
BA_ "NetworkRequest" SG_ 1041 DoorLock_RrRtDrUnLkSta 0;
BA_ "NetworkRequestHoldingTime" SG_ 1041 DoorLock_RrRtDrUnLkSta 5000;
BA_ "Version" SG_ 1041 DoorLock_RrRtDrUnLkSta "17.12.00";
BA_ "GenSigSendType" SG_ 1041 Warn_AsstDrSwSta 4;
BA_ "UserSigValidity" SG_ 1041 Warn_AsstDrSwSta 0;
BA_REL_ "GenSigTimeoutTime" BU_SG_REL_ WPC SG_ 1041 Warn_AsstDrSwSta 1500;
BA_REL_ "GenSigTimeoutTime" BU_SG_REL_ RWPC SG_ 1041 Warn_AsstDrSwSta 1500;
BA_REL_ "GenSigTimeoutTime" BU_SG_REL_ APSU SG_ 1041 Warn_AsstDrSwSta 1500;
BA_REL_ "GenSigTimeoutTime" BU_SG_REL_ RLPSU SG_ 1041 Warn_AsstDrSwSta 1500;
BA_REL_ "GenSigTimeoutTime" BU_SG_REL_ BLTN_CAM SG_ 1041 Warn_AsstDrSwSta 1500;
BA_REL_ "GenSigTimeoutTime" BU_SG_REL_ ALBCU SG_ 1041 Warn_AsstDrSwSta 1500;
BA_ "NetworkRequest" SG_ 1041 Warn_AsstDrSwSta 0;
BA_ "NetworkRequestHoldingTime" SG_ 1041 Warn_AsstDrSwSta 5000;
BA_ "Version" SG_ 1041 Warn_AsstDrSwSta "17.12.00";
BA_ "Description" SG_ 1041 Warn_AsstStBltSwSta "-Default value: 0x1 (Belt)



-Initial value: 0x1 (Belt)



-Timeout value: 0x1 (Belt)";
BA_ "GenSigSendType" SG_ 1041 Warn_AsstStBltSwSta 4;
BA_ "GenSigStartValue" SG_ 1041 Warn_AsstStBltSwSta 1;
BA_ "UserSigValidity" SG_ 1041 Warn_AsstStBltSwSta 0;
BA_REL_ "GenSigTimeoutTime" BU_SG_REL_ PSB SG_ 1041 Warn_AsstStBltSwSta 1500;
BA_REL_ "GenSigTimeoutTime" BU_SG_REL_ APSU SG_ 1041 Warn_AsstStBltSwSta 1500;
BA_REL_ "GenSigTimeoutTime" BU_SG_REL_ RLPSU SG_ 1041 Warn_AsstStBltSwSta 1500;
BA_REL_ "GenSigTimeoutTime" BU_SG_REL_ ASAU SG_ 1041 Warn_AsstStBltSwSta 1500;
BA_REL_ "GenSigTimeoutTime" BU_SG_REL_ ALBCU SG_ 1041 Warn_AsstStBltSwSta 1500;
BA_ "NetworkRequest" SG_ 1041 Warn_AsstStBltSwSta 0;
BA_ "NetworkRequestHoldingTime" SG_ 1041 Warn_AsstStBltSwSta 5000;
BA_ "Version" SG_ 1041 Warn_AsstStBltSwSta "17.12.00";
BA_ "GenSigSendType" SG_ 1041 Warn_BrkFldSwSta 4;
BA_ "UserSigValidity" SG_ 1041 Warn_BrkFldSwSta 0;
BA_ "NetworkRequest" SG_ 1041 Warn_BrkFldSwSta 0;
BA_ "NetworkRequestHoldingTime" SG_ 1041 Warn_BrkFldSwSta 5000;
BA_ "Version" SG_ 1041 Warn_BrkFldSwSta "17.12.00";
BA_ "GenSigSendType" SG_ 1041 DoorLock_DrvKeyLkSwSta 4;
BA_ "UserSigValidity" SG_ 1041 DoorLock_DrvKeyLkSwSta 0;
BA_ "NetworkRequest" SG_ 1041 DoorLock_DrvKeyLkSwSta 0;
BA_ "NetworkRequestHoldingTime" SG_ 1041 DoorLock_DrvKeyLkSwSta 5000;
BA_ "Version" SG_ 1041 DoorLock_DrvKeyLkSwSta "17.12.00";
BA_ "GenSigSendType" SG_ 1041 Warn_DrvStBltSwSta 4;
BA_ "UserSigValidity" SG_ 1041 Warn_DrvStBltSwSta 0;
BA_REL_ "GenSigTimeoutTime" BU_SG_REL_ PSB SG_ 1041 Warn_DrvStBltSwSta 1500;
BA_REL_ "GenSigTimeoutTime" BU_SG_REL_ DPSU SG_ 1041 Warn_DrvStBltSwSta 1500;
BA_REL_ "GenSigTimeoutTime" BU_SG_REL_ DLBCU SG_ 1041 Warn_DrvStBltSwSta 1500;
BA_REL_ "GenSigTimeoutTime" BU_SG_REL_ ATS SG_ 1041 Warn_DrvStBltSwSta 1500;
BA_REL_ "GenSigTimeoutTime" BU_SG_REL_ DSAU SG_ 1041 Warn_DrvStBltSwSta 1500;
BA_REL_ "GenSigTimeoutTime" BU_SG_REL_ ASAU SG_ 1041 Warn_DrvStBltSwSta 1500;
BA_ "NetworkRequest" SG_ 1041 Warn_DrvStBltSwSta 0;
BA_ "NetworkRequestHoldingTime" SG_ 1041 Warn_DrvStBltSwSta 5000;
BA_ "Version" SG_ 1041 Warn_DrvStBltSwSta "17.12.00";
BA_ "GenSigSendType" SG_ 1041 Warn_HoodSwSta 4;
BA_ "UserSigValidity" SG_ 1041 Warn_HoodSwSta 0;
BA_REL_ "GenSigTimeoutTime" BU_SG_REL_ BLTN_CAM SG_ 1041 Warn_HoodSwSta 1500;
BA_ "NetworkRequest" SG_ 1041 Warn_HoodSwSta 0;
BA_ "NetworkRequestHoldingTime" SG_ 1041 Warn_HoodSwSta 5000;
BA_ "Version" SG_ 1041 Warn_HoodSwSta "17.12.00";
BA_ "Description" SG_ 1041 Warn_PassStOccSta "Passenger Seated State







-Default value: 0x0 (¹ÌÅ¾½Â)



-Initial value: 0x0 (¹ÌÅ¾½Â)



-Timeout value: 0x0 (¹ÌÅ¾½Â)";
BA_ "GenSigSendType" SG_ 1041 Warn_PassStOccSta 4;
BA_ "UserSigValidity" SG_ 1041 Warn_PassStOccSta 0;
BA_REL_ "GenSigTimeoutTime" BU_SG_REL_ APSU SG_ 1041 Warn_PassStOccSta 1500;
BA_ "NetworkRequest" SG_ 1041 Warn_PassStOccSta 0;
BA_ "NetworkRequestHoldingTime" SG_ 1041 Warn_PassStOccSta 5000;
BA_ "Version" SG_ 1041 Warn_PassStOccSta "17.12.00";
BA_ "GenSigSendType" SG_ 1041 Warn_PrkngBrkSwSta 4;
BA_ "UserSigValidity" SG_ 1041 Warn_PrkngBrkSwSta 0;
BA_REL_ "GenSigTimeoutTime" BU_SG_REL_ APSU SG_ 1041 Warn_PrkngBrkSwSta 1500;
BA_REL_ "GenSigTimeoutTime" BU_SG_REL_ RLHV SG_ 1041 Warn_PrkngBrkSwSta 1500;
BA_REL_ "GenSigTimeoutTime" BU_SG_REL_ RRHV SG_ 1041 Warn_PrkngBrkSwSta 1500;
BA_REL_ "GenSigTimeoutTime" BU_SG_REL_ PFSU SG_ 1041 Warn_PrkngBrkSwSta 1500;
BA_REL_ "GenSigTimeoutTime" BU_SG_REL_ RRPSU SG_ 1041 Warn_PrkngBrkSwSta 1500;
BA_REL_ "GenSigTimeoutTime" BU_SG_REL_ RLPSU SG_ 1041 Warn_PrkngBrkSwSta 1500;
BA_ "NetworkRequest" SG_ 1041 Warn_PrkngBrkSwSta 0;
BA_ "NetworkRequestHoldingTime" SG_ 1041 Warn_PrkngBrkSwSta 5000;
BA_ "Version" SG_ 1041 Warn_PrkngBrkSwSta "17.12.00";
BA_ "GenSigSendType" SG_ 1041 Warn_RrCtrStBltSwSta 4;
BA_ "UserSigValidity" SG_ 1041 Warn_RrCtrStBltSwSta 0;
BA_REL_ "GenSigTimeoutTime" BU_SG_REL_ PSB SG_ 1041 Warn_RrCtrStBltSwSta 1500;
BA_ "NetworkRequest" SG_ 1041 Warn_RrCtrStBltSwSta 0;
BA_ "NetworkRequestHoldingTime" SG_ 1041 Warn_RrCtrStBltSwSta 5000;
BA_ "Version" SG_ 1041 Warn_RrCtrStBltSwSta "17.12.00";
BA_ "GenSigSendType" SG_ 1041 Warn_RrLftDrSwSta 4;
BA_ "UserSigValidity" SG_ 1041 Warn_RrLftDrSwSta 0;
BA_REL_ "GenSigTimeoutTime" BU_SG_REL_ WPC SG_ 1041 Warn_RrLftDrSwSta 1500;
BA_REL_ "GenSigTimeoutTime" BU_SG_REL_ RWPC SG_ 1041 Warn_RrLftDrSwSta 1500;
BA_REL_ "GenSigTimeoutTime" BU_SG_REL_ APSU SG_ 1041 Warn_RrLftDrSwSta 1500;
BA_REL_ "GenSigTimeoutTime" BU_SG_REL_ RLHV SG_ 1041 Warn_RrLftDrSwSta 1500;
BA_REL_ "GenSigTimeoutTime" BU_SG_REL_ RLPSU SG_ 1041 Warn_RrLftDrSwSta 1500;
BA_REL_ "GenSigTimeoutTime" BU_SG_REL_ BLTN_CAM SG_ 1041 Warn_RrLftDrSwSta 1500;
BA_ "NetworkRequest" SG_ 1041 Warn_RrLftDrSwSta 0;
BA_ "NetworkRequestHoldingTime" SG_ 1041 Warn_RrLftDrSwSta 5000;
BA_ "Version" SG_ 1041 Warn_RrLftDrSwSta "17.12.00";
BA_ "GenSigSendType" SG_ 1041 Warn_RrLftStBltSwSta 4;
BA_ "UserSigValidity" SG_ 1041 Warn_RrLftStBltSwSta 0;
BA_REL_ "GenSigTimeoutTime" BU_SG_REL_ PSB SG_ 1041 Warn_RrLftStBltSwSta 1500;
BA_REL_ "GenSigTimeoutTime" BU_SG_REL_ APSU SG_ 1041 Warn_RrLftStBltSwSta 1500;
BA_REL_ "GenSigTimeoutTime" BU_SG_REL_ DPSU SG_ 1041 Warn_RrLftStBltSwSta 1500;
BA_ "NetworkRequest" SG_ 1041 Warn_RrLftStBltSwSta 0;
BA_ "NetworkRequestHoldingTime" SG_ 1041 Warn_RrLftStBltSwSta 5000;
BA_ "Version" SG_ 1041 Warn_RrLftStBltSwSta "17.12.00";
BA_ "GenSigSendType" SG_ 1041 Warn_RrRtDrSwSta 4;
BA_ "UserSigValidity" SG_ 1041 Warn_RrRtDrSwSta 0;
BA_REL_ "GenSigTimeoutTime" BU_SG_REL_ WPC SG_ 1041 Warn_RrRtDrSwSta 1500;
BA_REL_ "GenSigTimeoutTime" BU_SG_REL_ RWPC SG_ 1041 Warn_RrRtDrSwSta 1500;
BA_REL_ "GenSigTimeoutTime" BU_SG_REL_ APSU SG_ 1041 Warn_RrRtDrSwSta 1500;
BA_REL_ "GenSigTimeoutTime" BU_SG_REL_ RRHV SG_ 1041 Warn_RrRtDrSwSta 1500;
BA_REL_ "GenSigTimeoutTime" BU_SG_REL_ RRPSU SG_ 1041 Warn_RrRtDrSwSta 1500;
BA_REL_ "GenSigTimeoutTime" BU_SG_REL_ RLPSU SG_ 1041 Warn_RrRtDrSwSta 1500;
BA_REL_ "GenSigTimeoutTime" BU_SG_REL_ BLTN_CAM SG_ 1041 Warn_RrRtDrSwSta 1500;
BA_ "NetworkRequest" SG_ 1041 Warn_RrRtDrSwSta 0;
BA_ "NetworkRequestHoldingTime" SG_ 1041 Warn_RrRtDrSwSta 5000;
BA_ "Version" SG_ 1041 Warn_RrRtDrSwSta "17.12.00";
BA_ "GenSigSendType" SG_ 1041 Warn_RrRtStBltSwSta 4;
BA_ "UserSigValidity" SG_ 1041 Warn_RrRtStBltSwSta 0;
BA_REL_ "GenSigTimeoutTime" BU_SG_REL_ PSB SG_ 1041 Warn_RrRtStBltSwSta 1500;
BA_REL_ "GenSigTimeoutTime" BU_SG_REL_ APSU SG_ 1041 Warn_RrRtStBltSwSta 1500;
BA_REL_ "GenSigTimeoutTime" BU_SG_REL_ DPSU SG_ 1041 Warn_RrRtStBltSwSta 1500;
BA_REL_ "GenSigTimeoutTime" BU_SG_REL_ RRPSU SG_ 1041 Warn_RrRtStBltSwSta 1500;
BA_ "NetworkRequest" SG_ 1041 Warn_RrRtStBltSwSta 0;
BA_ "NetworkRequestHoldingTime" SG_ 1041 Warn_RrRtStBltSwSta 5000;
BA_ "Version" SG_ 1041 Warn_RrRtStBltSwSta "17.12.00";
BA_ "Description" SG_ 1041 Warn_HoodSwMemorySta "Hood swtich open->close information(memory)



This signal is for oil level warning lamp reset In case hood open->close when IG-OFF, 0x01 sent for 5 sec at next IG-ON";
BA_ "GenSigSendType" SG_ 1041 Warn_HoodSwMemorySta 4;
BA_ "UserSigValidity" SG_ 1041 Warn_HoodSwMemorySta 3;
BA_ "NetworkRequest" SG_ 1041 Warn_HoodSwMemorySta 0;
BA_ "NetworkRequestHoldingTime" SG_ 1041 Warn_HoodSwMemorySta 5000;
BA_ "Version" SG_ 1041 Warn_HoodSwMemorySta "17.12.00";
BA_ "Description" SG_ 1041 Warn_WshrFldSwSta "Washer Fluid Switch Signal

This signal indicates Washer Fluid Switch Signal

0x0:Off/0x1:On";
BA_ "GenSigSendType" SG_ 1041 Warn_WshrFldSwSta 4;
BA_ "UserSigValidity" SG_ 1041 Warn_WshrFldSwSta 3;
BA_ "NetworkRequest" SG_ 1041 Warn_WshrFldSwSta 0;
BA_ "NetworkRequestHoldingTime" SG_ 1041 Warn_WshrFldSwSta 5000;
BA_ "Version" SG_ 1041 Warn_WshrFldSwSta "21.07.05";
BA_ "Description" SG_ 1041 ICU_Haptic_OPT "Steering Wheel Haptic Warning Option Infomation (From ICU)";
BA_ "GenSigSendType" SG_ 1041 ICU_Haptic_OPT 4;
BA_ "UserSigValidity" SG_ 1041 ICU_Haptic_OPT 0;
BA_ "NetworkRequest" SG_ 1041 ICU_Haptic_OPT 0;
BA_ "NetworkRequestHoldingTime" SG_ 1041 ICU_Haptic_OPT 5000;
BA_ "Version" SG_ 1041 ICU_Haptic_OPT "18.07.07";
BA_ "GenMsgSendType" BO_ 1043 0;
BA_ "Description" SG_ 1043 ICU_Crc4Val "The data area for CRC calculation is based on the data length (DLC) of the message DB.

The CRC shall be calculated over the entire data block (excluding the CRC bytes) including the user data, alive counter and Data ID 

 

- CRC Polynomial (0x1D) , Initial Value : 0x00, XOR value : 0xFF, Data ID Mode : Both, Data ID : Message ID + 0xF800 

- The initial value is for CRC calculation and the message should be sent with the calculated result value. 

The mathematical expression to 8 bit CRC polynomial is given here. G(x) = x8 + x4 + x3 + x2 + 1";
BA_ "GenSigSendType" SG_ 1043 ICU_Crc4Val 4;
BA_ "GenSigStartValue" SG_ 1043 ICU_Crc4Val 255;
BA_ "UserSigValidity" SG_ 1043 ICU_Crc4Val 0;
BA_ "Version" SG_ 1043 ICU_Crc4Val "18.11.08";
BA_ "Description" SG_ 1043 Lamp_TrnSigLmpRtActiveSt "Turn Signal Lamp Blink Info";
BA_ "GenSigSendType" SG_ 1043 Lamp_TrnSigLmpRtActiveSt 4;
BA_ "UserSigValidity" SG_ 1043 Lamp_TrnSigLmpRtActiveSt 0;
BA_ "NetworkRequest" SG_ 1043 Lamp_TrnSigLmpRtActiveSt 0;
BA_ "NetworkRequestHoldingTime" SG_ 1043 Lamp_TrnSigLmpRtActiveSt 5000;
BA_ "Version" SG_ 1043 Lamp_TrnSigLmpRtActiveSt "19.11.00";
BA_ "Description" SG_ 1043 ICU_AlvCnt4Val "For the first transmission request for a data element the counter shall be initialized with 0 and shall be incremented by 1

for every subsequent send request. When the counter reaches the maximum value(0xE), then it shall restart with 0 for the next send request";
BA_ "GenSigSendType" SG_ 1043 ICU_AlvCnt4Val 4;
BA_ "UserSigValidity" SG_ 1043 ICU_AlvCnt4Val 0;
BA_ "Version" SG_ 1043 ICU_AlvCnt4Val "18.11.08";
BA_ "GenSigSendType" SG_ 1043 ExtLamp_HzrdSwSta 4;
BA_ "UserSigValidity" SG_ 1043 ExtLamp_HzrdSwSta 0;
BA_ "NetworkRequest" SG_ 1043 ExtLamp_HzrdSwSta 0;
BA_ "NetworkRequestHoldingTime" SG_ 1043 ExtLamp_HzrdSwSta 5000;
BA_ "Version" SG_ 1043 ExtLamp_HzrdSwSta "17.12.00";
BA_ "Description" SG_ 1043 IntLamp_InlTailLmpSta "-(Old)C_INTTail_Act";
BA_ "GenSigSendType" SG_ 1043 IntLamp_InlTailLmpSta 4;
BA_ "UserSigValidity" SG_ 1043 IntLamp_InlTailLmpSta 0;
BA_REL_ "GenSigTimeoutTime" BU_SG_REL_ SWRC SG_ 1043 IntLamp_InlTailLmpSta 1500;
BA_REL_ "GenSigTimeoutTime" BU_SG_REL_ BLTN_CAM SG_ 1043 IntLamp_InlTailLmpSta 1500;
BA_ "NetworkRequest" SG_ 1043 IntLamp_InlTailLmpSta 0;
BA_ "NetworkRequestHoldingTime" SG_ 1043 IntLamp_InlTailLmpSta 5000;
BA_ "Version" SG_ 1043 IntLamp_InlTailLmpSta "17.12.00";
BA_ "Description" SG_ 1043 Lamp_LedHdLmpSta "This signal is LED headlamp status inform whether LED fail or not which is regulation of ECE, Domestic.



If LED H/Lamp detects LED failure then a cluster shall be turn on to 'LED' indicator in the display panel and It should be to display the words 'Check LED Head Lamp!' on the LCD panel in the cluster module.

 

If LED H/Lamp detects FAN failure then a cluster shall be turn on 'LED' indicator in the display panel and It should be to display the words 'Check LED Head Lamp¡¯s FAN!' on the LCD panel in the cluster module.('LED' Indicator not blink)



1) Priority is higher LED failure than FAN failure.

2) 'LED' indicator off when Normal Conditions.";
BA_ "GenSigSendType" SG_ 1043 Lamp_LedHdLmpSta 4;
BA_ "UserSigValidity" SG_ 1043 Lamp_LedHdLmpSta 3;
BA_ "NetworkRequest" SG_ 1043 Lamp_LedHdLmpSta 0;
BA_ "NetworkRequestHoldingTime" SG_ 1043 Lamp_LedHdLmpSta 5000;
BA_ "Version" SG_ 1043 Lamp_LedHdLmpSta "17.12.00";
BA_ "Description" SG_ 1043 TrnLmpSeqEnblCmd "Turn Signal Sequential Enable CAN Command";
BA_ "GenSigSendType" SG_ 1043 TrnLmpSeqEnblCmd 4;
BA_ "UserSigValidity" SG_ 1043 TrnLmpSeqEnblCmd 0;
BA_ "NetworkRequest" SG_ 1043 TrnLmpSeqEnblCmd 0;
BA_ "NetworkRequestHoldingTime" SG_ 1043 TrnLmpSeqEnblCmd 5000;
BA_ "Version" SG_ 1043 TrnLmpSeqEnblCmd "20.08.07";
BA_ "GenSigSendType" SG_ 1043 Lamp_TrnSigLmpLftOnReq 4;
BA_ "UserSigValidity" SG_ 1043 Lamp_TrnSigLmpLftOnReq 0;
BA_REL_ "GenSigTimeoutTime" BU_SG_REL_ BLTN_CAM SG_ 1043 Lamp_TrnSigLmpLftOnReq 1500;
BA_ "NetworkRequest" SG_ 1043 Lamp_TrnSigLmpLftOnReq 0;
BA_ "NetworkRequestHoldingTime" SG_ 1043 Lamp_TrnSigLmpLftOnReq 5000;
BA_ "Version" SG_ 1043 Lamp_TrnSigLmpLftOnReq "17.12.05";
BA_ "GenSigSendType" SG_ 1043 Lamp_TrnSigLmpRtOnReq 4;
BA_ "UserSigValidity" SG_ 1043 Lamp_TrnSigLmpRtOnReq 0;
BA_REL_ "GenSigTimeoutTime" BU_SG_REL_ BLTN_CAM SG_ 1043 Lamp_TrnSigLmpRtOnReq 1500;
BA_ "NetworkRequest" SG_ 1043 Lamp_TrnSigLmpRtOnReq 0;
BA_ "NetworkRequestHoldingTime" SG_ 1043 Lamp_TrnSigLmpRtOnReq 5000;
BA_ "Version" SG_ 1043 Lamp_TrnSigLmpRtOnReq "17.12.05";
BA_ "Description" SG_ 1043 Lamp_TrnSigLmpLftActiveSt "Turn Signal Lmap Blink Info";
BA_ "GenSigSendType" SG_ 1043 Lamp_TrnSigLmpLftActiveSt 4;
BA_ "UserSigValidity" SG_ 1043 Lamp_TrnSigLmpLftActiveSt 0;
BA_ "NetworkRequest" SG_ 1043 Lamp_TrnSigLmpLftActiveSt 0;
BA_ "NetworkRequestHoldingTime" SG_ 1043 Lamp_TrnSigLmpLftActiveSt 5000;
BA_ "Version" SG_ 1043 Lamp_TrnSigLmpLftActiveSt "19.11.00";
BA_ "GenMsgSendType" BO_ 1044 0;
BA_ "Description" SG_ 1044 ICU_Crc5Val "The data area for CRC calculation is based on the data length (DLC) of the message DB.

The CRC shall be calculated over the entire data block (excluding the CRC bytes) including the user data, alive counter and Data ID 

 

- CRC Polynomial (0x1D) , Initial Value : 0x00, XOR value : 0xFF, Data ID Mode : Both, Data ID : Message ID + 0xF800 

- The initial value is for CRC calculation and the message should be sent with the calculated result value. 

The mathematical expression to 8 bit CRC polynomial is given here. G(x) = x8 + x4 + x3 + x2 + 1";
BA_ "GenSigSendType" SG_ 1044 ICU_Crc5Val 4;
BA_ "GenSigStartValue" SG_ 1044 ICU_Crc5Val 255;
BA_ "UserSigValidity" SG_ 1044 ICU_Crc5Val 0;
BA_ "Version" SG_ 1044 ICU_Crc5Val "18.11.08";
BA_ "Description" SG_ 1044 ICU_AlvCnt5Val "For the first transmission request for a data element the counter shall be initialized with 0 and shall be incremented by 1

for every subsequent send request. When the counter reaches the maximum value(0xE), then it shall restart with 0 for the next send request";
BA_ "GenSigSendType" SG_ 1044 ICU_AlvCnt5Val 4;
BA_ "UserSigValidity" SG_ 1044 ICU_AlvCnt5Val 0;
BA_ "Version" SG_ 1044 ICU_AlvCnt5Val "18.11.08";
BA_ "Description" SG_ 1044 Trunk_TrnkInReleaseSwSta "-Trunk Inner Release SW";
BA_ "GenSigSendType" SG_ 1044 Trunk_TrnkInReleaseSwSta 4;
BA_ "UserSigValidity" SG_ 1044 Trunk_TrnkInReleaseSwSta 0;
BA_ "NetworkRequest" SG_ 1044 Trunk_TrnkInReleaseSwSta 0;
BA_ "NetworkRequestHoldingTime" SG_ 1044 Trunk_TrnkInReleaseSwSta 5000;
BA_ "Version" SG_ 1044 Trunk_TrnkInReleaseSwSta "17.12.00";
BA_ "Description" SG_ 1044 Trunk_TrnkTlgtOutReleaseSwSta "-(Old)C_TRUNK_LID

-Trunk/Tailgate Outter Release SW";
BA_ "GenSigSendType" SG_ 1044 Trunk_TrnkTlgtOutReleaseSwSta 4;
BA_ "UserSigValidity" SG_ 1044 Trunk_TrnkTlgtOutReleaseSwSta 0;
BA_ "NetworkRequest" SG_ 1044 Trunk_TrnkTlgtOutReleaseSwSta 0;
BA_ "NetworkRequestHoldingTime" SG_ 1044 Trunk_TrnkTlgtOutReleaseSwSta 5000;
BA_ "Version" SG_ 1044 Trunk_TrnkTlgtOutReleaseSwSta "17.12.00";
BA_ "Description" SG_ 1044 Trunk_TrnkTlgtSwSta "Full Lock SW Status Signal



(TailGate/TrunkLid Tpye all)



1. Luggage or Trunkroom Lamp On/Off



2. TailGate/TrunkLid Open Ind in cluster



3. Normal Open SW



  - SW Off: Full Lock(Full Close state)



  - SW On: ^Full Lock";
BA_ "GenSigSendType" SG_ 1044 Trunk_TrnkTlgtSwSta 4;
BA_ "UserSigValidity" SG_ 1044 Trunk_TrnkTlgtSwSta 0;
BA_REL_ "GenSigTimeoutTime" BU_SG_REL_ APSU SG_ 1044 Trunk_TrnkTlgtSwSta 1500;
BA_REL_ "GenSigTimeoutTime" BU_SG_REL_ RLHV SG_ 1044 Trunk_TrnkTlgtSwSta 1500;
BA_REL_ "GenSigTimeoutTime" BU_SG_REL_ RRHV SG_ 1044 Trunk_TrnkTlgtSwSta 1500;
BA_REL_ "GenSigTimeoutTime" BU_SG_REL_ PFSU SG_ 1044 Trunk_TrnkTlgtSwSta 1500;
BA_REL_ "GenSigTimeoutTime" BU_SG_REL_ RRPSU SG_ 1044 Trunk_TrnkTlgtSwSta 1500;
BA_REL_ "GenSigTimeoutTime" BU_SG_REL_ RLPSU SG_ 1044 Trunk_TrnkTlgtSwSta 1500;
BA_REL_ "GenSigTimeoutTime" BU_SG_REL_ BLTN_CAM SG_ 1044 Trunk_TrnkTlgtSwSta 1500;
BA_ "NetworkRequest" SG_ 1044 Trunk_TrnkTlgtSwSta 0;
BA_ "NetworkRequestHoldingTime" SG_ 1044 Trunk_TrnkTlgtSwSta 5000;
BA_ "Version" SG_ 1044 Trunk_TrnkTlgtSwSta "17.12.00";
BA_ "Description" SG_ 1044 Trunk_GlvBxTrnkLkSwSta "- Glove Box Trunk Lock SW";
BA_ "GenSigSendType" SG_ 1044 Trunk_GlvBxTrnkLkSwSta 4;
BA_ "UserSigValidity" SG_ 1044 Trunk_GlvBxTrnkLkSwSta 0;
BA_ "NetworkRequest" SG_ 1044 Trunk_GlvBxTrnkLkSwSta 0;
BA_ "NetworkRequestHoldingTime" SG_ 1044 Trunk_GlvBxTrnkLkSwSta 5000;
BA_ "Version" SG_ 1044 Trunk_GlvBxTrnkLkSwSta "17.12.00";
BA_ "Description" SG_ 1044 Trunk_TlgtFullOpnSwSta "Full Open SW Status Signal



(Power TailGate/TrunkLid Tpye or tailgate latch 2sw type)



* Normal Open SW



  - SW Off: ^Full Open



  - SW On: Full Open(Full Open state)";
BA_ "GenSigSendType" SG_ 1044 Trunk_TlgtFullOpnSwSta 4;
BA_ "UserSigValidity" SG_ 1044 Trunk_TlgtFullOpnSwSta 0;
BA_ "NetworkRequest" SG_ 1044 Trunk_TlgtFullOpnSwSta 0;
BA_ "NetworkRequestHoldingTime" SG_ 1044 Trunk_TlgtFullOpnSwSta 5000;
BA_ "Version" SG_ 1044 Trunk_TlgtFullOpnSwSta "17.12.00";
BA_ "GenSigSendType" SG_ 1044 Trunk_TrnkTlgtReleaseRlySta 4;
BA_ "UserSigValidity" SG_ 1044 Trunk_TrnkTlgtReleaseRlySta 0;
BA_ "NetworkRequest" SG_ 1044 Trunk_TrnkTlgtReleaseRlySta 0;
BA_ "NetworkRequestHoldingTime" SG_ 1044 Trunk_TrnkTlgtReleaseRlySta 5000;
BA_ "Version" SG_ 1044 Trunk_TrnkTlgtReleaseRlySta "17.12.00";
BA_ "Description" SG_ 1044 USM_OneTouchTrnSigFuncSta "This signal is 



- For One Touch Turn Signal Function,



 the advanced version of One Touch triple turn signal



- Communicated with Cluster for setting USM



- Periodic Event Signal to notice current staus to USM of Cluster";
BA_ "GenSigSendType" SG_ 1044 USM_OneTouchTrnSigFuncSta 4;
BA_ "UserSigValidity" SG_ 1044 USM_OneTouchTrnSigFuncSta 0;
BA_ "NetworkRequest" SG_ 1044 USM_OneTouchTrnSigFuncSta 0;
BA_ "NetworkRequestHoldingTime" SG_ 1044 USM_OneTouchTrnSigFuncSta 5000;
BA_ "Version" SG_ 1044 USM_OneTouchTrnSigFuncSta "21.07.05";
BA_ "GenSigSendType" SG_ 1044 DoorLock_DrvDrUnLkSta 4;
BA_ "UserSigValidity" SG_ 1044 DoorLock_DrvDrUnLkSta 0;
BA_ "NetworkRequest" SG_ 1044 DoorLock_DrvDrUnLkSta 0;
BA_ "NetworkRequestHoldingTime" SG_ 1044 DoorLock_DrvDrUnLkSta 5000;
BA_ "Version" SG_ 1044 DoorLock_DrvDrUnLkSta "17.12.00";
BA_ "Description" SG_ 1044 DoorLock_LkOutSta "- Door Lock or Unlock Output State 



0x0 : Off (Door lock/unlock output Off state)



0x1 : On (Door lock/unlock output On state)";
BA_ "GenSigSendType" SG_ 1044 DoorLock_LkOutSta 4;
BA_ "UserSigValidity" SG_ 1044 DoorLock_LkOutSta 0;
BA_ "NetworkRequest" SG_ 1044 DoorLock_LkOutSta 0;
BA_ "NetworkRequestHoldingTime" SG_ 1044 DoorLock_LkOutSta 5000;
BA_ "Version" SG_ 1044 DoorLock_LkOutSta "17.12.00";
BA_ "Description" SG_ 1044 C_CrashUnlockState "Crash Unlock Active State

-0x0:Off

-0x1:Unlock(crash)";
BA_ "GenSigSendType" SG_ 1044 C_CrashUnlockState 4;
BA_ "UserSigValidity" SG_ 1044 C_CrashUnlockState 0;
BA_REL_ "GenSigTimeoutTime" BU_SG_REL_ BLTN_CAM SG_ 1044 C_CrashUnlockState 1500;
BA_ "NetworkRequest" SG_ 1044 C_CrashUnlockState 0;
BA_ "Version" SG_ 1044 C_CrashUnlockState "21.07.05";
BA_ "Description" SG_ 1044 C_AutoLeverManualSW "This signal represents operating status of AT/CVT/DCT Lever Manual Switch";
BA_ "GenSigSendType" SG_ 1044 C_AutoLeverManualSW 4;
BA_ "UserSigValidity" SG_ 1044 C_AutoLeverManualSW 3;
BA_ "Version" SG_ 1044 C_AutoLeverManualSW "19.09.06";
BA_ "GenMsgSendType" BO_ 579 0;
BA_ "Description" SG_ 579 OHCL_Opt "This signal is OHCL(OverHead Console Lamp)  ECU Option state";
BA_ "GenSigSendType" SG_ 579 OHCL_Opt 4;
BA_ "TimeoutValue" SG_ 579 OHCL_Opt "Old Value";
BA_ "UserSigValidity" SG_ 579 OHCL_Opt 3;
BA_REL_ "GenSigTimeoutTime" BU_SG_REL_ ATS SG_ 579 OHCL_Opt 1000;
BA_ "Version" SG_ 579 OHCL_Opt "19.12.01";
BA_ "Description" SG_ 579 OHCL_Sys_sta "This signal is OHCL (OverHead Console Lamp) system state";
BA_ "GenSigSendType" SG_ 579 OHCL_Sys_sta 4;
BA_ "TimeoutValue" SG_ 579 OHCL_Sys_sta "0x3";
BA_ "UserSigValidity" SG_ 579 OHCL_Sys_sta 3;
BA_REL_ "GenSigTimeoutTime" BU_SG_REL_ ATS SG_ 579 OHCL_Sys_sta 1000;
BA_ "Version" SG_ 579 OHCL_Sys_sta "19.12.01";
BA_ "Description" SG_ 579 OHCL_DoorOn_Sta "This signal is door lamp switch On/Off status";
BA_ "GenSigSendType" SG_ 579 OHCL_DoorOn_Sta 4;
BA_ "TimeoutValue" SG_ 579 OHCL_DoorOn_Sta "Old Value";
BA_ "UserSigValidity" SG_ 579 OHCL_DoorOn_Sta 3;
BA_REL_ "GenSigTimeoutTime" BU_SG_REL_ ATS SG_ 579 OHCL_DoorOn_Sta 1000;
BA_ "Version" SG_ 579 OHCL_DoorOn_Sta "19.12.01";
BA_ "Description" SG_ 579 OHCL_RrMapLftOn_Sta "This signal is rear left map lamp On/Off status";
BA_ "GenSigSendType" SG_ 579 OHCL_RrMapLftOn_Sta 4;
BA_ "TimeoutValue" SG_ 579 OHCL_RrMapLftOn_Sta "Old Value";
BA_ "UserSigValidity" SG_ 579 OHCL_RrMapLftOn_Sta 3;
BA_REL_ "GenSigTimeoutTime" BU_SG_REL_ ATS SG_ 579 OHCL_RrMapLftOn_Sta 1000;
BA_ "Version" SG_ 579 OHCL_RrMapLftOn_Sta "19.12.01";
BA_ "Description" SG_ 579 OHCL_RrMapRtOn_Sta "This signal is rear right map lamp On/Off status";
BA_ "GenSigSendType" SG_ 579 OHCL_RrMapRtOn_Sta 4;
BA_ "TimeoutValue" SG_ 579 OHCL_RrMapRtOn_Sta "Old Value";
BA_ "UserSigValidity" SG_ 579 OHCL_RrMapRtOn_Sta 3;
BA_REL_ "GenSigTimeoutTime" BU_SG_REL_ ATS SG_ 579 OHCL_RrMapRtOn_Sta 1000;
BA_ "Version" SG_ 579 OHCL_RrMapRtOn_Sta "19.12.01";
BA_ "Description" SG_ 579 OHCL_RrRoomOn_Sta "This signal is rear room map lamp On/Off status ( all )";
BA_ "GenSigSendType" SG_ 579 OHCL_RrRoomOn_Sta 4;
BA_ "TimeoutValue" SG_ 579 OHCL_RrRoomOn_Sta "Old Value";
BA_ "UserSigValidity" SG_ 579 OHCL_RrRoomOn_Sta 3;
BA_REL_ "GenSigTimeoutTime" BU_SG_REL_ ATS SG_ 579 OHCL_RrRoomOn_Sta 1000;
BA_ "Version" SG_ 579 OHCL_RrRoomOn_Sta "19.12.01";
BA_ "Description" SG_ 579 OHCL_RrMoodOn_Sta "This signal is rear mood map lamp On/Off status";
BA_ "GenSigSendType" SG_ 579 OHCL_RrMoodOn_Sta 4;
BA_ "TimeoutValue" SG_ 579 OHCL_RrMoodOn_Sta "Old Value";
BA_ "UserSigValidity" SG_ 579 OHCL_RrMoodOn_Sta 3;
BA_REL_ "GenSigTimeoutTime" BU_SG_REL_ ATS SG_ 579 OHCL_RrMoodOn_Sta 1000;
BA_ "Version" SG_ 579 OHCL_RrMoodOn_Sta "19.12.01";
BA_ "Description" SG_ 579 OHCL_LEDClr_Sta "This signal is interior lamps lighting color status";
BA_ "GenSigSendType" SG_ 579 OHCL_LEDClr_Sta 4;
BA_ "TimeoutValue" SG_ 579 OHCL_LEDClr_Sta "Old Value";
BA_ "UserSigValidity" SG_ 579 OHCL_LEDClr_Sta 3;
BA_REL_ "GenSigTimeoutTime" BU_SG_REL_ ATS SG_ 579 OHCL_LEDClr_Sta 1000;
BA_ "Version" SG_ 579 OHCL_LEDClr_Sta "19.12.01";
BA_ "Description" SG_ 579 OHCL_LEDBgtns_Sta "This signal is interior lamps brightness status";
BA_ "GenSigSendType" SG_ 579 OHCL_LEDBgtns_Sta 4;
BA_ "TimeoutValue" SG_ 579 OHCL_LEDBgtns_Sta "Old Value";
BA_ "UserSigValidity" SG_ 579 OHCL_LEDBgtns_Sta 3;
BA_REL_ "GenSigTimeoutTime" BU_SG_REL_ ATS SG_ 579 OHCL_LEDBgtns_Sta 1000;
BA_ "Version" SG_ 579 OHCL_LEDBgtns_Sta "19.12.01";
BA_ "Description" SG_ 579 OHCL_TllTlLmpSta "This signal is PAB tell tale lamp status signal

( ACU_TllTlLmpDis feedback signal )";
BA_ "GenSigSendType" SG_ 579 OHCL_TllTlLmpSta 4;
BA_ "GenSigStartValue" SG_ 579 OHCL_TllTlLmpSta 3;
BA_ "UserSigValidity" SG_ 579 OHCL_TllTlLmpSta 3;
BA_REL_ "GenSigTimeoutTime" BU_SG_REL_ CGW_CCU SG_ 579 OHCL_TllTlLmpSta 1000;
BA_ "Version" SG_ 579 OHCL_TllTlLmpSta "20.10.00";
BA_ "Description" SG_ 579 OHCL_FrMapLftOn_Sta "This signal is front left map lamp On/Off status";
BA_ "GenSigSendType" SG_ 579 OHCL_FrMapLftOn_Sta 4;
BA_ "TimeoutValue" SG_ 579 OHCL_FrMapLftOn_Sta "0x0";
BA_ "UserSigValidity" SG_ 579 OHCL_FrMapLftOn_Sta 3;
BA_REL_ "GenSigTimeoutTime" BU_SG_REL_ ATS SG_ 579 OHCL_FrMapLftOn_Sta 1000;
BA_ "Version" SG_ 579 OHCL_FrMapLftOn_Sta "19.12.01";
BA_ "Description" SG_ 579 OHCL_RrCurtainReq "This signal is Rear curtain switch On/Off signal

( The signal send 'On' during push switch only )";
BA_ "GenSigSendType" SG_ 579 OHCL_RrCurtainReq 4;
BA_ "UserSigValidity" SG_ 579 OHCL_RrCurtainReq 3;
BA_ "Version" SG_ 579 OHCL_RrCurtainReq "20.01.01";
BA_ "Description" SG_ 579 OHCL_FrMapRtOn_Sta "This signal is front right map lamp On/Off status";
BA_ "GenSigSendType" SG_ 579 OHCL_FrMapRtOn_Sta 4;
BA_ "TimeoutValue" SG_ 579 OHCL_FrMapRtOn_Sta "Old Value";
BA_ "UserSigValidity" SG_ 579 OHCL_FrMapRtOn_Sta 3;
BA_REL_ "GenSigTimeoutTime" BU_SG_REL_ ATS SG_ 579 OHCL_FrMapRtOn_Sta 1000;
BA_ "Version" SG_ 579 OHCL_FrMapRtOn_Sta "19.12.01";
BA_ "Description" SG_ 579 OHCL_FrRoomOn_Sta "This signal is front room lamp On/Off status ( all )";
BA_ "GenSigSendType" SG_ 579 OHCL_FrRoomOn_Sta 4;
BA_ "TimeoutValue" SG_ 579 OHCL_FrRoomOn_Sta "Old Value";
BA_ "UserSigValidity" SG_ 579 OHCL_FrRoomOn_Sta 3;
BA_REL_ "GenSigTimeoutTime" BU_SG_REL_ ATS SG_ 579 OHCL_FrRoomOn_Sta 1000;
BA_ "Version" SG_ 579 OHCL_FrRoomOn_Sta "19.12.01";
BA_ "Description" SG_ 579 OHCL_FrMoodOn_Sta "This signal is front mood map lamp On/Off status";
BA_ "GenSigSendType" SG_ 579 OHCL_FrMoodOn_Sta 4;
BA_ "UserSigValidity" SG_ 579 OHCL_FrMoodOn_Sta 3;
BA_REL_ "GenSigTimeoutTime" BU_SG_REL_ ATS SG_ 579 OHCL_FrMoodOn_Sta 1000;
BA_ "Version" SG_ 579 OHCL_FrMoodOn_Sta "19.12.01";
BA_ "GenMsgSendType" BO_ 1068 0;
BA_ "Description" SG_ 1068 RLPSU_ReclMtrPos "2¿­ LH ½ÃÆ® Recline ¸ðÅÍ À§Ä¡°ª ¼Û½Å

 - Seat Recline Position Information signal for 2nd LH seat";
BA_ "GenSigSendType" SG_ 1068 RLPSU_ReclMtrPos 4;
BA_ "UserSigValidity" SG_ 1068 RLPSU_ReclMtrPos 0;
BA_REL_ "GenSigTimeoutTime" BU_SG_REL_ PFSU SG_ 1068 RLPSU_ReclMtrPos 1500;
BA_REL_ "GenSigTimeoutTime" BU_SG_REL_ CGW_CCU SG_ 1068 RLPSU_ReclMtrPos 1500;
BA_ "NetworkRequest" SG_ 1068 RLPSU_ReclMtrPos 0;
BA_ "NetworkRequestHoldingTime" SG_ 1068 RLPSU_ReclMtrPos 5000;
BA_ "Version" SG_ 1068 RLPSU_ReclMtrPos "21.07.06";
BA_ "Description" SG_ 1068 RLPSU_RLSlidPos "2nd Left Seat Slide Position Information for button activatation / unactivation";
BA_ "GenSigSendType" SG_ 1068 RLPSU_RLSlidPos 4;
BA_ "UserSigValidity" SG_ 1068 RLPSU_RLSlidPos 0;
BA_REL_ "GenSigTimeoutTime" BU_SG_REL_ CGW_CCU SG_ 1068 RLPSU_RLSlidPos 1500;
BA_ "Version" SG_ 1068 RLPSU_RLSlidPos "21.07.06";
BA_ "Description" SG_ 1068 RLPSU_RLRclPos "2¿­ ÁÂÃø ½ÃÆ® ¹é ¸®Å¬¶óÀÌ´× À§Ä¡¿¡ µû¸¥ ¹öÆ° È°¼ºÈ­ / ºñÈ°¼ºÈ­";
BA_ "GenSigSendType" SG_ 1068 RLPSU_RLRclPos 4;
BA_ "UserSigValidity" SG_ 1068 RLPSU_RLRclPos 0;
BA_REL_ "GenSigTimeoutTime" BU_SG_REL_ CGW_CCU SG_ 1068 RLPSU_RLRclPos 1500;
BA_ "Version" SG_ 1068 RLPSU_RLRclPos "21.07.06";
BA_ "Description" SG_ 1068 RLPSU_RLTiltPos "2¿­ ÁÂÃø ½ÃÆ® Äí¼Ç Æ¿Æ® À§Ä¡¿¡ µû¸¥ ¹öÆ° È°¼ºÈ­ / ºñÈ°¼ºÈ­";
BA_ "GenSigSendType" SG_ 1068 RLPSU_RLTiltPos 4;
BA_ "UserSigValidity" SG_ 1068 RLPSU_RLTiltPos 0;
BA_REL_ "GenSigTimeoutTime" BU_SG_REL_ CGW_CCU SG_ 1068 RLPSU_RLTiltPos 1500;
BA_ "Version" SG_ 1068 RLPSU_RLTiltPos "21.07.06";
BA_ "Description" SG_ 1068 RLPSU_RLLegExtPos "2¿­ ÁÂÃø ½ÃÆ® ·¹±×·¹½ºÆ® ÀÍ½ºÅÙ¼Ç À§Ä¡¿¡ µû¸¥ ¹öÆ° È°¼ºÈ­ / ºñÈ°¼ºÈ­";
BA_ "GenSigSendType" SG_ 1068 RLPSU_RLLegExtPos 4;
BA_ "UserSigValidity" SG_ 1068 RLPSU_RLLegExtPos 0;
BA_REL_ "GenSigTimeoutTime" BU_SG_REL_ CGW_CCU SG_ 1068 RLPSU_RLLegExtPos 1500;
BA_ "Version" SG_ 1068 RLPSU_RLLegExtPos "21.07.06";
BA_ "Description" SG_ 1068 RLPSU_RLLegSupPos "2¿­ ÁÂÃø ½ÃÆ® ·¹±×¼­Æ÷Æ® À§Ä¡¿¡ µû¸¥ ¹öÆ° È°¼ºÈ­ / ºñÈ°¼ºÈ­";
BA_ "GenSigSendType" SG_ 1068 RLPSU_RLLegSupPos 4;
BA_ "UserSigValidity" SG_ 1068 RLPSU_RLLegSupPos 0;
BA_REL_ "GenSigTimeoutTime" BU_SG_REL_ CGW_CCU SG_ 1068 RLPSU_RLLegSupPos 1500;
BA_ "Version" SG_ 1068 RLPSU_RLLegSupPos "21.07.06";
BA_ "Description" SG_ 1068 RLPSU_RLHrestSlidPos "2nd Left Seat Head Rest Slide Position Information for button activatation / unactivation";
BA_ "GenSigSendType" SG_ 1068 RLPSU_RLHrestSlidPos 4;
BA_ "UserSigValidity" SG_ 1068 RLPSU_RLHrestSlidPos 0;
BA_REL_ "GenSigTimeoutTime" BU_SG_REL_ CGW_CCU SG_ 1068 RLPSU_RLHrestSlidPos 1500;
BA_ "Version" SG_ 1068 RLPSU_RLHrestSlidPos "21.07.06";
BA_ "Description" SG_ 1068 RLPSU_RLHrestHeightPos "2¿­ ÁÂÃø ½ÃÆ® Çìµå·¹½ºÆ® ÇÏÀÌÆ® À§Ä¡¿¡ µû¸¥ ¹öÆ° È°¼ºÈ­ / ºñÈ°¼ºÈ­";
BA_ "GenSigSendType" SG_ 1068 RLPSU_RLHrestHeightPos 4;
BA_ "UserSigValidity" SG_ 1068 RLPSU_RLHrestHeightPos 0;
BA_REL_ "GenSigTimeoutTime" BU_SG_REL_ CGW_CCU SG_ 1068 RLPSU_RLHrestHeightPos 1500;
BA_ "Version" SG_ 1068 RLPSU_RLHrestHeightPos "21.07.06";
BA_ "Description" SG_ 1068 RLPSU_Opt "PWR_HVU Option";
BA_ "GenSigSendType" SG_ 1068 RLPSU_Opt 4;
BA_ "UserSigValidity" SG_ 1068 RLPSU_Opt 0;
BA_REL_ "GenSigTimeoutTime" BU_SG_REL_ CGW_CCU SG_ 1068 RLPSU_Opt 1500;
BA_ "Version" SG_ 1068 RLPSU_Opt "19.03.05";
BA_ "Description" SG_ 1068 RLPSU_Opt_Captain "PWR_HVU Option_Captain";
BA_ "GenSigSendType" SG_ 1068 RLPSU_Opt_Captain 4;
BA_ "UserSigValidity" SG_ 1068 RLPSU_Opt_Captain 0;
BA_REL_ "GenSigTimeoutTime" BU_SG_REL_ CGW_CCU SG_ 1068 RLPSU_Opt_Captain 1500;
BA_ "Version" SG_ 1068 RLPSU_Opt_Captain "20.10.02";
BA_ "Description" SG_ 1068 RL_AutoRlxSta "ÈÄ¼® LH ½ÃÆ® ¿ÀÅä ¸±·º¼Ç µ¿ÀÛ »óÅÂ Á¤º¸";
BA_ "GenSigSendType" SG_ 1068 RL_AutoRlxSta 4;
BA_ "UserSigValidity" SG_ 1068 RL_AutoRlxSta 0;
BA_REL_ "GenSigTimeoutTime" BU_SG_REL_ APSU SG_ 1068 RL_AutoRlxSta 1500;
BA_REL_ "GenSigTimeoutTime" BU_SG_REL_ DPSU SG_ 1068 RL_AutoRlxSta 1500;
BA_ "NetworkRequest" SG_ 1068 RL_AutoRlxSta 0;
BA_ "NetworkRequestHoldingTime" SG_ 1068 RL_AutoRlxSta 5000;
BA_ "Version" SG_ 1068 RL_AutoRlxSta "21.06.10";
BA_ "Description" SG_ 1068 RL_FLStAutoRlxEnable "ÈÄ¼® LH ½ÃÆ® À§Ä¡¿¡ µû¸¥ Àü¼® LH ¿ÀÅä ¸±·º¼Ç µ¿ÀÛ ÆÇ´Ü";
BA_ "GenSigSendType" SG_ 1068 RL_FLStAutoRlxEnable 4;
BA_ "UserSigValidity" SG_ 1068 RL_FLStAutoRlxEnable 0;
BA_REL_ "GenSigTimeoutTime" BU_SG_REL_ APSU SG_ 1068 RL_FLStAutoRlxEnable 1500;
BA_REL_ "GenSigTimeoutTime" BU_SG_REL_ DPSU SG_ 1068 RL_FLStAutoRlxEnable 1500;
BA_ "NetworkRequest" SG_ 1068 RL_FLStAutoRlxEnable 0;
BA_ "NetworkRequestHoldingTime" SG_ 1068 RL_FLStAutoRlxEnable 5000;
BA_ "Version" SG_ 1068 RL_FLStAutoRlxEnable "21.06.10";
BA_ "Description" SG_ 1068 RLHVU_Opt_Captain "MNL_HVU Option_Captain";
BA_ "GenSigSendType" SG_ 1068 RLHVU_Opt_Captain 4;
BA_ "UserSigValidity" SG_ 1068 RLHVU_Opt_Captain 0;
BA_REL_ "GenSigTimeoutTime" BU_SG_REL_ CGW_CCU SG_ 1068 RLHVU_Opt_Captain 1500;
BA_ "Version" SG_ 1068 RLHVU_Opt_Captain "21.07.06";
BA_ "Description" SG_ 1068 RLPSU_PwrSeatOpt "2¿­ ÁÂÃø ¸®Å¬¶óÀÌ³Ê ½ÃÆ® ¿É¼Ç Á¤º¸";
BA_ "GenSigSendType" SG_ 1068 RLPSU_PwrSeatOpt 4;
BA_ "UserSigValidity" SG_ 1068 RLPSU_PwrSeatOpt 0;
BA_REL_ "GenSigTimeoutTime" BU_SG_REL_ CGW_CCU SG_ 1068 RLPSU_PwrSeatOpt 1500;
BA_ "Version" SG_ 1068 RLPSU_PwrSeatOpt "19.08.05";
BA_ "Description" SG_ 1068 RLPSU_PwrSeatPos "2¿­ ÁÂÃø ½ÃÆ® ¹é À§Ä¡¿¡ µû¸¥ ¹öÆ° È°¼ºÈ­ / ºñÈ°¼ºÈ­";
BA_ "GenSigSendType" SG_ 1068 RLPSU_PwrSeatPos 4;
BA_ "UserSigValidity" SG_ 1068 RLPSU_PwrSeatPos 0;
BA_REL_ "GenSigTimeoutTime" BU_SG_REL_ CGW_CCU SG_ 1068 RLPSU_PwrSeatPos 1500;
BA_ "Version" SG_ 1068 RLPSU_PwrSeatPos "21.07.06";
BA_ "GenMsgSendType" BO_ 1070 0;
BA_ "Description" SG_ 1070 RL_SHVU_HtSwHiIndSta "RL ½ÃÆ® ¿­¼± ½ºÀ§Ä¡ High Indicator Á¤º¸

-2nd LH Seat heater high Information";
BA_ "GenSigSendType" SG_ 1070 RL_SHVU_HtSwHiIndSta 4;
BA_ "UserSigValidity" SG_ 1070 RL_SHVU_HtSwHiIndSta 3;
BA_REL_ "GenSigTimeoutTime" BU_SG_REL_ ATS SG_ 1070 RL_SHVU_HtSwHiIndSta 1500;
BA_REL_ "GenSigTimeoutTime" BU_SG_REL_ CGW_CCU SG_ 1070 RL_SHVU_HtSwHiIndSta 1500;
BA_ "NetworkRequest" SG_ 1070 RL_SHVU_HtSwHiIndSta 0;
BA_ "NetworkRequestHoldingTime" SG_ 1070 RL_SHVU_HtSwHiIndSta 5000;
BA_ "Version" SG_ 1070 RL_SHVU_HtSwHiIndSta "21.07.06";
BA_ "Description" SG_ 1070 RL_SHVU_HtSwMidIndSta "RL ½ÃÆ® ¿­¼± ½ºÀ§Ä¡ Mid Indicator Á¤º¸

-2nd LH Seat heater mid Information";
BA_ "GenSigSendType" SG_ 1070 RL_SHVU_HtSwMidIndSta 4;
BA_ "UserSigValidity" SG_ 1070 RL_SHVU_HtSwMidIndSta 3;
BA_REL_ "GenSigTimeoutTime" BU_SG_REL_ ATS SG_ 1070 RL_SHVU_HtSwMidIndSta 1500;
BA_REL_ "GenSigTimeoutTime" BU_SG_REL_ CGW_CCU SG_ 1070 RL_SHVU_HtSwMidIndSta 1500;
BA_ "NetworkRequest" SG_ 1070 RL_SHVU_HtSwMidIndSta 0;
BA_ "NetworkRequestHoldingTime" SG_ 1070 RL_SHVU_HtSwMidIndSta 5000;
BA_ "Version" SG_ 1070 RL_SHVU_HtSwMidIndSta "21.07.06";
BA_ "Description" SG_ 1070 RL_SHVU_HtSwLowIndSta "RL ½ÃÆ® ¿­¼± ½ºÀ§Ä¡ Low Indicator Á¤º¸

-2nd LH Seat heater low Information";
BA_ "GenSigSendType" SG_ 1070 RL_SHVU_HtSwLowIndSta 4;
BA_ "UserSigValidity" SG_ 1070 RL_SHVU_HtSwLowIndSta 3;
BA_REL_ "GenSigTimeoutTime" BU_SG_REL_ ATS SG_ 1070 RL_SHVU_HtSwLowIndSta 1500;
BA_REL_ "GenSigTimeoutTime" BU_SG_REL_ CGW_CCU SG_ 1070 RL_SHVU_HtSwLowIndSta 1500;
BA_ "NetworkRequest" SG_ 1070 RL_SHVU_HtSwLowIndSta 0;
BA_ "NetworkRequestHoldingTime" SG_ 1070 RL_SHVU_HtSwLowIndSta 5000;
BA_ "Version" SG_ 1070 RL_SHVU_HtSwLowIndSta "21.07.06";
BA_ "Description" SG_ 1070 RL_SHVU_VntSwHiIndSta "RL ½ÃÆ® ÅëÇ³ ½ºÀ§Ä¡ High Indicator Á¤º¸

-2nd LH Seat vent high Information";
BA_ "GenSigSendType" SG_ 1070 RL_SHVU_VntSwHiIndSta 4;
BA_ "UserSigValidity" SG_ 1070 RL_SHVU_VntSwHiIndSta 3;
BA_REL_ "GenSigTimeoutTime" BU_SG_REL_ ATS SG_ 1070 RL_SHVU_VntSwHiIndSta 1500;
BA_REL_ "GenSigTimeoutTime" BU_SG_REL_ CGW_CCU SG_ 1070 RL_SHVU_VntSwHiIndSta 1500;
BA_ "NetworkRequest" SG_ 1070 RL_SHVU_VntSwHiIndSta 0;
BA_ "NetworkRequestHoldingTime" SG_ 1070 RL_SHVU_VntSwHiIndSta 5000;
BA_ "Version" SG_ 1070 RL_SHVU_VntSwHiIndSta "21.07.06";
BA_ "Description" SG_ 1070 RL_SHVU_VntSwMidIndSta "RL ½ÃÆ® ÅëÇ³ ½ºÀ§Ä¡ Mid Indicator Á¤º¸

-2nd LH Seat vent mid Information";
BA_ "GenSigSendType" SG_ 1070 RL_SHVU_VntSwMidIndSta 4;
BA_ "UserSigValidity" SG_ 1070 RL_SHVU_VntSwMidIndSta 3;
BA_REL_ "GenSigTimeoutTime" BU_SG_REL_ ATS SG_ 1070 RL_SHVU_VntSwMidIndSta 1500;
BA_REL_ "GenSigTimeoutTime" BU_SG_REL_ CGW_CCU SG_ 1070 RL_SHVU_VntSwMidIndSta 1500;
BA_ "NetworkRequest" SG_ 1070 RL_SHVU_VntSwMidIndSta 0;
BA_ "NetworkRequestHoldingTime" SG_ 1070 RL_SHVU_VntSwMidIndSta 5000;
BA_ "Version" SG_ 1070 RL_SHVU_VntSwMidIndSta "21.07.06";
BA_ "Description" SG_ 1070 RL_SHVU_VntSwLowIndSta "RL ½ÃÆ® ÅëÇ³ ½ºÀ§Ä¡ Low Indicator Á¤º¸

-2nd LH Seat vent low Information";
BA_ "GenSigSendType" SG_ 1070 RL_SHVU_VntSwLowIndSta 4;
BA_ "UserSigValidity" SG_ 1070 RL_SHVU_VntSwLowIndSta 3;
BA_REL_ "GenSigTimeoutTime" BU_SG_REL_ ATS SG_ 1070 RL_SHVU_VntSwLowIndSta 1500;
BA_REL_ "GenSigTimeoutTime" BU_SG_REL_ CGW_CCU SG_ 1070 RL_SHVU_VntSwLowIndSta 1500;
BA_ "NetworkRequest" SG_ 1070 RL_SHVU_VntSwLowIndSta 0;
BA_ "NetworkRequestHoldingTime" SG_ 1070 RL_SHVU_VntSwLowIndSta 5000;
BA_ "Version" SG_ 1070 RL_SHVU_VntSwLowIndSta "21.07.06";
BA_ "Description" SG_ 1070 RL_SHVU_HtBlcUsmSta "RL Seat Heater Balance Status";
BA_ "GenSigSendType" SG_ 1070 RL_SHVU_HtBlcUsmSta 4;
BA_ "UserSigValidity" SG_ 1070 RL_SHVU_HtBlcUsmSta 3;
BA_REL_ "GenSigTimeoutTime" BU_SG_REL_ ATS SG_ 1070 RL_SHVU_HtBlcUsmSta 1500;
BA_REL_ "GenSigTimeoutTime" BU_SG_REL_ CGW_CCU SG_ 1070 RL_SHVU_HtBlcUsmSta 1500;
BA_REL_ "GenSigTimeoutTime" BU_SG_REL_ CGW_CCU SG_ 1070 RL_SHVU_HtBlcUsmSta 1500;
BA_ "NetworkRequest" SG_ 1070 RL_SHVU_HtBlcUsmSta 0;
BA_ "NetworkRequestHoldingTime" SG_ 1070 RL_SHVU_HtBlcUsmSta 5000;
BA_ "Version" SG_ 1070 RL_SHVU_HtBlcUsmSta "21.07.06";
BA_ "GenMsgSendType" BO_ 1069 0;
BA_ "Description" SG_ 1069 RRPSU_ReclMtrPos "2¿­ RH ½ÃÆ® Recline ¸ðÅÍ À§Ä¡°ª ¼Û½Å

 - Seat Recline Position Information signal for 2nd RH seat";
BA_ "GenSigSendType" SG_ 1069 RRPSU_ReclMtrPos 4;
BA_ "UserSigValidity" SG_ 1069 RRPSU_ReclMtrPos 0;
BA_REL_ "GenSigTimeoutTime" BU_SG_REL_ PFSU SG_ 1069 RRPSU_ReclMtrPos 1500;
BA_REL_ "GenSigTimeoutTime" BU_SG_REL_ CGW_CCU SG_ 1069 RRPSU_ReclMtrPos 1500;
BA_ "NetworkRequest" SG_ 1069 RRPSU_ReclMtrPos 0;
BA_ "NetworkRequestHoldingTime" SG_ 1069 RRPSU_ReclMtrPos 5000;
BA_ "Version" SG_ 1069 RRPSU_ReclMtrPos "19.06.01";
BA_ "Description" SG_ 1069 RRPSU_PwrSeatOpt "2¿­ ¿ìÃø ¸®Å¬¶óÀÌ³Ê ½ÃÆ® ¿É¼Ç Á¤º¸";
BA_ "GenSigSendType" SG_ 1069 RRPSU_PwrSeatOpt 4;
BA_ "UserSigValidity" SG_ 1069 RRPSU_PwrSeatOpt 0;
BA_REL_ "GenSigTimeoutTime" BU_SG_REL_ CGW_CCU SG_ 1069 RRPSU_PwrSeatOpt 1500;
BA_ "Version" SG_ 1069 RRPSU_PwrSeatOpt "19.08.05";
BA_ "Description" SG_ 1069 RRPSU_PwrSeatPos "2¿­ ¿ìÃø ½ÃÆ® ¹é À§Ä¡¿¡ µû¸¥ ¹öÆ° È°¼ºÈ­ / ºñÈ°¼ºÈ­";
BA_ "GenSigSendType" SG_ 1069 RRPSU_PwrSeatPos 4;
BA_ "UserSigValidity" SG_ 1069 RRPSU_PwrSeatPos 0;
BA_REL_ "GenSigTimeoutTime" BU_SG_REL_ CGW_CCU SG_ 1069 RRPSU_PwrSeatPos 1500;
BA_ "Version" SG_ 1069 RRPSU_PwrSeatPos "19.10.07";
BA_ "Description" SG_ 1069 RRPSU_RRSlidPos "2¿­ ¿ìÃø ½ÃÆ® ½½¶óÀÌµå ¸ðÅÍ À§Ä¡¿¡ µû¸¥ ¹öÆ° È°¼ºÈ­ / ºñÈ°¼ºÈ­";
BA_ "GenSigSendType" SG_ 1069 RRPSU_RRSlidPos 4;
BA_ "UserSigValidity" SG_ 1069 RRPSU_RRSlidPos 0;
BA_REL_ "GenSigTimeoutTime" BU_SG_REL_ CGW_CCU SG_ 1069 RRPSU_RRSlidPos 1500;
BA_ "Version" SG_ 1069 RRPSU_RRSlidPos "20.05.03";
BA_ "Description" SG_ 1069 RRPSU_RRRclPos "2¿­ ¿ìÃø ½ÃÆ® ¸®Å¬¶óÀÌ³Ê ¸ðÅÍ À§Ä¡¿¡ µû¸¥ ¹öÆ° È°¼ºÈ­ / ºñÈ°¼ºÈ­";
BA_ "GenSigSendType" SG_ 1069 RRPSU_RRRclPos 4;
BA_ "UserSigValidity" SG_ 1069 RRPSU_RRRclPos 0;
BA_REL_ "GenSigTimeoutTime" BU_SG_REL_ CGW_CCU SG_ 1069 RRPSU_RRRclPos 1500;
BA_ "Version" SG_ 1069 RRPSU_RRRclPos "20.05.03";
BA_ "Description" SG_ 1069 RRPSU_RRTiltPos "2¿­ ¿ìÃø ½ÃÆ® Äí¼Ç Æ¿Æ® ¸ðÅÍ À§Ä¡¿¡ µû¸¥ ¹öÆ° È°¼ºÈ­ / ºñÈ°¼ºÈ­";
BA_ "GenSigSendType" SG_ 1069 RRPSU_RRTiltPos 4;
BA_ "UserSigValidity" SG_ 1069 RRPSU_RRTiltPos 0;
BA_REL_ "GenSigTimeoutTime" BU_SG_REL_ CGW_CCU SG_ 1069 RRPSU_RRTiltPos 1500;
BA_ "Version" SG_ 1069 RRPSU_RRTiltPos "20.05.03";
BA_ "Description" SG_ 1069 RRPSU_RRLegExtPos "2¿­ ¿ìÃø ½ÃÆ® ·¹±× ÀÍ½ºÅÙ¼Ç (ÀüÈÄ¹æ) ¸ðÅÍ À§Ä¡¿¡ µû¸¥ ¹öÆ° È°¼ºÈ­ / ºñÈ°¼ºÈ­";
BA_ "GenSigSendType" SG_ 1069 RRPSU_RRLegExtPos 4;
BA_ "UserSigValidity" SG_ 1069 RRPSU_RRLegExtPos 0;
BA_REL_ "GenSigTimeoutTime" BU_SG_REL_ CGW_CCU SG_ 1069 RRPSU_RRLegExtPos 1500;
BA_ "Version" SG_ 1069 RRPSU_RRLegExtPos "20.05.03";
BA_ "Description" SG_ 1069 RRPSU_RRLegSupPos "2¿­ ¿ìÃø ½ÃÆ® ·¹±×ÀÍ½ºÅÙ¼Ç (»óÇÏ¹æ) ¸ðÅÍ À§Ä¡¿¡ µû¸¥ ¹öÆ° È°¼ºÈ­ / ºñÈ°¼ºÈ­";
BA_ "GenSigSendType" SG_ 1069 RRPSU_RRLegSupPos 4;
BA_ "UserSigValidity" SG_ 1069 RRPSU_RRLegSupPos 0;
BA_REL_ "GenSigTimeoutTime" BU_SG_REL_ CGW_CCU SG_ 1069 RRPSU_RRLegSupPos 1500;
BA_ "Version" SG_ 1069 RRPSU_RRLegSupPos "20.05.03";
BA_ "Description" SG_ 1069 RRPSU_RRStEsyAcsUSMSta "Rear RH Seat EasyAccess USM Setting";
BA_ "GenSigSendType" SG_ 1069 RRPSU_RRStEsyAcsUSMSta 4;
BA_ "UserSigValidity" SG_ 1069 RRPSU_RRStEsyAcsUSMSta 0;
BA_REL_ "GenSigTimeoutTime" BU_SG_REL_ CGW_CCU SG_ 1069 RRPSU_RRStEsyAcsUSMSta 1500;
BA_ "Version" SG_ 1069 RRPSU_RRStEsyAcsUSMSta "18.07.01";
BA_ "Description" SG_ 1069 RRPSU_RRHrestSlidPos "2¿­ ¿ìÃø ½ÃÆ® Çìµå·¹½ºÆ® ½½¶óÀÌµå À§Ä¡¿¡ µû¸¥ ¹öÆ° È°¼ºÈ­ / ºñÈ°¼ºÈ­";
BA_ "GenSigSendType" SG_ 1069 RRPSU_RRHrestSlidPos 4;
BA_ "UserSigValidity" SG_ 1069 RRPSU_RRHrestSlidPos 0;
BA_REL_ "GenSigTimeoutTime" BU_SG_REL_ CGW_CCU SG_ 1069 RRPSU_RRHrestSlidPos 1500;
BA_ "Version" SG_ 1069 RRPSU_RRHrestSlidPos "20.05.03";
BA_ "Description" SG_ 1069 RRPSU_RRHrestHeightPos "2¿­ ¿ìÃø ½ÃÆ® Çìµå·¹½ºÆ® ÇÏÀÌÆ® ¸ðÅÍ À§Ä¡¿¡ µû¸¥ ¹öÆ° È°¼ºÈ­ / ºñÈ°¼ºÈ­";
BA_ "GenSigSendType" SG_ 1069 RRPSU_RRHrestHeightPos 4;
BA_ "UserSigValidity" SG_ 1069 RRPSU_RRHrestHeightPos 0;
BA_REL_ "GenSigTimeoutTime" BU_SG_REL_ CGW_CCU SG_ 1069 RRPSU_RRHrestHeightPos 1500;
BA_ "Version" SG_ 1069 RRPSU_RRHrestHeightPos "20.05.03";
BA_ "Description" SG_ 1069 RRPSU_Opt_Captain "PWR_HVU Option_Captain";
BA_ "GenSigSendType" SG_ 1069 RRPSU_Opt_Captain 4;
BA_ "UserSigValidity" SG_ 1069 RRPSU_Opt_Captain 0;
BA_REL_ "GenSigTimeoutTime" BU_SG_REL_ CGW_CCU SG_ 1069 RRPSU_Opt_Captain 1500;
BA_ "Version" SG_ 1069 RRPSU_Opt_Captain "20.10.02";
BA_ "Description" SG_ 1069 RR_AutoRlxSta "ÈÄ¼® RH ½ÃÆ® ¿ÀÅä ¸±·º¼Ç µ¿ÀÛ »óÅÂ Á¤º¸";
BA_ "GenSigSendType" SG_ 1069 RR_AutoRlxSta 4;
BA_ "UserSigValidity" SG_ 1069 RR_AutoRlxSta 0;
BA_REL_ "GenSigTimeoutTime" BU_SG_REL_ APSU SG_ 1069 RR_AutoRlxSta 1500;
BA_REL_ "GenSigTimeoutTime" BU_SG_REL_ DPSU SG_ 1069 RR_AutoRlxSta 1500;
BA_ "NetworkRequest" SG_ 1069 RR_AutoRlxSta 0;
BA_ "NetworkRequestHoldingTime" SG_ 1069 RR_AutoRlxSta 5000;
BA_ "Version" SG_ 1069 RR_AutoRlxSta "21.06.10";
BA_ "Description" SG_ 1069 RR_FRStAutoRlxEnable "ÈÄ¼® RH ½ÃÆ® À§Ä¡¿¡ µû¸¥ Àü¼® RH ¿ÀÅä ¸±·º¼Ç µ¿ÀÛ ÆÇ´Ü ½ÅÈ£";
BA_ "GenSigSendType" SG_ 1069 RR_FRStAutoRlxEnable 4;
BA_ "UserSigValidity" SG_ 1069 RR_FRStAutoRlxEnable 0;
BA_REL_ "GenSigTimeoutTime" BU_SG_REL_ APSU SG_ 1069 RR_FRStAutoRlxEnable 1500;
BA_REL_ "GenSigTimeoutTime" BU_SG_REL_ DPSU SG_ 1069 RR_FRStAutoRlxEnable 1500;
BA_ "NetworkRequest" SG_ 1069 RR_FRStAutoRlxEnable 0;
BA_ "NetworkRequestHoldingTime" SG_ 1069 RR_FRStAutoRlxEnable 5000;
BA_ "Version" SG_ 1069 RR_FRStAutoRlxEnable "21.06.10";
BA_ "Description" SG_ 1069 RRHVU_Opt_Captain "MNL_HVU Option_Captain";
BA_ "GenSigSendType" SG_ 1069 RRHVU_Opt_Captain 4;
BA_ "UserSigValidity" SG_ 1069 RRHVU_Opt_Captain 0;
BA_REL_ "GenSigTimeoutTime" BU_SG_REL_ CGW_CCU SG_ 1069 RRHVU_Opt_Captain 1500;
BA_ "Version" SG_ 1069 RRHVU_Opt_Captain "21.07.06";
BA_ "Description" SG_ 1069 RRPSU_RLStEsyAcsUSMSta "Rear LH Seat EasyAccess USM Setting";
BA_ "GenSigSendType" SG_ 1069 RRPSU_RLStEsyAcsUSMSta 4;
BA_ "UserSigValidity" SG_ 1069 RRPSU_RLStEsyAcsUSMSta 0;
BA_REL_ "GenSigTimeoutTime" BU_SG_REL_ CGW_CCU SG_ 1069 RRPSU_RLStEsyAcsUSMSta 1500;
BA_ "Version" SG_ 1069 RRPSU_RLStEsyAcsUSMSta "18.07.01";
BA_ "Description" SG_ 1069 RRPSU_Opt "PWR_HVU Option";
BA_ "GenSigSendType" SG_ 1069 RRPSU_Opt 4;
BA_ "UserSigValidity" SG_ 1069 RRPSU_Opt 0;
BA_REL_ "GenSigTimeoutTime" BU_SG_REL_ CGW_CCU SG_ 1069 RRPSU_Opt 1500;
BA_ "Version" SG_ 1069 RRPSU_Opt "19.03.05";
BA_ "GenMsgSendType" BO_ 1071 0;
BA_ "Description" SG_ 1071 RR_SHVU_HtSwHiIndSta "RR ½ÃÆ® ¿­¼± ½ºÀ§Ä¡ High Indicator Á¤º¸

-2nd RH Seat heater high Information";
BA_ "GenSigSendType" SG_ 1071 RR_SHVU_HtSwHiIndSta 4;
BA_ "UserSigValidity" SG_ 1071 RR_SHVU_HtSwHiIndSta 3;
BA_REL_ "GenSigTimeoutTime" BU_SG_REL_ ATS SG_ 1071 RR_SHVU_HtSwHiIndSta 1500;
BA_REL_ "GenSigTimeoutTime" BU_SG_REL_ CGW_CCU SG_ 1071 RR_SHVU_HtSwHiIndSta 1500;
BA_ "NetworkRequest" SG_ 1071 RR_SHVU_HtSwHiIndSta 0;
BA_ "NetworkRequestHoldingTime" SG_ 1071 RR_SHVU_HtSwHiIndSta 5000;
BA_ "Version" SG_ 1071 RR_SHVU_HtSwHiIndSta "21.07.06";
BA_ "Description" SG_ 1071 RR_SHVU_HtSwMidIndSta "RL ½ÃÆ® ¿­¼± ½ºÀ§Ä¡ Mid Indicator Á¤º¸

-2nd LH Seat heater mid Information";
BA_ "GenSigSendType" SG_ 1071 RR_SHVU_HtSwMidIndSta 4;
BA_ "UserSigValidity" SG_ 1071 RR_SHVU_HtSwMidIndSta 3;
BA_REL_ "GenSigTimeoutTime" BU_SG_REL_ ATS SG_ 1071 RR_SHVU_HtSwMidIndSta 1500;
BA_REL_ "GenSigTimeoutTime" BU_SG_REL_ CGW_CCU SG_ 1071 RR_SHVU_HtSwMidIndSta 1500;
BA_ "NetworkRequest" SG_ 1071 RR_SHVU_HtSwMidIndSta 0;
BA_ "NetworkRequestHoldingTime" SG_ 1071 RR_SHVU_HtSwMidIndSta 5000;
BA_ "Version" SG_ 1071 RR_SHVU_HtSwMidIndSta "21.07.06";
BA_ "Description" SG_ 1071 RR_SHVU_HtSwLowIndSta "RR ½ÃÆ® ¿­¼± ½ºÀ§Ä¡ Low Indicator Á¤º¸

-2nd RH Seat heater low Information";
BA_ "GenSigSendType" SG_ 1071 RR_SHVU_HtSwLowIndSta 4;
BA_ "UserSigValidity" SG_ 1071 RR_SHVU_HtSwLowIndSta 3;
BA_REL_ "GenSigTimeoutTime" BU_SG_REL_ ATS SG_ 1071 RR_SHVU_HtSwLowIndSta 1500;
BA_REL_ "GenSigTimeoutTime" BU_SG_REL_ CGW_CCU SG_ 1071 RR_SHVU_HtSwLowIndSta 1500;
BA_ "NetworkRequest" SG_ 1071 RR_SHVU_HtSwLowIndSta 0;
BA_ "NetworkRequestHoldingTime" SG_ 1071 RR_SHVU_HtSwLowIndSta 5000;
BA_ "Version" SG_ 1071 RR_SHVU_HtSwLowIndSta "21.07.06";
BA_ "Description" SG_ 1071 RR_SHVU_VntSwHiIndSta "RR ½ÃÆ® ÅëÇ³ ½ºÀ§Ä¡ High Indicator Á¤º¸

-2nd RH Seat vent high Information";
BA_ "GenSigSendType" SG_ 1071 RR_SHVU_VntSwHiIndSta 4;
BA_ "UserSigValidity" SG_ 1071 RR_SHVU_VntSwHiIndSta 3;
BA_REL_ "GenSigTimeoutTime" BU_SG_REL_ ATS SG_ 1071 RR_SHVU_VntSwHiIndSta 1500;
BA_REL_ "GenSigTimeoutTime" BU_SG_REL_ CGW_CCU SG_ 1071 RR_SHVU_VntSwHiIndSta 1500;
BA_ "NetworkRequest" SG_ 1071 RR_SHVU_VntSwHiIndSta 0;
BA_ "NetworkRequestHoldingTime" SG_ 1071 RR_SHVU_VntSwHiIndSta 5000;
BA_ "Version" SG_ 1071 RR_SHVU_VntSwHiIndSta "21.07.06";
BA_ "Description" SG_ 1071 RR_SHVU_VntSwMidIndSta "RR ½ÃÆ® ÅëÇ³ ½ºÀ§Ä¡ Mid Indicator Á¤º¸

-2nd RH Seat vent mid Information";
BA_ "GenSigSendType" SG_ 1071 RR_SHVU_VntSwMidIndSta 4;
BA_ "UserSigValidity" SG_ 1071 RR_SHVU_VntSwMidIndSta 3;
BA_REL_ "GenSigTimeoutTime" BU_SG_REL_ ATS SG_ 1071 RR_SHVU_VntSwMidIndSta 1500;
BA_REL_ "GenSigTimeoutTime" BU_SG_REL_ CGW_CCU SG_ 1071 RR_SHVU_VntSwMidIndSta 1500;
BA_ "NetworkRequest" SG_ 1071 RR_SHVU_VntSwMidIndSta 0;
BA_ "NetworkRequestHoldingTime" SG_ 1071 RR_SHVU_VntSwMidIndSta 5000;
BA_ "Version" SG_ 1071 RR_SHVU_VntSwMidIndSta "21.07.06";
BA_ "Description" SG_ 1071 RR_SHVU_VntSwLowIndSta "RR ½ÃÆ® ÅëÇ³ ½ºÀ§Ä¡ Low Indicator Á¤º¸

-2nd RH Seat vent low Information";
BA_ "GenSigSendType" SG_ 1071 RR_SHVU_VntSwLowIndSta 4;
BA_ "UserSigValidity" SG_ 1071 RR_SHVU_VntSwLowIndSta 3;
BA_REL_ "GenSigTimeoutTime" BU_SG_REL_ ATS SG_ 1071 RR_SHVU_VntSwLowIndSta 1500;
BA_REL_ "GenSigTimeoutTime" BU_SG_REL_ CGW_CCU SG_ 1071 RR_SHVU_VntSwLowIndSta 1500;
BA_ "NetworkRequest" SG_ 1071 RR_SHVU_VntSwLowIndSta 0;
BA_ "NetworkRequestHoldingTime" SG_ 1071 RR_SHVU_VntSwLowIndSta 5000;
BA_ "Version" SG_ 1071 RR_SHVU_VntSwLowIndSta "21.07.06";
BA_ "Description" SG_ 1071 RR_SHVU_HtBlcUsmSta "RR Seat Heater Balance Status";
BA_ "GenSigSendType" SG_ 1071 RR_SHVU_HtBlcUsmSta 4;
BA_ "UserSigValidity" SG_ 1071 RR_SHVU_HtBlcUsmSta 3;
BA_REL_ "GenSigTimeoutTime" BU_SG_REL_ ATS SG_ 1071 RR_SHVU_HtBlcUsmSta 1500;
BA_REL_ "GenSigTimeoutTime" BU_SG_REL_ CGW_CCU SG_ 1071 RR_SHVU_HtBlcUsmSta 1500;
BA_REL_ "GenSigTimeoutTime" BU_SG_REL_ CGW_CCU SG_ 1071 RR_SHVU_HtBlcUsmSta 1500;
BA_ "NetworkRequest" SG_ 1071 RR_SHVU_HtBlcUsmSta 0;
BA_ "NetworkRequestHoldingTime" SG_ 1071 RR_SHVU_HtBlcUsmSta 5000;
BA_ "Version" SG_ 1071 RR_SHVU_HtBlcUsmSta "21.07.06";
BA_ "GenMsgSendType" BO_ 1067 0;
BA_ "Description" SG_ 1067 SCM_SWVerMajor1 "Indicate the SCM software version as follows:

- The software version is displayed in three digits.

- The Major and Minor digits are separated by '.'

- Signal values are transmitted to ASCII codes.



¡Ø Example

SCM_SWVerMajor1 : 0x41 (HEX) -> ASCII CODE : 'A' 

SCM_SWVerMinor1 : 0x30 (HEX) -> ASCII CODE : '0'

SCM_SWVerMinor2 : 0x33 (HEX) -> ASCII CODE : '3'

=> SCM S/W Ver is displayed 'A.03'";
BA_ "GenSigSendType" SG_ 1067 SCM_SWVerMajor1 4;
BA_ "UserSigValidity" SG_ 1067 SCM_SWVerMajor1 0;
BA_REL_ "GenSigTimeoutTime" BU_SG_REL_ CGW_CCU SG_ 1067 SCM_SWVerMajor1 1500;
BA_ "Version" SG_ 1067 SCM_SWVerMajor1 "20.12.04";
BA_ "Description" SG_ 1067 SCM_SWVerMinor1 "Indicate the SCM software version as follows:

- The software version is displayed in three digits.

- The Major and Minor digits are separated by '.'

- Signal values are transmitted to ASCII codes.



¡Ø Example

SCM_SWVerMajor1 : 0x41 (HEX) -> ASCII CODE : 'A' 

SCM_SWVerMinor1 : 0x30 (HEX) -> ASCII CODE : '0'

SCM_SWVerMinor2 : 0x33 (HEX) -> ASCII CODE : '3'

=> SCM S/W Ver is displayed 'A.03'";
BA_ "GenSigSendType" SG_ 1067 SCM_SWVerMinor1 4;
BA_ "UserSigValidity" SG_ 1067 SCM_SWVerMinor1 0;
BA_REL_ "GenSigTimeoutTime" BU_SG_REL_ CGW_CCU SG_ 1067 SCM_SWVerMinor1 1500;
BA_ "Version" SG_ 1067 SCM_SWVerMinor1 "18.10.06";
BA_ "Description" SG_ 1067 SCM_SWVerMinor2 "Indicate the SCM software version as follows:

- The software version is displayed in three digits.

- The Major and Minor digits are separated by '.'

- Signal values are transmitted to ASCII codes.



¡Ø Example

SCM_SWVerMajor1 : 0x41 (HEX) -> ASCII CODE : 'A' 

SCM_SWVerMinor1 : 0x30 (HEX) -> ASCII CODE : '0'

SCM_SWVerMinor2 : 0x33 (HEX) -> ASCII CODE : '3'

=> SCM S/W Ver is displayed 'A.03'";
BA_ "GenSigSendType" SG_ 1067 SCM_SWVerMinor2 4;
BA_ "UserSigValidity" SG_ 1067 SCM_SWVerMinor2 0;
BA_REL_ "GenSigTimeoutTime" BU_SG_REL_ CGW_CCU SG_ 1067 SCM_SWVerMinor2 1500;
BA_ "Version" SG_ 1067 SCM_SWVerMinor2 "18.10.06";
VAL_ 1546 AMP_SupportBeepVolumeControl 0 "Null" 1 "False" 2 "True" 3 "Invalid" ;
VAL_ 1546 AMP_SupportESEVMode 0 "Null" 1 "False" 2 "True" 3 "Invalid" ;
VAL_ 1546 AMP_SupportDSC 0 "Null" 1 "False" 2 "True" 3 "Invalid" ;
VAL_ 1546 AMP_SupportANCMode 0 "Null" 1 "False" 2 "True" 3 "Invalid" ;
VAL_ 1546 AMP_MakerID 0 "Initial Value" 1 "Mobis" 2 "Beats by Dr.Dre" 3 "Harman_Becker" 4 "BOSE" 5 "Bang&Olufsen" 6 "Meridian" 7 "0x07~0xFF:Invalid" 255 "0x07~0xFF:Invalid" ;
VAL_ 1546 AMP_SupportQLS 0 "Null" 1 "False" 2 "True" 3 "Invalid" ;
VAL_ 1546 AMP_SupportQLS_2step 0 "Null" 1 "False" 2 "True" 3 "Invalid" ;
VAL_ 1546 AMP_SupportHorizon 0 "Null" 1 "False" 2 "True" 3 "Invalid" ;
VAL_ 1546 AMP_SupportASDMode 0 "Null" 1 "False" 2 "True" 3 "Invalid" ;
VAL_ 1546 AMP_SupportIntelliQ 0 "Null" 1 "False" 2 "True" 3 "Invalid" ;
VAL_ 1546 AMP_SupportCenterpoint 0 "Null" 1 "False" 2 "True" 3 "Invalid" ;
VAL_ 1546 AMP_SupportSignalDoctor 0 "Null" 1 "False" 2 "True" 3 "Invalid" ;
VAL_ 1546 AMP_SupportLiveDynamicMode 0 "Null" 1 "False" 2 "True(Off On)" 3 "True(Off Natural Concert)" 4 "Reserved" 5 "Reserved" 6 "Reserved" 7 "Invalid" ;
VAL_ 1546 AMP_Support_ElecSound 0 "Null" 1 "False" 2 "True" 3 "Invalid" ;
VAL_ 1064 APSU_DiagSta 0 "Stop Diag" 1 "Start Diag" 2 "Not Used" 3 "Error Indicator" ;
VAL_ 1064 APSU_AstAllLmtSta 0 "Default" 1 "Not Set" 2 "All Set" 3 "Invalid" ;
VAL_ 1064 APSU_EsyAcsGetOnSta 0 "off" 1 "on" 2 "Not Used" 3 "Error Indicator" ;
VAL_ 1064 APSU_EsyAcsGetOffSta 0 "off" 1 "on" 2 "Not Used" 3 "Error Indicator" ;
VAL_ 1064 APSU_EsyAcsStpSta 0 "off" 1 "on" 2 "Not Used" 3 "Error Indicator" ;
VAL_ 1064 APSU_RVal 0 "Default Value" 1 "Off(Disable)" 2 "Enable" 3 "Reserved" 4 "Reserved" 5 "Reserved" 6 "Reserved" 7 "Invalid" ;
VAL_ 639 ATS_RRSeatHeaterSW 0 "Default" 1 "Short On" 2 "Long On" 3 "Invalid" ;
VAL_ 639 ATS_RLSeatHeaterUpSW 0 "Default" 1 "Short On" 2 "Long On" 3 "Invalid" ;
VAL_ 639 ATS_RRSeatVentDownSW 0 "Default" 1 "Short On" 2 "Long On" 3 "Invalid" ;
VAL_ 639 ATS_RLSeatVentDownSW 0 "Default" 1 "Short On" 2 "Long On" 3 "Invalid" ;
VAL_ 639 ATS_RLMemoryRestBtn 0 "Default" 1 "Off" 2 "On" 3 "Invalid" ;
VAL_ 639 ATS_RLMemoryReturnBtn 0 "Default" 1 "Off" 2 "On" 3 "Invalid" ;
VAL_ 639 ATS_RLSeatHeaterSW 0 "Default" 1 "Short On" 2 "Long On" 3 "Invalid" ;
VAL_ 639 ATS_RRMemoryRestBtn 0 "Default" 1 "Off" 2 "On" 3 "Invalid" ;
VAL_ 639 ATS_RRMemoryReturnBtn 0 "Default" 1 "Off" 2 "On" 3 "Invalid" ;
VAL_ 639 ATS_RRMemoryAvWtcBtn 0 "Default" 1 "Off" 2 "On" 3 "Invalid" ;
VAL_ 639 ATS_RRMemoryReadingBtn 0 "Default" 1 "Off" 2 "On" 3 "Invalid" ;
VAL_ 639 ATS_RRRestModBtnSTD 0 "Default" 1 "Off" 2 "On" 3 "Invalid" ;
VAL_ 639 ATS_RRResetModBtnSTD 0 "Default" 1 "Off" 2 "On" 3 "Invalid" ;
VAL_ 639 ATS_RRAvWtcModBtnSTD 0 "Default" 1 "Off" 2 "On" 3 "Invalid" ;
VAL_ 639 ATS_RRReadingModBtnSTD 0 "Default" 1 "Off" 2 "On" 3 "Invalid" ;
VAL_ 639 ATS_RRSeatVentSW 0 "Default" 1 "Short On" 2 "Long On" 3 "Invalid" ;
VAL_ 639 ATS_RLRestModBtnSTD 0 "Default" 1 "Off" 2 "On" 3 "Invalid" ;
VAL_ 639 ATS_RLResetModBtnSTD 0 "Default" 1 "Off" 2 "On" 3 "Invalid" ;
VAL_ 639 ATS_RRModestateStopBtn 0 "Default" 1 "Off" 2 "On" 3 "Invalid" ;
VAL_ 639 ATS_RLModestateStopBtn 0 "Default" 1 "Off" 2 "On" 3 "Invalid" ;
VAL_ 639 ATS_RLResetRestBtn 0 "Default" 1 "Off" 2 "On" 3 "Invalid" ;
VAL_ 639 ATS_RLResetReturnBtn 0 "Default" 1 "Off" 2 "On" 3 "Invalid" ;
VAL_ 639 ATS_RRResetRestBtn 0 "Default" 1 "Off" 2 "On" 3 "Invalid" ;
VAL_ 639 ATS_RRResetReturnBtn 0 "Default" 1 "Off" 2 "On" 3 "Invalid" ;
VAL_ 639 ATS_RRResetAvWtcBtn 0 "Default" 1 "Off" 2 "On" 3 "Invalid" ;
VAL_ 639 ATS_RRResetReadingBtn 0 "Default" 1 "Off" 2 "On" 3 "Invalid" ;
VAL_ 639 ATS_RLSeatVentSW 0 "Default" 1 "Short On" 2 "Long On" 3 "Invalid" ;
VAL_ 639 ATS_RRSeatHeaterUpSW 0 "Default" 1 "Short On" 2 "Long On" 3 "Invalid" ;
VAL_ 1058 Wiper_PrkngPosSta 0 "else" 1 "Parking Position" 2 "Not Used" 3 "Error Indicator" ;
VAL_ 1058 Wiper_RainSnsrOptionTyp 0 "Non Rain Sensor Option" 1 "Rain Sensor Option" 2 "Not Used" 3 "Error Indicator" ;
VAL_ 1058 Wiper_RainSnsrSta 0 "OFF" 1 "Rain Detected" 2 "Low" 3 "High" 4 "Fault 1" 5 "Reserved" 6 "Reserved" 7 "Reserved" 8 "Reserved" 9 "Reserved" 10 "Reserved" 11 "Reserved" 12 "Reserved" 13 "Reserved" 14 "Not Used" 15 "Error Indicator" ;
VAL_ 1058 Wiper_HtWshNzzlCmd 0 "Off" 1 "On" 2 "Not Used" 3 "Error Indicator" ;
VAL_ 1058 BCM_GearPosPSta 0 "Off" 1 "P" 2 "Not Used" 3 "Error Indicator" ;
VAL_ 1058 BCM_SunRoofOpnSta 0 "Close" 1 "Open" 2 "Not Used" 3 "Error Indicator" ;
VAL_ 1058 SunRoof_RrBlindErrSta 0 "No error" 1 "Thermal Protection Active" 2 "Initialized Status" 3 "Undefined ECU Error" 4 "Switch Error" 5 "Voltage error" 6 "Complex Error" 7 "Invalid" ;
VAL_ 1058 Wiper_AutoWashModeSta 0 "Auto Wash Mode Off" 1 "Auto Wash Mode On" 2 "Not Used" 3 "Error Indicator" ;
VAL_ 2424579841 DATC_TnnlClimtUSMSta 0 "Default" 1 "OFF" 2 "ON" 3 "Error Indicator" ;
VAL_ 2424579841 DATC_ProximitySnsrSta 0 "Default(Not Apply)" 1 "OFF" 2 "ON" 3 "Error Indicator" ;
VAL_ 2424579841 DATC_TunnelFuncOff4AutoDfgReq 0 "Default" 1 "Tunnel Turn off" 2 "Not Used" 3 "Error Indicator" ;
VAL_ 2424579841 DATC_RrCtlLckSta 0 "Default" 1 "Rear Lock OFF" 2 "Rear Lock ON" 3 "Error Indicator" ;
VAL_ 2424579841 DATC_DrvrStHtrUSMSta 0 "NOT APPLY" 1 "OFF" 2 "ON" 3 "Error Indicator" ;
VAL_ 2424579841 DATC_InDrctVntUSMSta 0 "Default" 1 "InDirectVent USM OFF" 2 "InDirectVent USM ON" 3 "Invalid" ;
VAL_ 2424579841 DATC_WshFldUSMSta 0 "Default" 1 "OFF" 2 "ON" 3 "Invalid" ;
VAL_ 2424579841 DATC_DfgLgcUSMSta 0 "Default" 1 "OFF" 2 "ON" 3 "Invalid" ;
VAL_ 2424579841 DATC_AutoFrshUSMSta 0 "Default" 1 "OFF" 2 "ON" 3 "Invalid" ;
VAL_ 2424579841 DATC_HptIntnstySta 0 "Default" 1 "Haptic OFF" 2 "Haptic Intensity Level 1" 3 "Haptic Intensity Level 2" 4 "Haptic Intensity Level 3" 5 "Haptic Intensity Level 4" 6 "Haptic Intensity Level 5" 7 "Reserved" 8 "Reserved" 9 "Reserved" 10 "Reserved" 11 "Reserved" 12 "Reserved" 13 "Reserved" 14 "Reserved" 15 "Invalid" ;
VAL_ 1584 AMP_NaviWarnSound 0 "Navi Warning Off" 1 "Navi Warning On" 2 "Unused" 3 "Invalid" ;
VAL_ 1584 AMP_Beep1Mode 0 "Beep1 mode off" 1 "Beep1 mode On" 2 "Unsed" 3 "Invalid" ;
VAL_ 1584 AMP_MasterBeepVolumeStep 0 "level 0" 1 "level 1" 2 "level 2" 3 "level 3" 4 "level 4" 5 "level 5" 6 "Reserved" 7 "Invalid" ;
VAL_ 1584 AMP_SignalDoctor 0 "Signal Doctor OFF" 1 "Signal Doctor ON" 2 "Unused" 3 "Invalid" ;
VAL_ 1584 AMP_RrTTSSound 0 "RrTTS Off" 1 "RrTTS ON" 2 "Unused" 3 "Invalid" ;
VAL_ 1584 AMP_ASDMode 0 "Not use" 1 "ASD OFF" 2 "Reserved" 3 "ASD ON" 4 "Reserved" 5 "Reserved" 6 "Reserved" 7 "Invalid" ;
VAL_ 1584 AMP_ANCMode 0 "Not used" 1 "ANC Off" 2 "ANC On" 3 "Invalid" ;
VAL_ 1584 AMP_VirtualVenueMode 0 "Off" 1 "Livingroom" 2 "ConcertHall" 3 "Stadium" 4 "Reserved" 5 "Reserved" 6 "Reserved" 7 "Invalid" ;
VAL_ 1584 AMP_QLIMode 0 "Off" 1 "Reference" 2 "Audience" 3 "OnStage" 4 "Reserved" 5 "Reserved" 6 "Reserved" 7 "Invalid" ;
VAL_ 1584 AMP_DriverMode 0 "Off" 1 "On" 2 "Reserved" 3 "Invalid" ;
VAL_ 1584 AMP_NaviSound 0 "Navi Off" 1 "Navi ON" 2 "Unused" 3 "Invalid" ;
VAL_ 1584 AMP_VoiceGuideTTS 0 "Off" 1 "On" 2 "Reserved" 3 "Invalid" ;
VAL_ 1584 AMP_Beep1KBDMode 0 "Beep1 mode off" 1 "Beep1 mode On" 2 "Unsed" 3 "Invalid" ;
VAL_ 1584 AMP_NaviWarnVolumeStep 0 "0x0x0~0xFD:Navi Warning Volume" 253 "0x0x0~0xFD:Navi Warning Volume" 254 "Req. amp supported Navi Set" 255 "Invalid" ;
VAL_ 1584 AMP_TTSSound 0 "TTS Off" 1 "TTS ON" 2 "Unused" 3 "Invalid" ;
VAL_ 1584 AMP_SDVCStep 0 "off" 1 "low" 2 "mid" 3 "high" 7 "Invalid" ;
VAL_ 577 C_AstBolsterInfSw_HU 0 "Default" 1 "Off" 2 "On" 3 "Invalid" ;
VAL_ 577 C_RLHrestUpSw_HU 0 "Default" 1 "Off" 2 "On" 3 "Invalid" ;
VAL_ 577 C_RLHrestDnSw_HU 0 "Default" 1 "Off" 2 "On" 3 "Invalid" ;
VAL_ 577 C_RLHrestFwdSw_HU 0 "Default" 1 "Off" 2 "On" 3 "Invalid" ;
VAL_ 577 C_AstBolsterDefSw_HU 0 "Default" 1 "Off" 2 "On" 3 "Invalid" ;
VAL_ 577 C_RLHrestBwdSw_HU 0 "Default" 1 "Off" 2 "On" 3 "Invalid" ;
VAL_ 577 C_RLLumbarUpSw_HU 0 "Default" 1 "Off" 2 "On" 3 "Invalid" ;
VAL_ 577 C_RLLumbarMidSw_HU 0 "Default" 1 "Off" 2 "On" 3 "Invalid" ;
VAL_ 577 C_RLLumbarLowSw_HU 0 "Default" 1 "Off" 2 "On" 3 "Invalid" ;
VAL_ 577 C_RLLumbarDefSw_HU 0 "Default" 1 "Off" 2 "On" 3 "Invalid" ;
VAL_ 577 C_RLBolsterInfSw_HU 0 "Default" 1 "Off" 2 "On" 3 "Invalid" ;
VAL_ 577 C_RLBolsterDefSw_HU 0 "Default" 1 "Off" 2 "On" 3 "Invalid" ;
VAL_ 577 C_AstHrestUpSw_HU 0 "Default" 1 "Off" 2 "On" 3 "Invalid" ;
VAL_ 577 C_AstHrestDnSw_HU 0 "Default" 1 "Off" 2 "On" 3 "Invalid" ;
VAL_ 577 C_AstFootrestFldSw_HU 0 "Default" 1 "Off" 2 "On" 3 "Invalid" ;
VAL_ 577 C_AstHrestFwdSw_HU 0 "Default" 1 "Off" 2 "On" 3 "Invalid" ;
VAL_ 577 C_AstHrestBwdSw_HU 0 "Default" 1 "Off" 2 "On" 3 "Invalid" ;
VAL_ 577 C_AstFootrestUnFldSw_HU 0 "Default" 1 "Off" 2 "On" 3 "Invalid" ;
VAL_ 578 C_RRLegSupFwdSw_HU 0 "Default" 1 "Off" 2 "On" 3 "Invalid" ;
VAL_ 578 C_RRHrestDnSw_HU 0 "Default" 1 "Off" 2 "On" 3 "Invalid" ;
VAL_ 578 C_RRHrestFwdSw_HU 0 "Default" 1 "Off" 2 "On" 3 "Invalid" ;
VAL_ 578 C_RRHrestBwdSw_HU 0 "Default" 1 "Off" 2 "On" 3 "Invalid" ;
VAL_ 578 C_RRLumbarUpSw_HU 0 "Default" 1 "Off" 2 "On" 3 "Invalid" ;
VAL_ 578 C_RRLumbarMidSw_HU 0 "Default" 1 "Off" 2 "On" 3 "Invalid" ;
VAL_ 578 C_RRLegSupBwdSw_HU 0 "Default" 1 "Off" 2 "On" 3 "Invalid" ;
VAL_ 578 C_RRLumbarLowSw_HU 0 "Default" 1 "Off" 2 "On" 3 "Invalid" ;
VAL_ 578 C_RRLumbarDefSw_HU 0 "Default" 1 "Off" 2 "On" 3 "Invalid" ;
VAL_ 578 C_RRBolsterInfSw_HU 0 "Default" 1 "Off" 2 "On" 3 "Invalid" ;
VAL_ 578 C_RRLegSupUpSw_HU 0 "Default" 1 "Off" 2 "On" 3 "Invalid" ;
VAL_ 578 C_RROneTchNValueSet 0 "Default" 1 "Off" 2 "Return" 3 "Relax" 4 "AV" 5 "Read" 6 "Reserved" 7 "Invalid" ;
VAL_ 578 C_RLOneTchNValueSet 0 "Default" 1 "Off" 2 "Return" 3 "Relax" 4 "Reserved" 5 "Reserved" 6 "Reserved" 7 "Invalid" ;
VAL_ 578 C_RRBolsterDefSw_HU 0 "Default" 1 "Off" 2 "On" 3 "Invalid" ;
VAL_ 578 C_AstRlxTiltUpSw_HU 0 "Default" 1 "Off" 2 "On" 3 "Invalid" ;
VAL_ 578 C_AstRlxTiltDnSw_HU 0 "Default" 1 "Off" 2 "On" 3 "Invalid" ;
VAL_ 578 C_RLRSEUpSw_HU 0 "Default" 1 "Off" 2 "On" 3 "Invalid" ;
VAL_ 578 C_RLRSEDnSw_HU 0 "Default" 1 "Off" 2 "On" 3 "Invalid" ;
VAL_ 578 C_RRRSEUpSw_HU 0 "Default" 1 "Off" 2 "On" 3 "Invalid" ;
VAL_ 578 C_RRLegSupDnSw_HU 0 "Default" 1 "Off" 2 "On" 3 "Invalid" ;
VAL_ 578 C_RRRSEDnSw_HU 0 "Default" 1 "Off" 2 "On" 3 "Invalid" ;
VAL_ 578 C_RRHrestUpSw_HU 0 "Default" 1 "Off" 2 "On" 3 "Invalid" ;
VAL_ 2281833729 DMIC_DrvModSta 0 "Individual" 1 "Snow" 2 "Comfort(Normal)" 3 "Comfort+(Comfort)" 4 "ECO" 5 "Sport" 6 "Sport+" 7 "Smart" 8 "VIP" 9 "Baby" 10 "GT" 11 "Not Used" 12 "Not Used" 13 "Not Used" 14 "Not Used" 15 "Error Indicator" ;
VAL_ 2281833729 DMIC_SmtShftModSta 0 "OFF" 1 "ON" 2 "Not used" 3 "Error Indicator" ;
VAL_ 2281833729 DMIC_EngModSta 0 "0FF" 1 "ON" 2 "Comfort(Normal)" 3 "Comfort+(Comfort)" 4 "ECO" 5 "Sport" 6 "Sport+" 7 "Smart" 8 "VIP" 9 "Baby" 10 "Snow" 11 "Retro" 12 "Not used" 13 "Not used" 14 "Not used" 15 "Error Indicator" ;
VAL_ 2281833729 DMIC_IndEngModSta 0 "0FF" 1 "ON" 2 "Comfort(Normal)" 3 "Comfort+(Comfort)" 4 "ECO" 5 "Sport" 6 "Sport+" 7 "Smart" 8 "VIP" 9 "Not used" 10 "Not used" 11 "Not used" 12 "Not used" 13 "Not used" 14 "Not used" 15 "Error Indicator" ;
VAL_ 2281833729 DMIC_TmModSta 0 "0FF" 1 "ON" 2 "Comfort(Normal)" 3 "Comfort+(Comfort)" 4 "ECO" 5 "Sport" 6 "Sport+" 7 "Smart" 8 "VIP" 9 "Baby" 10 "Snow" 11 "Retro" 12 "Not used" 13 "Not used" 14 "Not used" 15 "Error Indicator" ;
VAL_ 2281833729 DMIC_IndTmModSta 0 "0FF" 1 "ON" 2 "Comfort(Normal)" 3 "Comfort+(Comfort)" 4 "ECO" 5 "Sport" 6 "Sport+" 7 "Smart" 8 "VIP" 9 "Not used" 10 "Not used" 11 "Not used" 12 "Not used" 13 "Not used" 14 "Not used" 15 "Error Indicator" ;
VAL_ 2281833729 DMIC_EscModSta 0 "0FF" 1 "ON" 2 "Comfort(Normal)" 3 "Comfort+(Comfort)" 4 "ECO" 5 "Sport" 6 "Sport+" 7 "Smart" 8 "VIP" 9 "Baby" 10 "Snow" 11 "Retro" 12 "Not used" 13 "Not used" 15 "Error Indicator" ;
VAL_ 2281833729 DMIC_IndEscModSta 0 "0FF" 1 "ON" 2 "Comfort(Normal)" 3 "Comfort+(Comfort)" 4 "ECO" 5 "Sport" 6 "Sport+" 7 "Smart" 8 "Not used" 9 "Not used" 10 "Not used" 11 "Not used" 12 "Not used" 13 "Not used" 14 "Not used" 15 "Error Indicator" ;
VAL_ 2281833729 DMIC_MdpsModSta 0 "0FF" 1 "ON" 2 "Comfort(Normal)" 3 "Comfort+(Comfort)" 4 "ECO" 5 "Sport" 6 "Sport+" 7 "Smart" 8 "VIP" 9 "Baby" 10 "Snow" 11 "Retro" 12 "Not used" 13 "Not used" 14 "Not used" 15 "Error Indicator" ;
VAL_ 2281833729 DMIC_IndMdpsModSta 0 "0FF" 1 "ON" 2 "Comfort(Normal)" 3 "Comfort+(Comfort)" 4 "ECO" 5 "Sport" 6 "Sport+" 7 "Smart" 8 "VIP" 9 "Not used" 10 "Not used" 11 "Not used" 12 "Not used" 13 "Not used" 14 "Not used" 15 "Error Indicator" ;
VAL_ 2281833730 DMIC_EcsModSta 0 "0FF" 1 "ON" 2 "Comfort(Normal)" 3 "Comfort+(Comfort)" 4 "ECO" 5 "Sport" 6 "Sport+" 7 "Smart" 8 "VIP" 9 "Baby" 10 "Snow" 11 "Retro" 12 "Not used" 13 "Not used" 14 "Not used" 15 "Error Indicator" ;
VAL_ 2281833730 DMIC_IndAwdModSta 0 "0FF" 1 "ON" 2 "Comfort(Normal)" 3 "Comfort+(Comfort)" 4 "ECO" 5 "Sport" 6 "Sport+" 7 "Smart" 8 "Not used" 9 "Not used" 10 "Not used" 11 "Not used" 12 "Not used" 13 "Not used" 14 "Not used" 15 "Error Indicator" ;
VAL_ 2281833730 DMIC_RevModSta 0 "0FF" 1 "ON" 2 "Comfort(Normal)" 3 "Comfort+(Comfort)" 4 "ECO" 5 "Sport" 6 "Sport+" 7 "Smart" 8 "VIP" 9 "Baby" 10 "Snow" 11 "Retro" 12 "Not used" 13 "Not used" 14 "Not used" 15 "Error Indicator" ;
VAL_ 2281833730 DMIC_IndRevModSta 0 "0FF" 1 "ON" 2 "Comfort(Normal)" 3 "Comfort+(Comfort)" 4 "ECO" 5 "Sport" 6 "Sport+" 7 "Smart" 8 "Not used" 9 "Not used" 10 "Not used" 11 "Not used" 12 "Not used" 13 "Not used" 14 "Not used" 15 "Error Indicator" ;
VAL_ 2281833730 DMIC_PrflModSta 0 "ON-OFF" 1 "ON-ON" 2 "OFF-OFF" 3 "OFF-ON" 4 "Not used" 5 "Not used" 6 "Not used" 7 "Not used" 8 "Not used" 9 "Not used" 10 "Not used" 11 "Not used" 12 "Not used" 13 "Not used" 14 "Not used" 15 "Error Indicator" ;
VAL_ 2281833730 DMIC_IndPrflModSta 0 "OFF" 1 "ON" 2 "Not used" 3 "Not used" 4 "Not used" 5 "Not used" 6 "Not used" 7 "Not used" 8 "Not used" 9 "Not used" 10 "Not used" 11 "Not used" 12 "Not used" 13 "Not used" 14 "Not used" 15 "Error Indicator" ;
VAL_ 2281833730 DMIC_ElsdModSta 0 "0FF" 1 "ON" 2 "Comfort(Normal)" 3 "Comfort+(Comfort)" 4 "ECO" 5 "Sport" 6 "Sport+" 7 "Smart" 8 "VIP" 9 "Baby" 10 "Snow" 11 "Retro" 12 "Not used" 13 "Not used" 14 "Not used" 15 "Error Indicator" ;
VAL_ 2281833730 DMIC_IndElsdModSta 0 "0FF" 1 "ON" 2 "Comfort(Normal)" 3 "Comfort+(Comfort)" 4 "ECO" 5 "Sport" 6 "Sport+" 7 "Smart" 8 "Not used" 9 "Not used" 10 "Not used" 11 "Not used" 12 "Not used" 13 "Not used" 14 "Not used" 15 "Error Indicator" ;
VAL_ 2281833730 DMIC_IndEcsModSta 0 "0FF" 1 "ON" 2 "Comfort(Normal)" 3 "Comfort+(Comfort)" 4 "ECO" 5 "Sport" 6 "Sport+" 7 "Smart" 8 "VIP" 9 "Not used" 10 "Not used" 11 "Not used" 12 "Not used" 13 "Not used" 14 "Not used" 15 "Error Indicator" ;
VAL_ 2281833730 DMIC_EsndModSta 0 "0FF" 1 "ON" 2 "Comfort(Normal)" 3 "Comfort+(Comfort)" 4 "ECO" 5 "Sport" 6 "Sport+" 7 "Smart" 8 "VIP" 9 "Baby" 10 "Snow" 11 "Retro" 12 "Not used" 13 "Not used" 14 "Not used" 15 "Error Indicator" ;
VAL_ 2281833730 DMIC_IndEsndModSta 0 "0FF" 1 "ON" 2 "Comfort(Normal)" 3 "Comfort+(Comfort)" 4 "ECO" 5 "Sport" 6 "Sport+" 7 "Smart" 8 "Not used" 9 "Not used" 10 "Not used" 11 "Not used" 12 "Not used" 13 "Not used" 14 "Not used" 15 "Error Indicator" ;
VAL_ 2281833730 DMIC_RwsModSta 0 "0FF" 1 "ON" 2 "Comfort(Normal)" 3 "Comfort+(Comfort)" 4 "ECO" 5 "Sport" 6 "Sport+" 7 "Smart" 8 "VIP" 9 "Baby" 10 "Snow" 11 "Retro" 12 "Not used" 13 "Not used" 14 "Not used" 15 "Error Indicator" ;
VAL_ 2281833730 DMIC_IndRwsModSta 0 "0FF" 1 "ON" 2 "Comfort(Normal)" 3 "Comfort+(Comfort)" 4 "ECO" 5 "Sport" 6 "Sport+" 7 "Smart" 8 "Not used" 9 "Not used" 10 "Not used" 11 "Not used" 12 "Not used" 13 "Not used" 14 "Not used" 15 "Error Indicator" ;
VAL_ 2281833730 DMIC_AwdModSta 0 "0FF" 1 "ON" 2 "Comfort(Normal)" 3 "Comfort+(Comfort)" 4 "ECO" 5 "Sport" 6 "Sport+" 7 "Smart" 8 "VIP" 9 "Baby" 10 "Snow" 11 "Retro" 12 "Not used" 13 "Not used" 14 "Not used" 15 "Error Indicator" ;
VAL_ 2281833731 DMIC_VcuModSta 0 "0FF" 1 "ON" 2 "Comfort(Normal)" 3 "Comfort+(Comfort)" 4 "ECO" 5 "Sport" 6 "Sport+" 7 "Smart" 8 "VIP" 9 "Baby" 10 "Snow" 11 "Retro" 12 "Not used" 13 "Not used" 14 "Not used" 15 "Error Indicator" ;
VAL_ 2281833731 DMIC_DrvModTyp 0 "Default" 1 "Drive Mode Case1" 2 "Drive Mode Case2" 3 "Drive Mode Case3" 4 "Drive Mode Case4" 5 "Drive Mode Case5" 6 "Drive Mode Case6" 7 "Drive Mode Case7" 8 "Drive Mode Case8" 9 "Drive Mode Case9" 10 "Drive Mode Case10" 11 "Drive Mode Case11" 12 "Drive Mode Case12" 13 "Drive Mode Case13" 14 "Drive Mode Case14" 15 "Invalid" ;
VAL_ 2281833731 DMIC_EngFltSta 0 "Not defective" 1 "Defective" 2 "Not used" 3 "Error Indicator" ;
VAL_ 2281833731 DMIC_TmFltSta 0 "Not defective" 1 "Defective" 2 "Not used" 3 "Error Indicator" ;
VAL_ 2281833731 DMIC_EscFltSta 0 "Not defective" 1 "Defective" 2 "Not used" 3 "Error Indicator" ;
VAL_ 2281833731 DMIC_MdpsFltSta 0 "Not defective" 1 "Defective" 2 "Not used" 3 "Error Indicator" ;
VAL_ 2281833731 DMIC_EcsFltSta 0 "Not defective" 1 "Defective" 2 "Not used" 3 "Error Indicator" ;
VAL_ 2281833731 DMIC_AwdFltSta 0 "Not defective" 1 "Defective" 2 "Not used" 3 "Error Indicator" ;
VAL_ 2281833731 DMIC_RevFltSta 0 "Not defective" 1 "Defective" 2 "Not used" 3 "Error Indicator" ;
VAL_ 2281833731 DMIC_PrflFltSta 0 "Not defective" 1 "Defective" 2 "Not used" 3 "Error Indicator" ;
VAL_ 2281833731 DMIC_ElsdFltSta 0 "Not defective" 1 "Defective" 2 "Not used" 3 "Error Indicator" ;
VAL_ 2281833731 DMIC_EsndFltSta 0 "Not defective" 1 "Defective" 2 "Not used" 3 "Error Indicator" ;
VAL_ 2281833731 DMIC_RwsFltSta 0 "Not defective" 1 "Defective" 2 "Not used" 3 "Error Indicator" ;
VAL_ 2281833731 DMIC_IndWhlDrvSta 0 "Not used" 1 "AUTO" 2 "2WD" 3 "4WD" ;
VAL_ 2281833731 DMIC_IndVcuModSta 0 "0FF" 1 "ON" 2 "Comfort(Normal)" 3 "Comfort+(Comfort)" 4 "ECO" 5 "Sport" 6 "Sport+" 7 "Smart" 8 "VIP" 9 "Not used" 10 "Not used" 11 "Not used" 12 "Not used" 13 "Not used" 14 "Not used" 15 "Error Indicator" ;
VAL_ 2281833731 DMIC_VcuFltSta 0 "Not defective" 1 "Defective" 2 "Not used" 3 "Error Indicator" ;
VAL_ 2281833731 DMIC_IndMtrPwrSta 0 "Not used" 1 "Step 1" 2 "Step 2" 3 "Step 3" 4 "Step 4" 5 "Step 5" 6 "Step 6" 7 "Step 7" ;
VAL_ 2281833731 DMIC_IndAccSenSta 0 "Not used" 1 "Step 1" 2 "Step 2" 3 "Step 3" 4 "Step 4" 5 "Step 5" 6 "Step 6" 7 "Step 7" ;
VAL_ 2281833731 DMIC_IndDecSenSta 0 "Not used" 1 "Step 1" 2 "Step 2" 3 "Step 3" 4 "Step 4" 5 "Step 5" 6 "Step 6" 7 "Step 7" ;
VAL_ 2281833731 DMIC_IndMaxVehSpdSta 0 "Not used" 1 "30" 2 "35" 3 "40" 4 "45" 5 "50" 6 "55" 7 "60" 8 "65" 9 "70" 10 "75" 11 "80" 12 "85" 13 "90" 14 "95" 15 "100" 16 "105" 17 "110" 18 "115" 19 "120" 20 "125" 21 "130" 22 "135" 23 "140" 24 "145" 25 "150" 26 "155" 27 "160" 28 "165" 29 "170" 30 "175" 31 "180" 32 "185" 33 "190" 34 "195" 35 "200" 36 "Reserved" 37 "Reserved" 38 "Reserved" 39 "Reserved" 40 "Reserved" 41 "Reserved" 42 "Reserved" 43 "Reserved" 44 "Reserved" 45 "Reserved" 46 "Reserved" 47 "Reserved" 48 "Reserved" 49 "Reserved" 50 "Reserved" 51 "Reserved" 52 "Reserved" 53 "Reserved" 54 "Reserved" 55 "Reserved" 56 "Reserved" 57 "Reserved" 58 "Reserved" 59 "Reserved" 60 "Reserved" 61 "Reserved" 62 "Reserved" 63 "Reserved" ;
VAL_ 2281833731 DMIC_DrvMod2Typ 0 "Default" 1 "Drive Mode Case1" 2 "Drive Mode Case2" 3 "Drive Mode Case3" 4 "Drive Mode Case4" 5 "Drive Mode Case5" 6 "Drive Mode Case6" 7 "Drive Mode Case7" 8 "Drive Mode Case8" 9 "Drive Mode Case9" 10 "Drive Mode Case10" 11 "Drive Mode Case11" 12 "Drive Mode Case12" 13 "Drive Mode Case13" 14 "Drive Mode Case14" 15 "Invalid" ;
VAL_ 2281833731 DMIC_DrvModFltSta 0 "All mode available" 1 "Sport mode unavailable" 2 "ECO mode and Sport mode unavailable" 3 "Comfort(Normal) mode only available (The other modes unavailable)" 4 "Not used" 5 "Not used" 6 "Not used" 7 "Not used" 8 "Not used" 9 "Not used" 10 "Not used" 11 "Not used" 12 "Not used" 13 "Not used" 14 "Not used" 15 "Error Indicator" ;
VAL_ 1041 ICU_MtGearPosRSta 0 "Off" 1 "On" 2 "RESERVED" 3 "RESERVED" ;
VAL_ 1041 DoorLock_AsstDrUnLkSta 0 "Lock" 1 "Unlock" 2 "Not Used" 3 "Error Indicator" ;
VAL_ 1041 Warn_DrvDrSwSta 0 "Close" 1 "Open" 2 "Not Used" 3 "Error Indicator" ;
VAL_ 1041 DoorLock_DrvKeyUnLkSwSta 0 "Off" 1 "Unlock" 2 "Not Used" 3 "Error Indicator" ;
VAL_ 1041 DoorLock_RrLftDrUnLkSta 0 "Lock" 1 "Unlock" 2 "Not Used" 3 "Error Indicator" ;
VAL_ 1041 DoorLock_RrRtDrUnLkSta 0 "Lock" 1 "Unlock" 2 "Not Used" 3 "Error Indicator" ;
VAL_ 1041 Warn_AsstDrSwSta 0 "Close" 1 "Open" 2 "Not Used" 3 "Error Indicator" ;
VAL_ 1041 Warn_AsstStBltSwSta 0 "Unbelted" 1 "Belted" 2 "Not Used" 3 "Error Indicator" ;
VAL_ 1041 Warn_BrkFldSwSta 0 "Off" 1 "On" 2 "Not Used" 3 "Error Indicator" ;
VAL_ 1041 DoorLock_DrvKeyLkSwSta 0 "Off" 1 "Lock" 2 "Not Used" 3 "Error Indicator" ;
VAL_ 1041 Warn_DrvStBltSwSta 0 "Unbelted" 1 "Belted" 2 "Not Used" 3 "Error Indicator" ;
VAL_ 1041 Warn_HoodSwSta 0 "Off" 1 "On" 2 "Not Used" 3 "Error Indicator" ;
VAL_ 1041 Warn_PassStOccSta 0 "Off (UnSeated)" 1 "On (Seated)" 2 "Not Used" 3 "Error Indicator" ;
VAL_ 1041 Warn_PrkngBrkSwSta 0 "Off" 1 "On" 2 "Not Used" 3 "Error Indicator" ;
VAL_ 1041 Warn_RrCtrStBltSwSta 0 "Unbelted" 1 "Belted" 2 "Not Used" 3 "Error Indicator" ;
VAL_ 1041 Warn_RrLftDrSwSta 0 "Close" 1 "Open" 2 "Not Used" 3 "Error Indicator" ;
VAL_ 1041 Warn_RrLftStBltSwSta 0 "Unbelted" 1 "Belted" 2 "Not Used" 3 "Error Indicator" ;
VAL_ 1041 Warn_RrRtDrSwSta 0 "Close" 1 "Open" 2 "Not Used" 3 "Error Indicator" ;
VAL_ 1041 Warn_RrRtStBltSwSta 0 "Unbelted" 1 "Belted" 2 "Not Used" 3 "Error Indicator" ;
VAL_ 1041 Warn_HoodSwMemorySta 0 "No event" 1 "hood_open_close" 2 "reserved" 3 "reserved" ;
VAL_ 1041 Warn_WshrFldSwSta 0 "Off" 1 "On" 2 "RESERVED" 3 "RESERVED" ;
VAL_ 1041 ICU_Haptic_OPT 0 "Default" 1 "No option(None Haptic Option)" 2 "Option" 3 "Invalid" ;
VAL_ 1043 Lamp_TrnSigLmpRtActiveSt 0 "Off (Inactive)" 1 "On (Active)" 2 "Reserved" 3 "Invalid" ;
VAL_ 1043 ExtLamp_HzrdSwSta 0 "Off" 1 "On" 2 "Not Used" 3 "Error Indicator" ;
VAL_ 1043 IntLamp_InlTailLmpSta 0 "Off" 1 "On" 2 "Not Used" 3 "Error Indicator" ;
VAL_ 1043 Lamp_LedHdLmpSta 0 "LED Headlamp is in nornal condition" 1 "Reserved" 2 "LED Fail" 3 "Reserved" ;
VAL_ 1043 TrnLmpSeqEnblCmd 0 "Off" 1 "On" 2 "Reserved" 3 "Reserved" ;
VAL_ 1043 Lamp_TrnSigLmpLftOnReq 0 "Inactive" 1 "Active Off(Flasher Off)" 2 "Active On(Flasher On)" 3 "reserved" ;
VAL_ 1043 Lamp_TrnSigLmpRtOnReq 0 "Inactive" 1 "Active Off(Flasher Off)" 2 "Active On(Flasher On)" 3 "reserved" ;
VAL_ 1043 Lamp_TrnSigLmpLftActiveSt 0 "Off (Inactive)" 1 "On (Active)" 2 "Reserved" 3 "Invalid" ;
VAL_ 1044 Trunk_TrnkInReleaseSwSta 0 "Off" 1 "On" 2 "Not Used" 3 "Error Indicator" ;
VAL_ 1044 Trunk_TrnkTlgtOutReleaseSwSta 0 "Off" 1 "On" 2 "Not Used" 3 "Error Indicator" ;
VAL_ 1044 Trunk_TrnkTlgtSwSta 0 "Close(Full Lock)" 1 "Open(Not Full Lock)" 2 "Not Used" 3 "Error Indicator" ;
VAL_ 1044 Trunk_GlvBxTrnkLkSwSta 0 "Off" 1 "On" 2 "Not Used" 3 "Error Indicator" ;
VAL_ 1044 Trunk_TlgtFullOpnSwSta 0 "Close(Not Full Open)" 1 "Open(Full Open)" 2 "Not Used" 3 "Error Indicator" ;
VAL_ 1044 Trunk_TrnkTlgtReleaseRlySta 0 "OFF" 1 "ON" 2 "Not Used" 3 "Error Indicator" ;
VAL_ 1044 USM_OneTouchTrnSigFuncSta 0 "Default" 1 "One Touch Turn Off" 2 "3 Flashing" 3 "5 Flashing" 4 "7 Flashing" 5 "Invalid" 6 "RESERVED" 7 "RESERVED" ;
VAL_ 1044 DoorLock_DrvDrUnLkSta 0 "Lock" 1 "Unlock" 2 "Not Used" 3 "Error Indicator" ;
VAL_ 1044 DoorLock_LkOutSta 0 "Off" 1 "On" 2 "Not Used" 3 "Error Indicator" ;
VAL_ 1044 C_CrashUnlockState 0 "Off" 1 "Unlock(Crash)" 2 "RESERVED" 3 "RESERVED" ;
VAL_ 1044 C_AutoLeverManualSW 0 "Not Manual" 1 "Manual" 2 "Manual +" 3 "Manual -" ;
VAL_ 579 OHCL_Opt 0 "None option" 1 "Enable" ;
VAL_ 579 OHCL_Sys_sta 0 "Normal" 1 "Not Used" 2 "Not Used" 3 "System Fail" ;
VAL_ 579 OHCL_DoorOn_Sta 0 "Off" 1 "On" 2 "Not Used" 3 "System Fail" ;
VAL_ 579 OHCL_RrMapLftOn_Sta 0 "Off" 1 "On" 2 "Not Used" 3 "System Fail" ;
VAL_ 579 OHCL_RrMapRtOn_Sta 0 "Off" 1 "On" 2 "Not Used" 3 "System Fail" ;
VAL_ 579 OHCL_RrRoomOn_Sta 0 "Off" 1 "On" 2 "Not Used" 3 "System Fail" ;
VAL_ 579 OHCL_RrMoodOn_Sta 0 "Off" 1 "On" 2 "Not Used" 3 "System Fail" ;
VAL_ 579 OHCL_LEDClr_Sta 0 "Color 1Step" 1 "Color 2Step" 2 "Color 3Step" 3 "Not Used" 4 "Not Used" 5 "Not Used" 6 "Not Used" 7 "System Fail" ;
VAL_ 579 OHCL_LEDBgtns_Sta 0 "Brightness 1Step" 1 "Brightness 2Step" 2 "Brightness 3Step" 3 "Not Used" 4 "Not Used" 5 "Not Used" 6 "Not Used" 7 "System Fail" ;
VAL_ 579 OHCL_TllTlLmpSta 0 "ON Lamp off OFF Lamp off" 1 "ON Lamp off OFF Lamp on" 2 "ON Lamp on OFF Lamp off" 3 "ON Lamp on OFF Lamp on" 4 "ACU message error" 5 "Not Supported" 6 "Reserved" 7 "Lamp circuit failure" ;
VAL_ 579 OHCL_FrMapLftOn_Sta 0 "Off" 1 "On" 2 "Not Used" 3 "System Fail" ;
VAL_ 579 OHCL_RrCurtainReq 0 "Off" 1 "On" 2 "NotUsed" 3 "ErrorIndicator" ;
VAL_ 579 OHCL_FrMapRtOn_Sta 0 "Off" 1 "On" 2 "Not Used" 3 "System Fail" ;
VAL_ 579 OHCL_FrRoomOn_Sta 0 "Off" 1 "On" 2 "Not Used" 3 "System Fail" ;
VAL_ 579 OHCL_FrMoodOn_Sta 0 "Off" 1 "On" 2 "Not Used" 3 "System Fail" ;
VAL_ 1068 RLPSU_ReclMtrPos 0 "Default" 1 "Zone1" 2 "Zone2" 3 "Zone3" 4 "Zone4" 5 "PE" 6 "RESERVED" 7 "Invalid" ;
VAL_ 1068 RLPSU_RLSlidPos 0 "Default" 1 "Front Ended Position" 2 "Operating Enable" 3 "Rear Ended Position" 4 "RESERVED" 5 "RESERVED" 6 "RESERVED" 7 "Invalid" ;
VAL_ 1068 RLPSU_RLRclPos 0 "Default" 1 "Front Ended Position" 2 "Operating Enable" 3 "Rear Ended Position" 4 "RESERVED" 5 "RESERVED" 6 "RESERVED" 7 "Invalid" ;
VAL_ 1068 RLPSU_RLTiltPos 0 "Default" 1 "Upper Ended Position" 2 "Operating Enable" 3 "Lower Ended Position" 4 "RESERVED" 5 "RESERVED" 6 "RESERVED" 7 "Invalid" ;
VAL_ 1068 RLPSU_RLLegExtPos 0 "Default" 1 "Front Ended Position" 2 "Operating Enable" 3 "Rear Ended Position" 4 "RESERVED" 5 "RESERVED" 6 "RESERVED" 7 "Invalid" ;
VAL_ 1068 RLPSU_RLLegSupPos 0 "Default" 1 "Upper Ended Position" 2 "Operating Enable" 3 "Lower Ended Position" 4 "RESERVED" 5 "RESERVED" 6 "RESERVED" 7 "Invalid" ;
VAL_ 1068 RLPSU_RLHrestSlidPos 0 "Default" 1 "Front Ended Position" 2 "Operating Enable" 3 "RearEndedPosition" 4 "RESERVED" 5 "RESERVED" 6 "RESERVED" 7 "Invalid" ;
VAL_ 1068 RLPSU_RLHrestHeightPos 0 "Default" 1 "Upper Ended Position" 2 "Operating Enable" 3 "Lower  Ended Position" 4 "RESERVED" 5 "RESERVED" 6 "RESERVED" 7 "Invalid" ;
VAL_ 1068 RLPSU_Opt 0 "Default" 1 "PWR&HVU(5P Slide)" 2 "PWR&HVU(7P Walkin)" 3 "Invalid" ;
VAL_ 1068 RLPSU_Opt_Captain 0 "Default" 1 "PWR&HVU(4P Slide)" 2 "PWR&HVU(6P Walkin)" 3 "Invalid" ;
VAL_ 1068 RL_AutoRlxSta 0 "Default" 1 "Auto Relaxion Moving" 2 "Reserved" 3 "Invalid" ;
VAL_ 1068 RL_FLStAutoRlxEnable 0 "Default" 1 "Enable" 2 "Disable" 3 "Invalid" ;
VAL_ 1068 RLHVU_Opt_Captain 0 "Default" 1 "MNL&HU(4P Slide)" 2 "MNL&HU(6P Walkin)" 3 "MNL&HVU(4P Slide)" 4 "MNL&HVU(6P Walkin)" 5 "RESERVED" 6 "RESERVED" 7 "Invalid" ;
VAL_ 1068 RLPSU_PwrSeatOpt 0 "Default" 1 "5P" 2 "5P + SHVU" 3 "7P" 4 "7P + SHVU" 5 "9P" 6 "9P + SHVU" 7 "Invalid" ;
VAL_ 1068 RLPSU_PwrSeatPos 0 "Default" 1 "Front Ended Position" 2 "Moving Forward" 3 "Moving Backward" 4 "Rear Ended Position" 5 "RESERVED" 6 "RESERVED" 7 "Invalid" ;
VAL_ 1070 RL_SHVU_HtSwHiIndSta 0 "OFF" 1 "ON" 2 "RESERVED" 3 "Error Indicator" ;
VAL_ 1070 RL_SHVU_HtSwMidIndSta 0 "OFF" 1 "ON" 2 "RESERVED" 3 "Error Indicator" ;
VAL_ 1070 RL_SHVU_HtSwLowIndSta 0 "OFF" 1 "ON" 2 "RESERVED" 3 "Error Indicator" ;
VAL_ 1070 RL_SHVU_VntSwHiIndSta 0 "OFF" 1 "ON" 2 "RESERVED" 3 "Error Indicator" ;
VAL_ 1070 RL_SHVU_VntSwMidIndSta 0 "OFF" 1 "ON" 2 "RESERVED" 3 "Error Indicator" ;
VAL_ 1070 RL_SHVU_VntSwLowIndSta 0 "OFF" 1 "ON" 2 "RESERVED" 3 "Error Indicator" ;
VAL_ 1070 RL_SHVU_HtBlcUsmSta 0 "Default" 1 "Normal" 2 "Back 1" 3 "Back 2" 4 "Back 3" 5 "Cush 1" 6 "Cush 2" 7 "Cush 3" 8 "RESERVED" 9 "RESERVED" 10 "RESERVED" 11 "RESERVED" 12 "RESERVED" 13 "RESERVED" 14 "RESERVED" 15 "Invalid" ;
VAL_ 1069 RRPSU_ReclMtrPos 0 "Default" 1 "Zone1" 2 "Zone2" 3 "Zone3" 4 "Zone4" 5 "PE" 6 "Unused" 7 "Invalid" ;
VAL_ 1069 RRPSU_PwrSeatOpt 0 "Default" 1 "5P" 2 "5P + SHVU" 3 "7P" 4 "7P + SHVU" 5 "9P" 6 "9P + SHVU" 7 "Invalid" ;
VAL_ 1069 RRPSU_PwrSeatPos 0 "Default" 1 "Front Ended Position" 2 "Moving Forward" 3 "Moving Backward" 4 "Rear Ended Position" 5 "Unused" 6 "Unused" 7 "Invalid" ;
VAL_ 1069 RRPSU_RRSlidPos 0 "Default" 1 "Front Ended Position" 2 "Operating Enable" 3 "Rear Ended Position" 4 "Unused" 5 "Unused" 6 "Unused" 7 "Invalid" ;
VAL_ 1069 RRPSU_RRRclPos 0 "Default" 1 "Front Ended Position" 2 "Operating Enable" 3 "Rear Ended Position" 4 "Unused" 5 "Unused" 6 "Unused" 7 "Invalid" ;
VAL_ 1069 RRPSU_RRTiltPos 0 "Default" 1 "Upper Ended Position" 2 "Operating Enable" 3 "Lower Ended Position" 4 "Unused" 5 "Unused" 6 "Unused" 7 "Invalid" ;
VAL_ 1069 RRPSU_RRLegExtPos 0 "Default" 1 "Front Ended Position" 2 "Operating Enable" 3 "Rear Ended Position" 4 "Unused" 5 "Unused" 6 "Unused" 7 "Invalid" ;
VAL_ 1069 RRPSU_RRLegSupPos 0 "Default" 1 "Upper Ended Position" 2 "Operating Enable" 3 "Lower Ended Position" 4 "Unused" 5 "Unused" 6 "Unused" 7 "Invalid" ;
VAL_ 1069 RRPSU_RRStEsyAcsUSMSta 0 "Default" 1 "Off(Disable)" 2 "On(Enable)" 3 "Reserved" 4 "Reserved" 5 "Reserved" 6 "Reserved" 7 "Invalid" ;
VAL_ 1069 RRPSU_RRHrestSlidPos 0 "Default" 1 "Front Ended Position" 2 "Operating Enable" 3 "Rear Ended Position" 4 "Unused" 5 "Unused" 6 "Unused" 7 "Invalid" ;
VAL_ 1069 RRPSU_RRHrestHeightPos 0 "Default" 1 "Up Ended Position" 2 "Operating Enable" 3 "Down Ended Position" 4 "" 5 "" 6 "" 7 "Invalid" ;
VAL_ 1069 RRPSU_Opt_Captain 0 "Default" 1 "PWR&HVU(4P Slide)" 2 "PWR&HVU(6P Walkin)" 3 "Invalid" ;
VAL_ 1069 RR_AutoRlxSta 0 "Default" 1 "Auto Relaxtion Moving" 2 "Reserved" 3 "Invalid" ;
VAL_ 1069 RR_FRStAutoRlxEnable 0 "Default" 1 "Enable" 2 "Disable" 3 "Invalid" ;
VAL_ 1069 RRHVU_Opt_Captain 0 "Default" 1 "MNL&HU(4P Slide)" 2 "MNL&HU(6P Walkin)" 3 "MNL&HVU(4P Slide)" 4 "MNL&HVU(6P Walkin)" 5 "RESERVED" 6 "RESERVED" 7 "Invalid" ;
VAL_ 1069 RRPSU_RLStEsyAcsUSMSta 0 "Default" 1 "Off(Disable)" 2 "On(Enable)" 3 "Reserved" 4 "Reserved" 5 "Reserved" 6 "Reserved" 7 "Invalid" ;
VAL_ 1069 RRPSU_Opt 0 "Default" 1 "PWR&HVU(5P Slide)" 2 "PWR&HVU(7P Walkin)" 3 "Invalid" ;
VAL_ 1071 RR_SHVU_HtSwHiIndSta 0 "OFF" 1 "ON" 2 "RESERVED" 3 "Error indicator" ;
VAL_ 1071 RR_SHVU_HtSwMidIndSta 0 "OFF" 1 "ON" 2 "RESERVED" 3 "Error Indicator" ;
VAL_ 1071 RR_SHVU_HtSwLowIndSta 0 "OFF" 1 "ON" 2 "RESERVED" 3 "Error Indicator" ;
VAL_ 1071 RR_SHVU_VntSwHiIndSta 0 "OFF" 1 "ON" 2 "RESERVED" 3 "Error Indictor" ;
VAL_ 1071 RR_SHVU_VntSwMidIndSta 0 "OFF" 1 "ON" 2 "RESERVED" 3 "Error Indicator" ;
VAL_ 1071 RR_SHVU_VntSwLowIndSta 0 "OFF" 1 "ON" 2 "RESERVED" 3 "Error Indicator" ;
VAL_ 1071 RR_SHVU_HtBlcUsmSta 0 "Default" 1 "Normal" 2 "Back 1" 3 "Back 2" 4 "Back 3" 5 "Cush 1" 6 "Cush 2" 7 "Cush 3" 8 "RESERVED" 9 "RESERVED" 10 "RESERVED" 11 "RESERVED" 12 "RESERVED" 13 "RESERVED" 14 "RESERVED" 15 "Invalid" ;
VAL_ 1067 SCM_SWVerMajor1 0 "0x0x0~0x7F:ASCII Code Value (HEX)" 127 "0x0x0~0x7F:ASCII Code Value (HEX)" ;
VAL_ 1067 SCM_SWVerMinor1 0 "0x0x0~0x7F:ASCII Code Value (HEX)" 127 "0x0x0~0x7F:ASCII Code Value (HEX)" ;
VAL_ 1067 SCM_SWVerMinor2 0 "0x0x0~0x7F:ASCII Code Value (HEX)" 127 "0x0x0~0x7F:ASCII Code Value (HEX)" ;
